VERSION "DNNBNNNYNNNNNNNNNNNNNNNNNNNNNNNNNNNNNNNNNN/4/%%%/4/'%**4NNN///"

NS_ :

BS_:

BU_: Vector__XXX SODX PC

BO_ 257 MBM_TARGET_DETECTION_HEADER: 8 SODX
 SG_ NumOfDetectionsTransmitted : 39|8@0+ (1,0) [0|99] ""  PC
 SG_ NumOfDetectionsInternal : 47|8@0+ (1,0) [0|127] ""  PC
 SG_ msg_count : 63|8@0+ (1,0) [0|0] ""  PC
 SG_ MCC : 7|32@0+ (1,0) [0|0] ""  PC
 SG_ InternalValue : 55|8@0+ (1,0) [0|0] ""  PC

BO_ 256 MB79_TARGET_DETECTION_TIME: 4 SODX
 SG_ TimeStamp : 7|32@0+ (1,0) [0|4294967295] "us"  PC

BO_ 293 MB79_TARGET_DETECTION_9D: 8 SODX
 SG_ Complex4_Re_9 : 39|16@0- (1,0) [-32768|32767] "n/a"  PC
 SG_ Complex4_Im_9 : 55|16@0- (1,0) [-32768|32767] "n/a"  PC
 SG_ Complex3_Re_9 : 7|16@0- (1,0) [-32768|32767] "n/a"  PC
 SG_ Complex3_Im_9 : 23|16@0- (1,0) [-32768|32767] "n/a"  PC

BO_ 292 MB79_TARGET_DETECTION_9C: 8 SODX
 SG_ Complex2_Re_9 : 39|16@0- (1,0) [-32768|32767] "n/a"  PC
 SG_ Complex2_Im_9 : 55|16@0- (1,0) [-32768|32767] "n/a"  PC
 SG_ Complex1_Re_9 : 7|16@0- (1,0) [-32768|32767] "n/a"  PC
 SG_ Complex1_Im_9 : 23|16@0- (1,0) [-32768|32767] "n/a"  PC

BO_ 291 MB79_TARGET_DETECTION_9B: 8 SODX
 SG_ StdAzimuth_9 : 63|8@0+ (0.0009766,0) [0|14.31] "°"  PC
 SG_ PowerDB_9 : 7|8@0+ (1,0) [0|255] "db"  PC
 SG_ CoGRange_9 : 15|16@0- (0.01,0) [0|96] "m"  PC
 SG_ CoGDoppler_9 : 31|16@0- (0.01,0) [-140|14] "m/s"  PC
 SG_ Azimuth_9 : 47|16@0- (0.1,0) [-180|180] "°"  PC

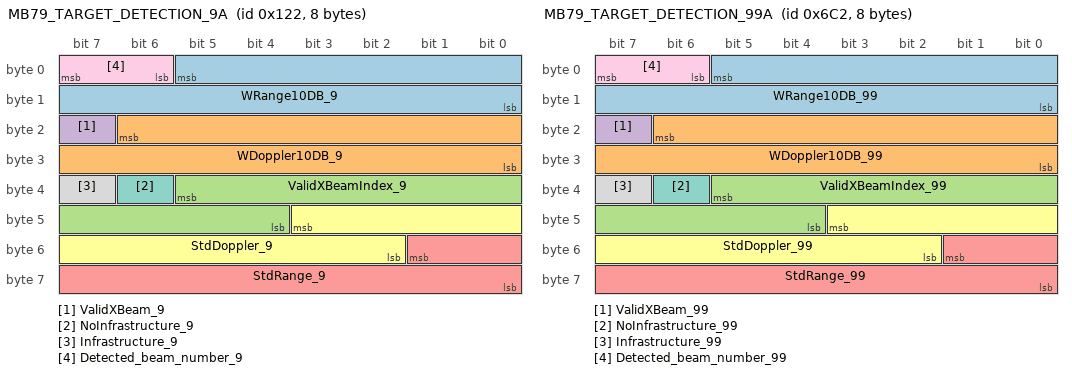
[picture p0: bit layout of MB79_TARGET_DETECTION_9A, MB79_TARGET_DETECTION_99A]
BO_ 290 MB79_TARGET_DETECTION_9A: 8 SODX
 SG_ WRange10DB_9 : 5|14@0+ (0.01,0) [0|96] "m"  PC
 SG_ WDoppler10DB_9 : 22|15@0+ (0.01,0) [0|280] "m/s"  PC
 SG_ ValidXBeamIndex_9 : 37|10@0+ (1,0) [0|0] "n/a"  PC
 SG_ ValidXBeam_9 : 23|1@0+ (1,0) [0|0] "n/a"  PC
 SG_ StdRange_9 : 49|10@0+ (0.01,0) [0|10] "m"  PC
 SG_ StdDoppler_9 : 43|10@0+ (0.01,0) [0|10] "m/s"  PC
 SG_ NoInfrastructure_9 : 38|1@0+ (1,0) [0|0] "n/a"  PC
 SG_ Infrastructure_9 : 39|1@0+ (1,0) [0|0] "n/a"  PC
 SG_ Detected_beam_number_9 : 7|2@0+ (1,0) [0|0] "n/a"  PC

BO_ 1733 MB79_TARGET_DETECTION_99D: 8 SODX
 SG_ Complex4_Re_99 : 39|16@0- (1,0) [-32768|32767] "n/a"  PC
 SG_ Complex4_Im_99 : 55|16@0- (1,0) [-32768|32767] "n/a"  PC
 SG_ Complex3_Re_99 : 7|16@0- (1,0) [-32768|32767] "n/a"  PC
 SG_ Complex3_Im_99 : 23|16@0- (1,0) [-32768|32767] "n/a"  PC

BO_ 1732 MB79_TARGET_DETECTION_99C: 8 SODX
 SG_ Complex2_Re_99 : 39|16@0- (1,0) [-32768|32767] "n/a"  PC
 SG_ Complex2_Im_99 : 55|16@0- (1,0) [-32768|32767] "n/a"  PC
 SG_ Complex1_Re_99 : 7|16@0- (1,0) [-32768|32767] "n/a"  PC
 SG_ Complex1_Im_99 : 23|16@0- (1,0) [-32768|32767] "n/a"  PC

BO_ 1731 MB79_TARGET_DETECTION_99B: 8 SODX
 SG_ StdAzimuth_99 : 63|8@0+ (0.0009766,0) [0|14.31] "°"  PC
 SG_ PowerDB_99 : 7|8@0+ (1,0) [0|255] "db"  PC
 SG_ CoGRange_99 : 15|16@0- (0.01,0) [0|96] "m"  PC
 SG_ CoGDoppler_99 : 31|16@0- (0.01,0) [-140|14] "m/s"  PC
 SG_ Azimuth_99 : 47|16@0- (0.1,0) [-180|180] "°"  PC

BO_ 1730 MB79_TARGET_DETECTION_99A: 8 SODX
 SG_ WRange10DB_99 : 5|14@0+ (0.01,0) [0|96] "m"  PC
 SG_ WDoppler10DB_99 : 22|15@0+ (0.01,0) [0|280] "m/s"  PC
 SG_ ValidXBeamIndex_99 : 37|10@0+ (1,0) [0|0] "n/a"  PC
 SG_ ValidXBeam_99 : 23|1@0+ (1,0) [0|0] "n/a"  PC
 SG_ StdRange_99 : 49|10@0+ (0.01,0) [0|10] "m"  PC
 SG_ StdDoppler_99 : 43|10@0+ (0.01,0) [0|10] "m/s"  PC
 SG_ NoInfrastructure_99 : 38|1@0+ (1,0) [0|0] "n/a"  PC
 SG_ Infrastructure_99 : 39|1@0+ (1,0) [0|0] "n/a"  PC
 SG_ Detected_beam_number_99 : 7|2@0+ (1,0) [0|0] "n/a"  PC

BO_ 1729 MB79_TARGET_DETECTION_98D: 8 SODX
 SG_ Complex4_Re_98 : 39|16@0- (1,0) [-32768|32767] "n/a"  PC
 SG_ Complex4_Im_98 : 55|16@0- (1,0) [-32768|32767] "n/a"  PC
 SG_ Complex3_Re_98 : 7|16@0- (1,0) [-32768|32767] "n/a"  PC
 SG_ Complex3_Im_98 : 23|16@0- (1,0) [-32768|32767] "n/a"  PC

BO_ 1728 MB79_TARGET_DETECTION_98C: 8 SODX
 SG_ Complex2_Re_98 : 39|16@0- (1,0) [-32768|32767] "n/a"  PC
 SG_ Complex2_Im_98 : 55|16@0- (1,0) [-32768|32767] "n/a"  PC
 SG_ Complex1_Re_98 : 7|16@0- (1,0) [-32768|32767] "n/a"  PC
 SG_ Complex1_Im_98 : 23|16@0- (1,0) [-32768|32767] "n/a"  PC

BO_ 1727 MB79_TARGET_DETECTION_98B: 8 SODX
 SG_ StdAzimuth_98 : 63|8@0+ (0.0009766,0) [0|14.31] "°"  PC
 SG_ PowerDB_98 : 7|8@0+ (1,0) [0|255] "db"  PC
 SG_ CoGRange_98 : 15|16@0- (0.01,0) [0|96] "m"  PC
 SG_ CoGDoppler_98 : 31|16@0- (0.01,0) [-140|14] "m/s"  PC
 SG_ Azimuth_98 : 47|16@0- (0.1,0) [-180|180] "°"  PC

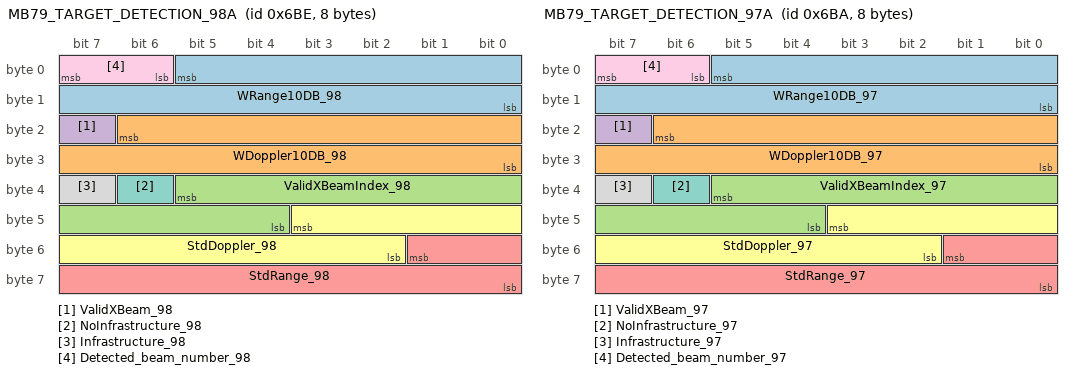
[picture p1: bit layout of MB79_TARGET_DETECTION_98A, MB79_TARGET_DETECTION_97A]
BO_ 1726 MB79_TARGET_DETECTION_98A: 8 SODX
 SG_ WRange10DB_98 : 5|14@0+ (0.01,0) [0|96] "m"  PC
 SG_ WDoppler10DB_98 : 22|15@0+ (0.01,0) [0|280] "m/s"  PC
 SG_ ValidXBeamIndex_98 : 37|10@0+ (1,0) [0|0] "n/a"  PC
 SG_ ValidXBeam_98 : 23|1@0+ (1,0) [0|0] "n/a"  PC
 SG_ StdRange_98 : 49|10@0+ (0.01,0) [0|10] "m"  PC
 SG_ StdDoppler_98 : 43|10@0+ (0.01,0) [0|10] "m/s"  PC
 SG_ NoInfrastructure_98 : 38|1@0+ (1,0) [0|0] "n/a"  PC
 SG_ Infrastructure_98 : 39|1@0+ (1,0) [0|0] "n/a"  PC
 SG_ Detected_beam_number_98 : 7|2@0+ (1,0) [0|0] "n/a"  PC

BO_ 1725 MB79_TARGET_DETECTION_97D: 8 SODX
 SG_ Complex4_Re_97 : 39|16@0- (1,0) [-32768|32767] "n/a"  PC
 SG_ Complex4_Im_97 : 55|16@0- (1,0) [-32768|32767] "n/a"  PC
 SG_ Complex3_Re_97 : 7|16@0- (1,0) [-32768|32767] "n/a"  PC
 SG_ Complex3_Im_97 : 23|16@0- (1,0) [-32768|32767] "n/a"  PC

BO_ 1724 MB79_TARGET_DETECTION_97C: 8 SODX
 SG_ Complex2_Re_97 : 39|16@0- (1,0) [-32768|32767] "n/a"  PC
 SG_ Complex2_Im_97 : 55|16@0- (1,0) [-32768|32767] "n/a"  PC
 SG_ Complex1_Re_97 : 7|16@0- (1,0) [-32768|32767] "n/a"  PC
 SG_ Complex1_Im_97 : 23|16@0- (1,0) [-32768|32767] "n/a"  PC

BO_ 1723 MB79_TARGET_DETECTION_97B: 8 SODX
 SG_ StdAzimuth_97 : 63|8@0+ (0.0009766,0) [0|14.31] "°"  PC
 SG_ PowerDB_97 : 7|8@0+ (1,0) [0|255] "db"  PC
 SG_ CoGRange_97 : 15|16@0- (0.01,0) [0|96] "m"  PC
 SG_ CoGDoppler_97 : 31|16@0- (0.01,0) [-140|14] "m/s"  PC
 SG_ Azimuth_97 : 47|16@0- (0.1,0) [-180|180] "°"  PC

BO_ 1722 MB79_TARGET_DETECTION_97A: 8 SODX
 SG_ WRange10DB_97 : 5|14@0+ (0.01,0) [0|96] "m"  PC
 SG_ WDoppler10DB_97 : 22|15@0+ (0.01,0) [0|280] "m/s"  PC
 SG_ ValidXBeamIndex_97 : 37|10@0+ (1,0) [0|0] "n/a"  PC
 SG_ ValidXBeam_97 : 23|1@0+ (1,0) [0|0] "n/a"  PC
 SG_ StdRange_97 : 49|10@0+ (0.01,0) [0|10] "m"  PC
 SG_ StdDoppler_97 : 43|10@0+ (0.01,0) [0|10] "m/s"  PC
 SG_ NoInfrastructure_97 : 38|1@0+ (1,0) [0|0] "n/a"  PC
 SG_ Infrastructure_97 : 39|1@0+ (1,0) [0|0] "n/a"  PC
 SG_ Detected_beam_number_97 : 7|2@0+ (1,0) [0|0] "n/a"  PC

BO_ 1721 MB79_TARGET_DETECTION_96D: 8 SODX
 SG_ Complex4_Re_96 : 39|16@0- (1,0) [-32768|32767] "n/a"  PC
 SG_ Complex4_Im_96 : 55|16@0- (1,0) [-32768|32767] "n/a"  PC
 SG_ Complex3_Re_96 : 7|16@0- (1,0) [-32768|32767] "n/a"  PC
 SG_ Complex3_Im_96 : 23|16@0- (1,0) [-32768|32767] "n/a"  PC

BO_ 1720 MB79_TARGET_DETECTION_96C: 8 SODX
 SG_ Complex2_Re_96 : 39|16@0- (1,0) [-32768|32767] "n/a"  PC
 SG_ Complex2_Im_96 : 55|16@0- (1,0) [-32768|32767] "n/a"  PC
 SG_ Complex1_Re_96 : 7|16@0- (1,0) [-32768|32767] "n/a"  PC
 SG_ Complex1_Im_96 : 23|16@0- (1,0) [-32768|32767] "n/a"  PC

BO_ 1719 MB79_TARGET_DETECTION_96B: 8 SODX
 SG_ StdAzimuth_96 : 63|8@0+ (0.0009766,0) [0|14.31] "°"  PC
 SG_ PowerDB_96 : 7|8@0+ (1,0) [0|255] "db"  PC
 SG_ CoGRange_96 : 15|16@0- (0.01,0) [0|96] "m"  PC
 SG_ CoGDoppler_96 : 31|16@0- (0.01,0) [-140|14] "m/s"  PC
 SG_ Azimuth_96 : 47|16@0- (0.1,0) [-180|180] "°"  PC

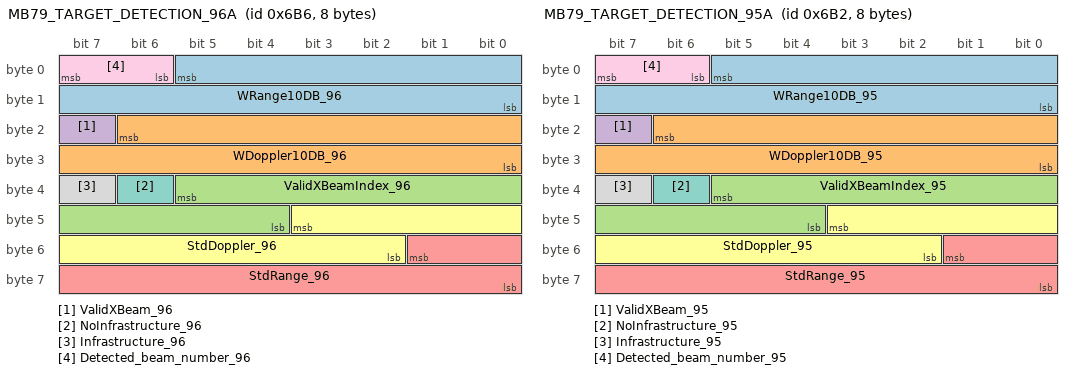
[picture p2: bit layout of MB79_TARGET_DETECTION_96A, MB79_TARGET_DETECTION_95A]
BO_ 1718 MB79_TARGET_DETECTION_96A: 8 SODX
 SG_ WRange10DB_96 : 5|14@0+ (1,0) [0|0] "cm"  PC
 SG_ WDoppler10DB_96 : 22|15@0+ (0.01,0) [0|280] "m/s"  PC
 SG_ ValidXBeamIndex_96 : 37|10@0+ (1,0) [0|0] "n/a"  PC
 SG_ ValidXBeam_96 : 23|1@0+ (1,0) [0|0] "n/a"  PC
 SG_ StdRange_96 : 49|10@0+ (0.01,0) [0|10] "m"  PC
 SG_ StdDoppler_96 : 43|10@0+ (0.01,0) [0|10] "m/s"  PC
 SG_ NoInfrastructure_96 : 38|1@0+ (1,0) [0|0] "n/a"  PC
 SG_ Infrastructure_96 : 39|1@0+ (1,0) [0|0] "n/a"  PC
 SG_ Detected_beam_number_96 : 7|2@0+ (1,0) [0|0] "n/a"  PC

BO_ 1717 MB79_TARGET_DETECTION_95D: 8 SODX
 SG_ Complex4_Re_95 : 39|16@0- (1,0) [-32768|32767] "n/a"  PC
 SG_ Complex4_Im_95 : 55|16@0- (1,0) [-32768|32767] "n/a"  PC
 SG_ Complex3_Re_95 : 7|16@0- (1,0) [-32768|32767] "n/a"  PC
 SG_ Complex3_Im_95 : 23|16@0- (1,0) [-32768|32767] "n/a"  PC

BO_ 1716 MB79_TARGET_DETECTION_95C: 8 SODX
 SG_ Complex2_Re_95 : 39|16@0- (1,0) [-32768|32767] "n/a"  PC
 SG_ Complex2_Im_95 : 55|16@0- (1,0) [-32768|32767] "n/a"  PC
 SG_ Complex1_Re_95 : 7|16@0- (1,0) [-32768|32767] "n/a"  PC
 SG_ Complex1_Im_95 : 23|16@0- (1,0) [-32768|32767] "n/a"  PC

BO_ 1715 MB79_TARGET_DETECTION_95B: 8 SODX
 SG_ StdAzimuth_95 : 63|8@0+ (0.0009766,0) [0|14.31] "°"  PC
 SG_ PowerDB_95 : 7|8@0+ (1,0) [0|255] "db"  PC
 SG_ CoGRange_95 : 15|16@0- (0.01,0) [0|96] "m"  PC
 SG_ CoGDoppler_95 : 31|16@0- (0.01,0) [-140|14] "m/s"  PC
 SG_ Azimuth_95 : 47|16@0- (0.1,0) [-180|180] "°"  PC

BO_ 1714 MB79_TARGET_DETECTION_95A: 8 SODX
 SG_ WRange10DB_95 : 5|14@0+ (0.01,0) [0|96] "m"  PC
 SG_ WDoppler10DB_95 : 22|15@0+ (0.01,0) [0|280] "m/s"  PC
 SG_ ValidXBeamIndex_95 : 37|10@0+ (1,0) [0|0] "n/a"  PC
 SG_ ValidXBeam_95 : 23|1@0+ (1,0) [0|0] "n/a"  PC
 SG_ StdRange_95 : 49|10@0+ (0.01,0) [0|10] "m"  PC
 SG_ StdDoppler_95 : 43|10@0+ (0.01,0) [0|10] "m/s"  PC
 SG_ NoInfrastructure_95 : 38|1@0+ (1,0) [0|0] "n/a"  PC
 SG_ Infrastructure_95 : 39|1@0+ (1,0) [0|0] "n/a"  PC
 SG_ Detected_beam_number_95 : 7|2@0+ (1,0) [0|0] "n/a"  PC

BO_ 1713 MB79_TARGET_DETECTION_94D: 8 SODX
 SG_ Complex4_Re_94 : 39|16@0- (1,0) [-32768|32767] "n/a"  PC
 SG_ Complex4_Im_94 : 55|16@0- (1,0) [-32768|32767] "n/a"  PC
 SG_ Complex3_Re_94 : 7|16@0- (1,0) [-32768|32767] "n/a"  PC
 SG_ Complex3_Im_94 : 23|16@0- (1,0) [-32768|32767] "n/a"  PC

BO_ 1712 MB79_TARGET_DETECTION_94C: 8 SODX
 SG_ Complex2_Re_94 : 39|16@0- (1,0) [-32768|32767] "n/a"  PC
 SG_ Complex2_Im_94 : 55|16@0- (1,0) [-32768|32767] "n/a"  PC
 SG_ Complex1_Re_94 : 7|16@0- (1,0) [-32768|32767] "n/a"  PC
 SG_ Complex1_Im_94 : 23|16@0- (1,0) [-32768|32767] "n/a"  PC

BO_ 1711 MB79_TARGET_DETECTION_94B: 8 SODX
 SG_ StdAzimuth_94 : 63|8@0+ (0.0009766,0) [0|14.31] "°"  PC
 SG_ PowerDB_94 : 7|8@0+ (1,0) [0|255] "db"  PC
 SG_ CoGRange_94 : 15|16@0- (0.01,0) [0|96] "m"  PC
 SG_ CoGDoppler_94 : 31|16@0- (0.01,0) [-140|14] "m/s"  PC
 SG_ Azimuth_94 : 47|16@0- (0.1,0) [-180|180] "°"  PC

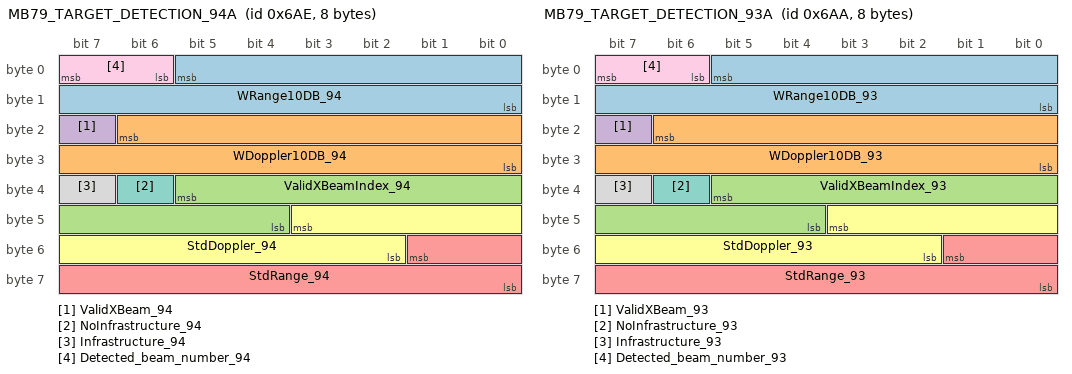
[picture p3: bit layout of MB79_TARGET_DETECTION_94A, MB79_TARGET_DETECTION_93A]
BO_ 1710 MB79_TARGET_DETECTION_94A: 8 SODX
 SG_ WRange10DB_94 : 5|14@0+ (0.01,0) [0|96] "m"  PC
 SG_ WDoppler10DB_94 : 22|15@0+ (0.01,0) [0|280] "m/s"  PC
 SG_ ValidXBeamIndex_94 : 37|10@0+ (1,0) [0|0] "n/a"  PC
 SG_ ValidXBeam_94 : 23|1@0+ (1,0) [0|0] "n/a"  PC
 SG_ StdRange_94 : 49|10@0+ (0.01,0) [0|10] "m"  PC
 SG_ StdDoppler_94 : 43|10@0+ (0.01,0) [0|10] "m/s"  PC
 SG_ NoInfrastructure_94 : 38|1@0+ (1,0) [0|0] "n/a"  PC
 SG_ Infrastructure_94 : 39|1@0+ (1,0) [0|0] "n/a"  PC
 SG_ Detected_beam_number_94 : 7|2@0+ (1,0) [0|0] "n/a"  PC

BO_ 1709 MB79_TARGET_DETECTION_93D: 8 SODX
 SG_ Complex4_Re_93 : 39|16@0- (1,0) [-32768|32767] "n/a"  PC
 SG_ Complex4_Im_93 : 55|16@0- (1,0) [-32768|32767] "n/a"  PC
 SG_ Complex3_Re_93 : 7|16@0- (1,0) [-32768|32767] "n/a"  PC
 SG_ Complex3_Im_93 : 23|16@0- (1,0) [-32768|32767] "n/a"  PC

BO_ 1708 MB79_TARGET_DETECTION_93C: 8 SODX
 SG_ Complex2_Re_93 : 39|16@0- (1,0) [-32768|32767] "n/a"  PC
 SG_ Complex2_Im_93 : 55|16@0- (1,0) [-32768|32767] "n/a"  PC
 SG_ Complex1_Re_93 : 7|16@0- (1,0) [-32768|32767] "n/a"  PC
 SG_ Complex1_Im_93 : 23|16@0- (1,0) [-32768|32767] "n/a"  PC

BO_ 1707 MB79_TARGET_DETECTION_93B: 8 SODX
 SG_ StdAzimuth_93 : 63|8@0+ (0.0009766,0) [0|14.31] "°"  PC
 SG_ PowerDB_93 : 7|8@0+ (1,0) [0|255] "db"  PC
 SG_ CoGRange_93 : 15|16@0- (0.01,0) [0|96] "m"  PC
 SG_ CoGDoppler_93 : 31|16@0- (0.01,0) [-140|14] "m/s"  PC
 SG_ Azimuth_93 : 47|16@0- (0.1,0) [-180|180] "°"  PC

BO_ 1706 MB79_TARGET_DETECTION_93A: 8 SODX
 SG_ WRange10DB_93 : 5|14@0+ (0.01,0) [0|96] "m"  PC
 SG_ WDoppler10DB_93 : 22|15@0+ (0.01,0) [0|280] "m/s"  PC
 SG_ ValidXBeamIndex_93 : 37|10@0+ (1,0) [0|0] "n/a"  PC
 SG_ ValidXBeam_93 : 23|1@0+ (1,0) [0|0] "n/a"  PC
 SG_ StdRange_93 : 49|10@0+ (0.01,0) [0|10] "m"  PC
 SG_ StdDoppler_93 : 43|10@0+ (0.01,0) [0|10] "m/s"  PC
 SG_ NoInfrastructure_93 : 38|1@0+ (1,0) [0|0] "n/a"  PC
 SG_ Infrastructure_93 : 39|1@0+ (1,0) [0|0] "n/a"  PC
 SG_ Detected_beam_number_93 : 7|2@0+ (1,0) [0|0] "n/a"  PC

BO_ 1705 MB79_TARGET_DETECTION_92D: 8 SODX
 SG_ Complex4_Re_92 : 39|16@0- (1,0) [-32768|32767] "n/a"  PC
 SG_ Complex4_Im_92 : 55|16@0- (1,0) [-32768|32767] "n/a"  PC
 SG_ Complex3_Re_92 : 7|16@0- (1,0) [-32768|32767] "n/a"  PC
 SG_ Complex3_Im_92 : 23|16@0- (1,0) [-32768|32767] "n/a"  PC

BO_ 1704 MB79_TARGET_DETECTION_92C: 8 SODX
 SG_ Complex2_Re_92 : 39|16@0- (1,0) [-32768|32767] "n/a"  PC
 SG_ Complex2_Im_92 : 55|16@0- (1,0) [-32768|32767] "n/a"  PC
 SG_ Complex1_Re_92 : 7|16@0- (1,0) [-32768|32767] "n/a"  PC
 SG_ Complex1_Im_92 : 23|16@0- (1,0) [-32768|32767] "n/a"  PC

BO_ 1703 MB79_TARGET_DETECTION_92B: 8 SODX
 SG_ StdAzimuth_92 : 63|8@0+ (0.0009766,0) [0|14.31] "°"  PC
 SG_ PowerDB_92 : 7|8@0+ (1,0) [0|255] "db"  PC
 SG_ CoGRange_92 : 15|16@0- (0.01,0) [0|96] "m"  PC
 SG_ CoGDoppler_92 : 31|16@0- (0.01,0) [-140|14] "m/s"  PC
 SG_ Azimuth_92 : 47|16@0- (0.1,0) [-180|180] "°"  PC

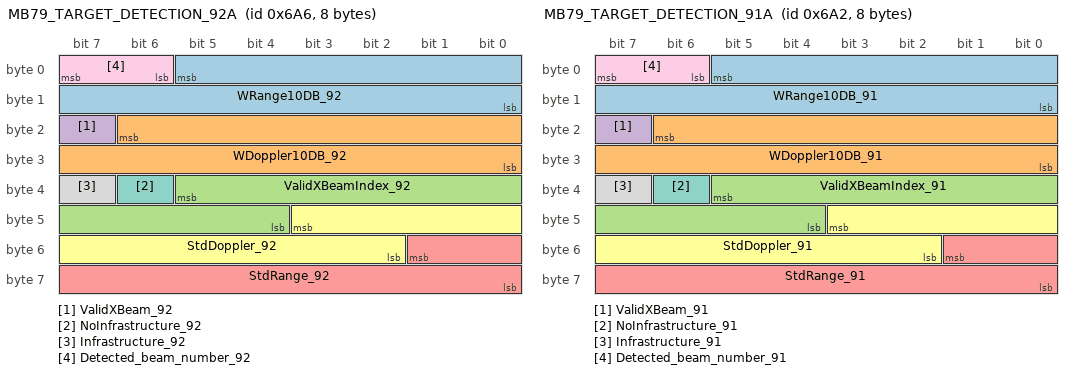
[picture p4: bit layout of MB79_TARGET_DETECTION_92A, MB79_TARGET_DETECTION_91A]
BO_ 1702 MB79_TARGET_DETECTION_92A: 8 SODX
 SG_ WRange10DB_92 : 5|14@0+ (0.01,0) [0|96] "m"  PC
 SG_ WDoppler10DB_92 : 22|15@0+ (0.01,0) [0|280] "m/s"  PC
 SG_ ValidXBeamIndex_92 : 37|10@0+ (1,0) [0|0] "n/a"  PC
 SG_ ValidXBeam_92 : 23|1@0+ (1,0) [0|0] "n/a"  PC
 SG_ StdRange_92 : 49|10@0+ (0.01,0) [0|10] "m"  PC
 SG_ StdDoppler_92 : 43|10@0+ (0.01,0) [0|10] "m/s"  PC
 SG_ NoInfrastructure_92 : 38|1@0+ (1,0) [0|0] "n/a"  PC
 SG_ Infrastructure_92 : 39|1@0+ (1,0) [0|0] "n/a"  PC
 SG_ Detected_beam_number_92 : 7|2@0+ (1,0) [0|0] "n/a"  PC

BO_ 1701 MB79_TARGET_DETECTION_91D: 8 SODX
 SG_ Complex4_Re_91 : 39|16@0- (1,0) [-32768|32767] "n/a"  PC
 SG_ Complex4_Im_91 : 55|16@0- (1,0) [-32768|32767] "n/a"  PC
 SG_ Complex3_Re_91 : 7|16@0- (1,0) [-32768|32767] "n/a"  PC
 SG_ Complex3_Im_91 : 23|16@0- (1,0) [-32768|32767] "n/a"  PC

BO_ 1700 MB79_TARGET_DETECTION_91C: 8 SODX
 SG_ Complex2_Re_91 : 39|16@0- (1,0) [-32768|32767] "n/a"  PC
 SG_ Complex2_Im_91 : 55|16@0- (1,0) [-32768|32767] "n/a"  PC
 SG_ Complex1_Re_91 : 7|16@0- (1,0) [-32768|32767] "n/a"  PC
 SG_ Complex1_Im_91 : 23|16@0- (1,0) [-32768|32767] "n/a"  PC

BO_ 1699 MB79_TARGET_DETECTION_91B: 8 SODX
 SG_ StdAzimuth_91 : 63|8@0+ (0.0009766,0) [0|14.31] "°"  PC
 SG_ PowerDB_91 : 7|8@0+ (1,0) [0|255] "db"  PC
 SG_ CoGRange_91 : 15|16@0- (0.01,0) [0|96] "m"  PC
 SG_ CoGDoppler_91 : 31|16@0- (0.01,0) [-140|14] "m/s"  PC
 SG_ Azimuth_91 : 47|16@0- (0.1,0) [-180|180] "°"  PC

BO_ 1698 MB79_TARGET_DETECTION_91A: 8 SODX
 SG_ WRange10DB_91 : 5|14@0+ (0.01,0) [0|96] "m"  PC
 SG_ WDoppler10DB_91 : 22|15@0+ (0.01,0) [0|280] "m/s"  PC
 SG_ ValidXBeamIndex_91 : 37|10@0+ (1,0) [0|0] "n/a"  PC
 SG_ ValidXBeam_91 : 23|1@0+ (1,0) [0|0] "n/a"  PC
 SG_ StdRange_91 : 49|10@0+ (0.01,0) [0|10] "m"  PC
 SG_ StdDoppler_91 : 43|10@0+ (0.01,0) [0|10] "m/s"  PC
 SG_ NoInfrastructure_91 : 38|1@0+ (1,0) [0|0] "n/a"  PC
 SG_ Infrastructure_91 : 39|1@0+ (1,0) [0|0] "n/a"  PC
 SG_ Detected_beam_number_91 : 7|2@0+ (1,0) [0|0] "n/a"  PC

BO_ 1697 MB79_TARGET_DETECTION_90D: 8 SODX
 SG_ Complex4_Re_90 : 39|16@0- (1,0) [-32768|32767] "n/a"  PC
 SG_ Complex4_Im_90 : 55|16@0- (1,0) [-32768|32767] "n/a"  PC
 SG_ Complex3_Re_90 : 7|16@0- (1,0) [-32768|32767] "n/a"  PC
 SG_ Complex3_Im_90 : 23|16@0- (1,0) [-32768|32767] "n/a"  PC

BO_ 1696 MB79_TARGET_DETECTION_90C: 8 SODX
 SG_ Complex2_Re_90 : 39|16@0- (1,0) [-32768|32767] "n/a"  PC
 SG_ Complex2_Im_90 : 55|16@0- (1,0) [-32768|32767] "n/a"  PC
 SG_ Complex1_Re_90 : 7|16@0- (1,0) [-32768|32767] "n/a"  PC
 SG_ Complex1_Im_90 : 23|16@0- (1,0) [-32768|32767] "n/a"  PC

BO_ 1695 MB79_TARGET_DETECTION_90B: 8 SODX
 SG_ StdAzimuth_90 : 63|8@0+ (0.0009766,0) [0|14.31] "°"  PC
 SG_ PowerDB_90 : 7|8@0+ (1,0) [0|255] "db"  PC
 SG_ CoGRange_90 : 15|16@0- (0.01,0) [0|96] "m"  PC
 SG_ CoGDoppler_90 : 31|16@0- (0.01,0) [-140|14] "m/s"  PC
 SG_ Azimuth_90 : 47|16@0- (0.1,0) [-180|180] "°"  PC

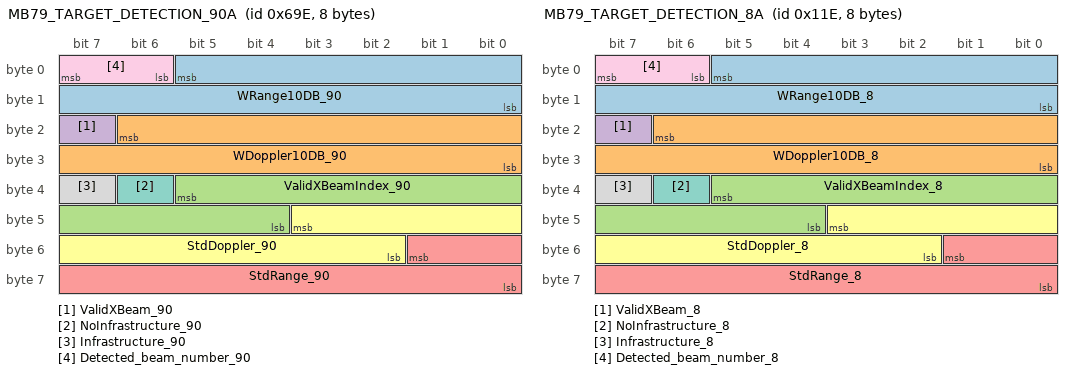
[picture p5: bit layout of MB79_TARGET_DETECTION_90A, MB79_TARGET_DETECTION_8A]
BO_ 1694 MB79_TARGET_DETECTION_90A: 8 SODX
 SG_ WRange10DB_90 : 5|14@0+ (0.01,0) [0|96] "m"  PC
 SG_ WDoppler10DB_90 : 22|15@0+ (0.01,0) [0|280] "m/s"  PC
 SG_ ValidXBeamIndex_90 : 37|10@0+ (1,0) [0|0] "n/a"  PC
 SG_ ValidXBeam_90 : 23|1@0+ (1,0) [0|0] "n/a"  PC
 SG_ StdRange_90 : 49|10@0+ (0.01,0) [0|10] "m"  PC
 SG_ StdDoppler_90 : 43|10@0+ (0.01,0) [0|10] "m/s"  PC
 SG_ NoInfrastructure_90 : 38|1@0+ (1,0) [0|0] "n/a"  PC
 SG_ Infrastructure_90 : 39|1@0+ (1,0) [0|0] "n/a"  PC
 SG_ Detected_beam_number_90 : 7|2@0+ (1,0) [0|0] "n/a"  PC

BO_ 289 MB79_TARGET_DETECTION_8D: 8 SODX
 SG_ Complex4_Re_8 : 39|16@0- (1,0) [-32768|32767] "n/a"  PC
 SG_ Complex4_Im_8 : 55|16@0- (1,0) [-32768|32767] "n/a"  PC
 SG_ Complex3_Re_8 : 7|16@0- (1,0) [-32768|32767] "n/a"  PC
 SG_ Complex3_Im_8 : 23|16@0- (1,0) [-32768|32767] "n/a"  PC

BO_ 288 MB79_TARGET_DETECTION_8C: 8 SODX
 SG_ Complex2_Re_8 : 39|16@0- (1,0) [-32768|32767] "n/a"  PC
 SG_ Complex2_Im_8 : 55|16@0- (1,0) [-32768|32767] "n/a"  PC
 SG_ Complex1_Re_8 : 7|16@0- (1,0) [-32768|32767] "n/a"  PC
 SG_ Complex1_Im_8 : 23|16@0- (1,0) [-32768|32767] "n/a"  PC

BO_ 287 MB79_TARGET_DETECTION_8B: 8 SODX
 SG_ StdAzimuth_8 : 63|8@0+ (0.0009766,0) [0|14.31] "°"  PC
 SG_ PowerDB_8 : 7|8@0+ (1,0) [0|255] "db"  PC
 SG_ CoGRange_8 : 15|16@0- (0.01,0) [0|96] "m"  PC
 SG_ CoGDoppler_8 : 31|16@0- (0.01,0) [-140|14] "m/s"  PC
 SG_ Azimuth_8 : 47|16@0- (0.1,0) [-180|180] "°"  PC

BO_ 286 MB79_TARGET_DETECTION_8A: 8 SODX
 SG_ WRange10DB_8 : 5|14@0+ (0.01,0) [0|96] "m"  PC
 SG_ WDoppler10DB_8 : 22|15@0+ (0.01,0) [0|280] "m/s"  PC
 SG_ ValidXBeamIndex_8 : 37|10@0+ (1,0) [0|0] "n/a"  PC
 SG_ ValidXBeam_8 : 23|1@0+ (1,0) [0|0] "n/a"  PC
 SG_ StdRange_8 : 49|10@0+ (0.01,0) [0|10] "m"  PC
 SG_ StdDoppler_8 : 43|10@0+ (0.01,0) [0|10] "m/s"  PC
 SG_ NoInfrastructure_8 : 38|1@0+ (1,0) [0|0] "n/a"  PC
 SG_ Infrastructure_8 : 39|1@0+ (1,0) [0|0] "n/a"  PC
 SG_ Detected_beam_number_8 : 7|2@0+ (1,0) [0|0] "n/a"  PC

BO_ 1693 MB79_TARGET_DETECTION_89D: 8 SODX
 SG_ Complex4_Re_89 : 39|16@0- (1,0) [-32768|32767] "n/a"  PC
 SG_ Complex4_Im_89 : 55|16@0- (1,0) [-32768|32767] "n/a"  PC
 SG_ Complex3_Re_89 : 7|16@0- (1,0) [-32768|32767] "n/a"  PC
 SG_ Complex3_Im_89 : 23|16@0- (1,0) [-32768|32767] "n/a"  PC

BO_ 1692 MB79_TARGET_DETECTION_89C: 8 SODX
 SG_ Complex2_Re_89 : 39|16@0- (1,0) [-32768|32767] "n/a"  PC
 SG_ Complex2_Im_89 : 55|16@0- (1,0) [-32768|32767] "n/a"  PC
 SG_ Complex1_Re_89 : 7|16@0- (1,0) [-32768|32767] "n/a"  PC
 SG_ Complex1_Im_89 : 23|16@0- (1,0) [-32768|32767] "n/a"  PC

BO_ 1691 MB79_TARGET_DETECTION_89B: 8 SODX
 SG_ StdAzimuth_89 : 63|8@0+ (0.0009766,0) [0|14.31] "°"  PC
 SG_ PowerDB_89 : 7|8@0+ (1,0) [0|255] "db"  PC
 SG_ CoGRange_89 : 15|16@0- (0.01,0) [0|96] "m"  PC
 SG_ CoGDoppler_89 : 31|16@0- (0.01,0) [-140|14] "m/s"  PC
 SG_ Azimuth_89 : 47|16@0- (0.1,0) [-180|180] "°"  PC

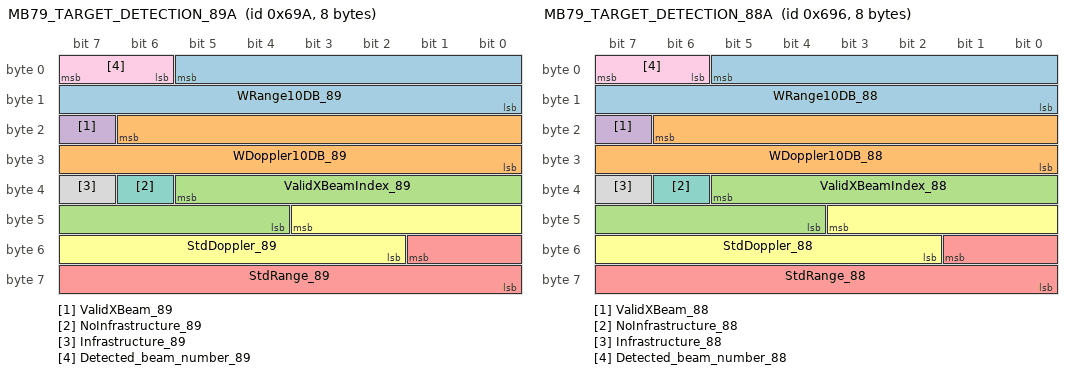
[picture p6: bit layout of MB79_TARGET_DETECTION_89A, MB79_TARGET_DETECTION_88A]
BO_ 1690 MB79_TARGET_DETECTION_89A: 8 SODX
 SG_ WRange10DB_89 : 5|14@0+ (0.01,0) [0|96] "m"  PC
 SG_ WDoppler10DB_89 : 22|15@0+ (0.01,0) [0|280] "m/s"  PC
 SG_ ValidXBeamIndex_89 : 37|10@0+ (1,0) [0|0] "n/a"  PC
 SG_ ValidXBeam_89 : 23|1@0+ (1,0) [0|0] "n/a"  PC
 SG_ StdRange_89 : 49|10@0+ (0.01,0) [0|10] "m"  PC
 SG_ StdDoppler_89 : 43|10@0+ (0.01,0) [0|10] "m/s"  PC
 SG_ NoInfrastructure_89 : 38|1@0+ (1,0) [0|0] "n/a"  PC
 SG_ Infrastructure_89 : 39|1@0+ (1,0) [0|0] "n/a"  PC
 SG_ Detected_beam_number_89 : 7|2@0+ (1,0) [0|0] "n/a"  PC

BO_ 1689 MB79_TARGET_DETECTION_88D: 8 SODX
 SG_ Complex4_Re_88 : 39|16@0- (1,0) [-32768|32767] "n/a"  PC
 SG_ Complex4_Im_88 : 55|16@0- (1,0) [-32768|32767] "n/a"  PC
 SG_ Complex3_Re_88 : 7|16@0- (1,0) [-32768|32767] "n/a"  PC
 SG_ Complex3_Im_88 : 23|16@0- (1,0) [-32768|32767] "n/a"  PC

BO_ 1688 MB79_TARGET_DETECTION_88C: 8 SODX
 SG_ Complex2_Re_88 : 39|16@0- (1,0) [-32768|32767] "n/a"  PC
 SG_ Complex2_Im_88 : 55|16@0- (1,0) [-32768|32767] "n/a"  PC
 SG_ Complex1_Re_88 : 7|16@0- (1,0) [-32768|32767] "n/a"  PC
 SG_ Complex1_Im_88 : 23|16@0- (1,0) [-32768|32767] "n/a"  PC

BO_ 1687 MB79_TARGET_DETECTION_88B: 8 SODX
 SG_ StdAzimuth_88 : 63|8@0+ (0.0009766,0) [0|14.31] "°"  PC
 SG_ PowerDB_88 : 7|8@0+ (1,0) [0|255] "db"  PC
 SG_ CoGRange_88 : 15|16@0- (0.01,0) [0|96] "m"  PC
 SG_ CoGDoppler_88 : 31|16@0- (0.01,0) [-140|14] "m/s"  PC
 SG_ Azimuth_88 : 47|16@0- (0.1,0) [-180|180] "°"  PC

BO_ 1686 MB79_TARGET_DETECTION_88A: 8 SODX
 SG_ WRange10DB_88 : 5|14@0+ (0.01,0) [0|96] "m"  PC
 SG_ WDoppler10DB_88 : 22|15@0+ (0.01,0) [0|280] "m/s"  PC
 SG_ ValidXBeamIndex_88 : 37|10@0+ (1,0) [0|0] "n/a"  PC
 SG_ ValidXBeam_88 : 23|1@0+ (1,0) [0|0] "n/a"  PC
 SG_ StdRange_88 : 49|10@0+ (0.01,0) [0|10] "m"  PC
 SG_ StdDoppler_88 : 43|10@0+ (0.01,0) [0|10] "m/s"  PC
 SG_ NoInfrastructure_88 : 38|1@0+ (1,0) [0|0] "n/a"  PC
 SG_ Infrastructure_88 : 39|1@0+ (1,0) [0|0] "n/a"  PC
 SG_ Detected_beam_number_88 : 7|2@0+ (1,0) [0|0] "n/a"  PC

BO_ 1685 MB79_TARGET_DETECTION_87D: 8 SODX
 SG_ Complex4_Re_87 : 39|16@0- (1,0) [-32768|32767] "n/a"  PC
 SG_ Complex4_Im_87 : 55|16@0- (1,0) [-32768|32767] "n/a"  PC
 SG_ Complex3_Re_87 : 7|16@0- (1,0) [-32768|32767] "n/a"  PC
 SG_ Complex3_Im_87 : 23|16@0- (1,0) [-32768|32767] "n/a"  PC

BO_ 1684 MB79_TARGET_DETECTION_87C: 8 SODX
 SG_ Complex2_Re_87 : 39|16@0- (1,0) [-32768|32767] "n/a"  PC
 SG_ Complex2_Im_87 : 55|16@0- (1,0) [-32768|32767] "n/a"  PC
 SG_ Complex1_Re_87 : 7|16@0- (1,0) [-32768|32767] "n/a"  PC
 SG_ Complex1_Im_87 : 23|16@0- (1,0) [-32768|32767] "n/a"  PC

BO_ 1683 MB79_TARGET_DETECTION_87B: 8 SODX
 SG_ StdAzimuth_87 : 63|8@0+ (0.0009766,0) [0|14.31] "°"  PC
 SG_ PowerDB_87 : 7|8@0+ (1,0) [0|255] "db"  PC
 SG_ CoGRange_87 : 15|16@0- (0.01,0) [0|96] "m"  PC
 SG_ CoGDoppler_87 : 31|16@0- (0.01,0) [-140|14] "m/s"  PC
 SG_ Azimuth_87 : 47|16@0- (0.1,0) [-180|180] "°"  PC

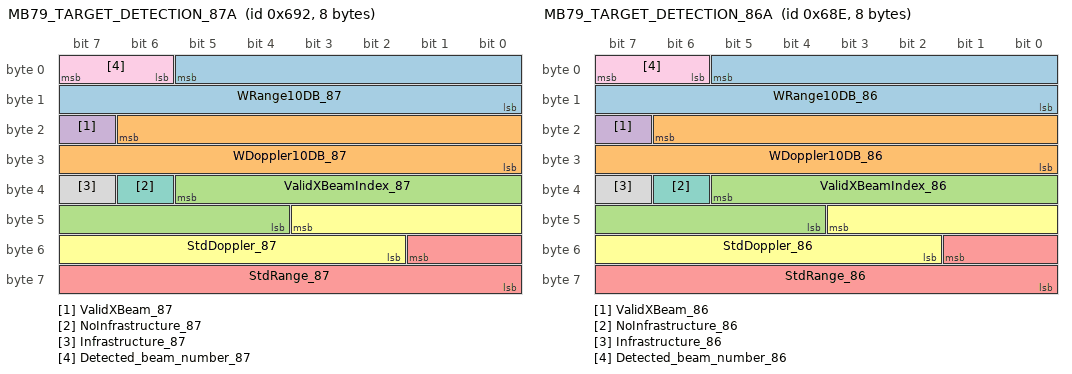
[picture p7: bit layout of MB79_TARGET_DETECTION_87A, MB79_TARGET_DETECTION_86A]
BO_ 1682 MB79_TARGET_DETECTION_87A: 8 SODX
 SG_ WRange10DB_87 : 5|14@0+ (0.01,0) [0|96] "m"  PC
 SG_ WDoppler10DB_87 : 22|15@0+ (0.01,0) [0|280] "m/s"  PC
 SG_ ValidXBeamIndex_87 : 37|10@0+ (1,0) [0|0] "n/a"  PC
 SG_ ValidXBeam_87 : 23|1@0+ (1,0) [0|0] "n/a"  PC
 SG_ StdRange_87 : 49|10@0+ (0.01,0) [0|10] "m"  PC
 SG_ StdDoppler_87 : 43|10@0+ (0.01,0) [0|10] "m/s"  PC
 SG_ NoInfrastructure_87 : 38|1@0+ (1,0) [0|0] "n/a"  PC
 SG_ Infrastructure_87 : 39|1@0+ (1,0) [0|0] "n/a"  PC
 SG_ Detected_beam_number_87 : 7|2@0+ (1,0) [0|0] "n/a"  PC

BO_ 1681 MB79_TARGET_DETECTION_86D: 8 SODX
 SG_ Complex4_Re_86 : 39|16@0- (1,0) [-32768|32767] "n/a"  PC
 SG_ Complex4_Im_86 : 55|16@0- (1,0) [-32768|32767] "n/a"  PC
 SG_ Complex3_Re_86 : 7|16@0- (1,0) [-32768|32767] "n/a"  PC
 SG_ Complex3_Im_86 : 23|16@0- (1,0) [-32768|32767] "n/a"  PC

BO_ 1680 MB79_TARGET_DETECTION_86C: 8 SODX
 SG_ Complex2_Re_86 : 39|16@0- (1,0) [-32768|32767] "n/a"  PC
 SG_ Complex2_Im_86 : 55|16@0- (1,0) [-32768|32767] "n/a"  PC
 SG_ Complex1_Re_86 : 7|16@0- (1,0) [-32768|32767] "n/a"  PC
 SG_ Complex1_Im_86 : 23|16@0- (1,0) [-32768|32767] "n/a"  PC

BO_ 1679 MB79_TARGET_DETECTION_86B: 8 SODX
 SG_ StdAzimuth_86 : 63|8@0+ (0.0009766,0) [0|14.31] "°"  PC
 SG_ PowerDB_86 : 7|8@0+ (1,0) [0|255] "db"  PC
 SG_ CoGRange_86 : 15|16@0- (0.01,0) [0|96] "m"  PC
 SG_ CoGDoppler_86 : 31|16@0- (0.01,0) [-140|14] "m/s"  PC
 SG_ Azimuth_86 : 47|16@0- (0.1,0) [-180|180] "°"  PC

BO_ 1678 MB79_TARGET_DETECTION_86A: 8 SODX
 SG_ WRange10DB_86 : 5|14@0+ (0.01,0) [0|96] "m"  PC
 SG_ WDoppler10DB_86 : 22|15@0+ (0.01,0) [0|280] "m/s"  PC
 SG_ ValidXBeamIndex_86 : 37|10@0+ (1,0) [0|0] "n/a"  PC
 SG_ ValidXBeam_86 : 23|1@0+ (1,0) [0|0] "n/a"  PC
 SG_ StdRange_86 : 49|10@0+ (0.01,0) [0|10] "m"  PC
 SG_ StdDoppler_86 : 43|10@0+ (0.01,0) [0|10] "m/s"  PC
 SG_ NoInfrastructure_86 : 38|1@0+ (1,0) [0|0] "n/a"  PC
 SG_ Infrastructure_86 : 39|1@0+ (1,0) [0|0] "n/a"  PC
 SG_ Detected_beam_number_86 : 7|2@0+ (1,0) [0|0] "n/a"  PC

BO_ 1677 MB79_TARGET_DETECTION_85D: 8 SODX
 SG_ Complex4_Re_85 : 39|16@0- (1,0) [-32768|32767] "n/a"  PC
 SG_ Complex4_Im_85 : 55|16@0- (1,0) [-32768|32767] "n/a"  PC
 SG_ Complex3_Re_85 : 7|16@0- (1,0) [-32768|32767] "n/a"  PC
 SG_ Complex3_Im_85 : 23|16@0- (1,0) [-32768|32767] "n/a"  PC

BO_ 1676 MB79_TARGET_DETECTION_85C: 8 SODX
 SG_ Complex2_Re_85 : 39|16@0- (1,0) [-32768|32767] "n/a"  PC
 SG_ Complex2_Im_85 : 55|16@0- (1,0) [-32768|32767] "n/a"  PC
 SG_ Complex1_Re_85 : 7|16@0- (1,0) [-32768|32767] "n/a"  PC
 SG_ Complex1_Im_85 : 23|16@0- (1,0) [-32768|32767] "n/a"  PC

BO_ 1675 MB79_TARGET_DETECTION_85B: 8 SODX
 SG_ StdAzimuth_85 : 63|8@0+ (0.0009766,0) [0|14.31] "°"  PC
 SG_ PowerDB_85 : 7|8@0+ (1,0) [0|255] "db"  PC
 SG_ CoGRange_85 : 15|16@0- (0.01,0) [0|96] "m"  PC
 SG_ CoGDoppler_85 : 31|16@0- (0.01,0) [-140|14] "m/s"  PC
 SG_ Azimuth_85 : 47|16@0- (0.1,0) [-180|180] "°"  PC

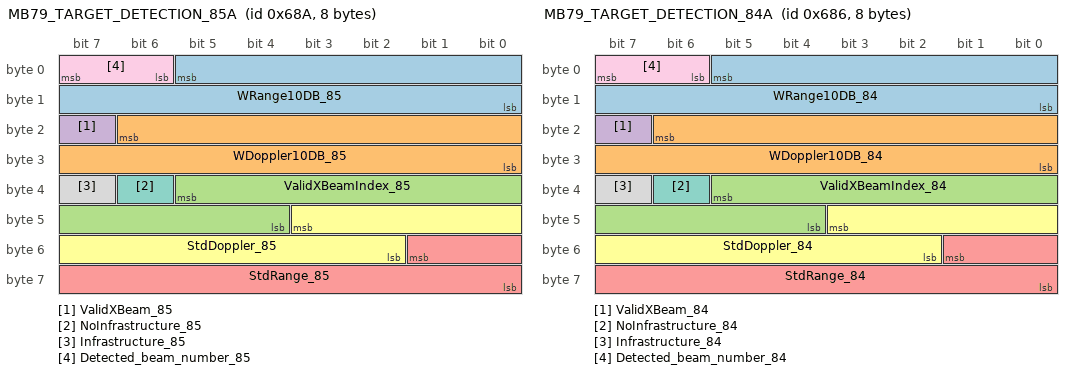
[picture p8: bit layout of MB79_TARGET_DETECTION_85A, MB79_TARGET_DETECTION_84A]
BO_ 1674 MB79_TARGET_DETECTION_85A: 8 SODX
 SG_ WRange10DB_85 : 5|14@0+ (0.01,0) [0|96] "m"  PC
 SG_ WDoppler10DB_85 : 22|15@0+ (0.01,0) [0|280] "m/s"  PC
 SG_ ValidXBeamIndex_85 : 37|10@0+ (1,0) [0|0] "n/a"  PC
 SG_ ValidXBeam_85 : 23|1@0+ (1,0) [0|0] "n/a"  PC
 SG_ StdRange_85 : 49|10@0+ (0.01,0) [0|10] "m"  PC
 SG_ StdDoppler_85 : 43|10@0+ (0.01,0) [0|10] "m/s"  PC
 SG_ NoInfrastructure_85 : 38|1@0+ (1,0) [0|0] "n/a"  PC
 SG_ Infrastructure_85 : 39|1@0+ (1,0) [0|0] "n/a"  PC
 SG_ Detected_beam_number_85 : 7|2@0+ (1,0) [0|0] "n/a"  PC

BO_ 1673 MB79_TARGET_DETECTION_84D: 8 SODX
 SG_ Complex4_Re_84 : 39|16@0- (1,0) [-32768|32767] "n/a"  PC
 SG_ Complex4_Im_84 : 55|16@0- (1,0) [-32768|32767] "n/a"  PC
 SG_ Complex3_Re_84 : 7|16@0- (1,0) [-32768|32767] "n/a"  PC
 SG_ Complex3_Im_84 : 23|16@0- (1,0) [-32768|32767] "n/a"  PC

BO_ 1672 MB79_TARGET_DETECTION_84C: 8 SODX
 SG_ Complex2_Re_84 : 39|16@0- (1,0) [-32768|32767] "n/a"  PC
 SG_ Complex2_Im_84 : 55|16@0- (1,0) [-32768|32767] "n/a"  PC
 SG_ Complex1_Re_84 : 7|16@0- (1,0) [-32768|32767] "n/a"  PC
 SG_ Complex1_Im_84 : 23|16@0- (1,0) [-32768|32767] "n/a"  PC

BO_ 1671 MB79_TARGET_DETECTION_84B: 8 SODX
 SG_ StdAzimuth_84 : 63|8@0+ (0.0009766,0) [0|14.31] "°"  PC
 SG_ PowerDB_84 : 7|8@0+ (1,0) [0|255] "db"  PC
 SG_ CoGRange_84 : 15|16@0- (0.01,0) [0|96] "m"  PC
 SG_ CoGDoppler_84 : 31|16@0- (0.01,0) [-140|14] "m/s"  PC
 SG_ Azimuth_84 : 47|16@0- (0.1,0) [-180|180] "°"  PC

BO_ 1670 MB79_TARGET_DETECTION_84A: 8 SODX
 SG_ WRange10DB_84 : 5|14@0+ (0.01,0) [0|96] "m"  PC
 SG_ WDoppler10DB_84 : 22|15@0+ (0.01,0) [0|280] "m/s"  PC
 SG_ ValidXBeamIndex_84 : 37|10@0+ (1,0) [0|0] "n/a"  PC
 SG_ ValidXBeam_84 : 23|1@0+ (1,0) [0|0] "n/a"  PC
 SG_ StdRange_84 : 49|10@0+ (0.01,0) [0|10] "m"  PC
 SG_ StdDoppler_84 : 43|10@0+ (0.01,0) [0|10] "m/s"  PC
 SG_ NoInfrastructure_84 : 38|1@0+ (1,0) [0|0] "n/a"  PC
 SG_ Infrastructure_84 : 39|1@0+ (1,0) [0|0] "n/a"  PC
 SG_ Detected_beam_number_84 : 7|2@0+ (1,0) [0|0] "n/a"  PC

BO_ 1669 MB79_TARGET_DETECTION_83D: 8 SODX
 SG_ Complex4_Re_83 : 39|16@0- (1,0) [-32768|32767] "n/a"  PC
 SG_ Complex4_Im_83 : 55|16@0- (1,0) [-32768|32767] "n/a"  PC
 SG_ Complex3_Re_83 : 7|16@0- (1,0) [-32768|32767] "n/a"  PC
 SG_ Complex3_Im_83 : 23|16@0- (1,0) [-32768|32767] "n/a"  PC

BO_ 1668 MB79_TARGET_DETECTION_83C: 8 SODX
 SG_ Complex2_Re_83 : 39|16@0- (1,0) [-32768|32767] "n/a"  PC
 SG_ Complex2_Im_83 : 55|16@0- (1,0) [-32768|32767] "n/a"  PC
 SG_ Complex1_Re_83 : 7|16@0- (1,0) [-32768|32767] "n/a"  PC
 SG_ Complex1_Im_83 : 23|16@0- (1,0) [-32768|32767] "n/a"  PC

BO_ 1667 MB79_TARGET_DETECTION_83B: 8 SODX
 SG_ StdAzimuth_83 : 63|8@0+ (0.0009766,0) [0|14.31] "°"  PC
 SG_ PowerDB_83 : 7|8@0+ (1,0) [0|255] "db"  PC
 SG_ CoGRange_83 : 15|16@0- (0.01,0) [0|96] "m"  PC
 SG_ CoGDoppler_83 : 31|16@0- (0.01,0) [-140|14] "m/s"  PC
 SG_ Azimuth_83 : 47|16@0- (0.1,0) [-180|180] "°"  PC

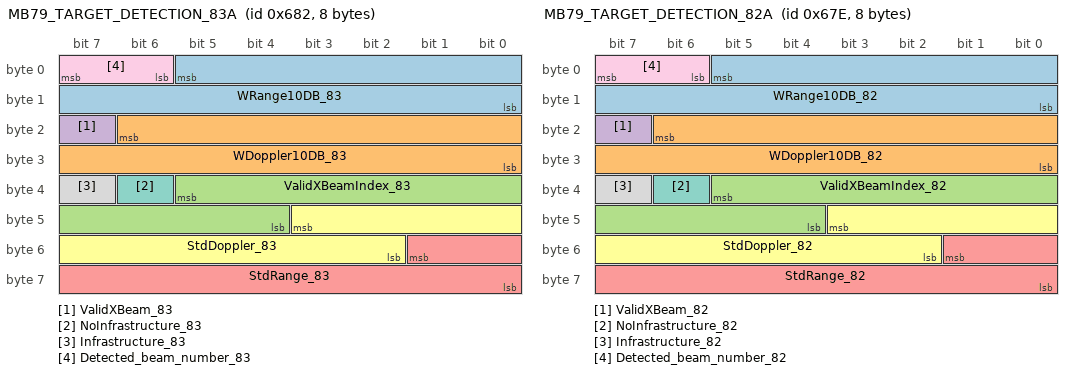
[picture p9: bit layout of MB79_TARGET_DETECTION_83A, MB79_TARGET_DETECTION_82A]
BO_ 1666 MB79_TARGET_DETECTION_83A: 8 SODX
 SG_ WRange10DB_83 : 5|14@0+ (0.01,0) [0|96] "m"  PC
 SG_ WDoppler10DB_83 : 22|15@0+ (0.01,0) [0|280] "m/s"  PC
 SG_ ValidXBeamIndex_83 : 37|10@0+ (1,0) [0|0] "n/a"  PC
 SG_ ValidXBeam_83 : 23|1@0+ (1,0) [0|0] "n/a"  PC
 SG_ StdRange_83 : 49|10@0+ (0.01,0) [0|10] "m"  PC
 SG_ StdDoppler_83 : 43|10@0+ (0.01,0) [0|10] "m/s"  PC
 SG_ NoInfrastructure_83 : 38|1@0+ (1,0) [0|0] "n/a"  PC
 SG_ Infrastructure_83 : 39|1@0+ (1,0) [0|0] "n/a"  PC
 SG_ Detected_beam_number_83 : 7|2@0+ (1,0) [0|0] "n/a"  PC

BO_ 1665 MB79_TARGET_DETECTION_82D: 8 SODX
 SG_ Complex4_Re_82 : 39|16@0- (1,0) [-32768|32767] "n/a"  PC
 SG_ Complex4_Im_82 : 55|16@0- (1,0) [-32768|32767] "n/a"  PC
 SG_ Complex3_Re_82 : 7|16@0- (1,0) [-32768|32767] "n/a"  PC
 SG_ Complex3_Im_82 : 23|16@0- (1,0) [-32768|32767] "n/a"  PC

BO_ 1664 MB79_TARGET_DETECTION_82C: 8 SODX
 SG_ Complex2_Re_82 : 39|16@0- (1,0) [-32768|32767] "n/a"  PC
 SG_ Complex2_Im_82 : 55|16@0- (1,0) [-32768|32767] "n/a"  PC
 SG_ Complex1_Re_82 : 7|16@0- (1,0) [-32768|32767] "n/a"  PC
 SG_ Complex1_Im_82 : 23|16@0- (1,0) [-32768|32767] "n/a"  PC

BO_ 1663 MB79_TARGET_DETECTION_82B: 8 SODX
 SG_ StdAzimuth_82 : 63|8@0+ (0.0009766,0) [0|14.31] "°"  PC
 SG_ PowerDB_82 : 7|8@0+ (1,0) [0|255] "db"  PC
 SG_ CoGRange_82 : 15|16@0- (0.01,0) [0|96] "m"  PC
 SG_ CoGDoppler_82 : 31|16@0- (0.01,0) [-140|14] "m/s"  PC
 SG_ Azimuth_82 : 47|16@0- (0.1,0) [-180|180] "°"  PC

BO_ 1662 MB79_TARGET_DETECTION_82A: 8 SODX
 SG_ WRange10DB_82 : 5|14@0+ (0.01,0) [0|96] "m"  PC
 SG_ WDoppler10DB_82 : 22|15@0+ (0.01,0) [0|280] "m/s"  PC
 SG_ ValidXBeamIndex_82 : 37|10@0+ (1,0) [0|0] "n/a"  PC
 SG_ ValidXBeam_82 : 23|1@0+ (1,0) [0|0] "n/a"  PC
 SG_ StdRange_82 : 49|10@0+ (0.01,0) [0|10] "m"  PC
 SG_ StdDoppler_82 : 43|10@0+ (0.01,0) [0|10] "m/s"  PC
 SG_ NoInfrastructure_82 : 38|1@0+ (1,0) [0|0] "n/a"  PC
 SG_ Infrastructure_82 : 39|1@0+ (1,0) [0|0] "n/a"  PC
 SG_ Detected_beam_number_82 : 7|2@0+ (1,0) [0|0] "n/a"  PC

BO_ 1661 MB79_TARGET_DETECTION_81D: 8 SODX
 SG_ Complex4_Re_81 : 39|16@0- (1,0) [-32768|32767] "n/a"  PC
 SG_ Complex4_Im_81 : 55|16@0- (1,0) [-32768|32767] "n/a"  PC
 SG_ Complex3_Re_81 : 7|16@0- (1,0) [-32768|32767] "n/a"  PC
 SG_ Complex3_Im_81 : 23|16@0- (1,0) [-32768|32767] "n/a"  PC

BO_ 1660 MB79_TARGET_DETECTION_81C: 8 SODX
 SG_ Complex2_Re_81 : 39|16@0- (1,0) [-32768|32767] "n/a"  PC
 SG_ Complex2_Im_81 : 55|16@0- (1,0) [-32768|32767] "n/a"  PC
 SG_ Complex1_Re_81 : 7|16@0- (1,0) [-32768|32767] "n/a"  PC
 SG_ Complex1_Im_81 : 23|16@0- (1,0) [-32768|32767] "n/a"  PC

BO_ 1659 MB79_TARGET_DETECTION_81B: 8 SODX
 SG_ StdAzimuth_81 : 63|8@0+ (0.0009766,0) [0|14.31] "°"  PC
 SG_ PowerDB_81 : 7|8@0+ (1,0) [0|255] "db"  PC
 SG_ CoGRange_81 : 15|16@0- (0.01,0) [0|96] "m"  PC
 SG_ CoGDoppler_81 : 31|16@0- (0.01,0) [-140|14] "m/s"  PC
 SG_ Azimuth_81 : 47|16@0- (0.1,0) [-180|180] "°"  PC

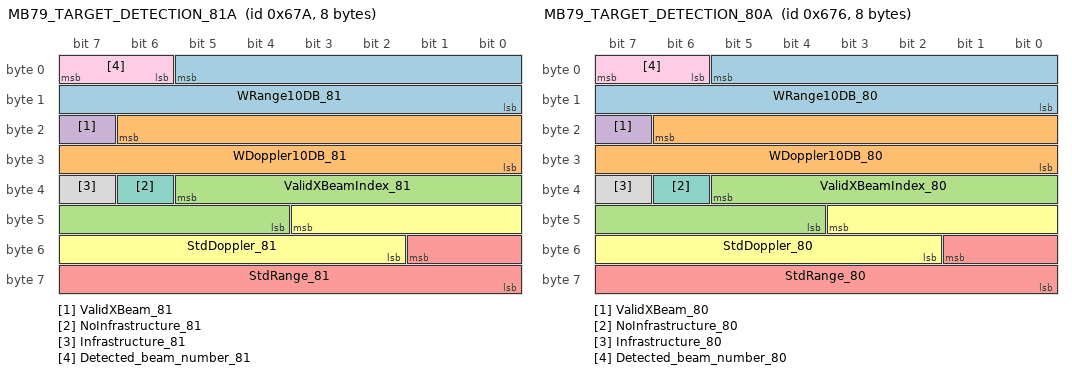
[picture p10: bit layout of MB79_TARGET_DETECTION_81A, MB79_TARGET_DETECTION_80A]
BO_ 1658 MB79_TARGET_DETECTION_81A: 8 SODX
 SG_ WRange10DB_81 : 5|14@0+ (0.01,0) [0|96] "m"  PC
 SG_ WDoppler10DB_81 : 22|15@0+ (0.01,0) [0|280] "m/s"  PC
 SG_ ValidXBeamIndex_81 : 37|10@0+ (1,0) [0|0] "n/a"  PC
 SG_ ValidXBeam_81 : 23|1@0+ (1,0) [0|0] "n/a"  PC
 SG_ StdRange_81 : 49|10@0+ (0.01,0) [0|10] "m"  PC
 SG_ StdDoppler_81 : 43|10@0+ (0.01,0) [0|10] "m/s"  PC
 SG_ NoInfrastructure_81 : 38|1@0+ (1,0) [0|0] "n/a"  PC
 SG_ Infrastructure_81 : 39|1@0+ (1,0) [0|0] "n/a"  PC
 SG_ Detected_beam_number_81 : 7|2@0+ (1,0) [0|0] "n/a"  PC

BO_ 1657 MB79_TARGET_DETECTION_80D: 8 SODX
 SG_ Complex4_Re_80 : 39|16@0- (1,0) [-32768|32767] "n/a"  PC
 SG_ Complex4_Im_80 : 55|16@0- (1,0) [-32768|32767] "n/a"  PC
 SG_ Complex3_Re_80 : 7|16@0- (1,0) [-32768|32767] "n/a"  PC
 SG_ Complex3_Im_80 : 23|16@0- (1,0) [-32768|32767] "n/a"  PC

BO_ 1656 MB79_TARGET_DETECTION_80C: 8 SODX
 SG_ Complex2_Re_80 : 39|16@0- (1,0) [-32768|32767] "n/a"  PC
 SG_ Complex2_Im_80 : 55|16@0- (1,0) [-32768|32767] "n/a"  PC
 SG_ Complex1_Re_80 : 7|16@0- (1,0) [-32768|32767] "n/a"  PC
 SG_ Complex1_Im_80 : 23|16@0- (1,0) [-32768|32767] "n/a"  PC

BO_ 1655 MB79_TARGET_DETECTION_80B: 8 SODX
 SG_ StdAzimuth_80 : 63|8@0+ (0.0009766,0) [0|14.31] "°"  PC
 SG_ PowerDB_80 : 7|8@0+ (1,0) [0|255] "db"  PC
 SG_ CoGRange_80 : 15|16@0- (0.01,0) [0|96] "m"  PC
 SG_ CoGDoppler_80 : 31|16@0- (0.01,0) [-140|14] "m/s"  PC
 SG_ Azimuth_80 : 47|16@0- (0.1,0) [-180|180] "°"  PC

BO_ 1654 MB79_TARGET_DETECTION_80A: 8 SODX
 SG_ WRange10DB_80 : 5|14@0+ (0.01,0) [0|96] "m"  PC
 SG_ WDoppler10DB_80 : 22|15@0+ (0.01,0) [0|280] "m/s"  PC
 SG_ ValidXBeamIndex_80 : 37|10@0+ (1,0) [0|0] "n/a"  PC
 SG_ ValidXBeam_80 : 23|1@0+ (1,0) [0|0] "n/a"  PC
 SG_ StdRange_80 : 49|10@0+ (0.01,0) [0|10] "m"  PC
 SG_ StdDoppler_80 : 43|10@0+ (0.01,0) [0|10] "m/s"  PC
 SG_ NoInfrastructure_80 : 38|1@0+ (1,0) [0|0] "n/a"  PC
 SG_ Infrastructure_80 : 39|1@0+ (1,0) [0|0] "n/a"  PC
 SG_ Detected_beam_number_80 : 7|2@0+ (1,0) [0|0] "n/a"  PC

BO_ 285 MB79_TARGET_DETECTION_7D: 8 SODX
 SG_ Complex4_Re_7 : 39|16@0- (1,0) [-32768|32767] "n/a"  PC
 SG_ Complex4_Im_7 : 55|16@0- (1,0) [-32768|32767] "n/a"  PC
 SG_ Complex3_Re_7 : 7|16@0- (1,0) [-32768|32767] "n/a"  PC
 SG_ Complex3_Im_7 : 23|16@0- (1,0) [-32768|32767] "n/a"  PC

BO_ 284 MB79_TARGET_DETECTION_7C: 8 SODX
 SG_ Complex2_Re_7 : 39|16@0- (1,0) [-32768|32767] "n/a"  PC
 SG_ Complex2_Im_7 : 55|16@0- (1,0) [-32768|32767] "n/a"  PC
 SG_ Complex1_Re_7 : 7|16@0- (1,0) [-32768|32767] "n/a"  PC
 SG_ Complex1_Im_7 : 23|16@0- (1,0) [-32768|32767] "n/a"  PC

BO_ 283 MB79_TARGET_DETECTION_7B: 8 SODX
 SG_ StdAzimuth_7 : 63|8@0+ (0.0009766,0) [0|14.31] "°"  PC
 SG_ PowerDB_7 : 7|8@0+ (1,0) [0|255] "db"  PC
 SG_ CoGRange_7 : 15|16@0- (0.01,0) [0|96] "m"  PC
 SG_ CoGDoppler_7 : 31|16@0- (0.01,0) [-140|14] "m/s"  PC
 SG_ Azimuth_7 : 47|16@0- (0.1,0) [-180|180] "°"  PC

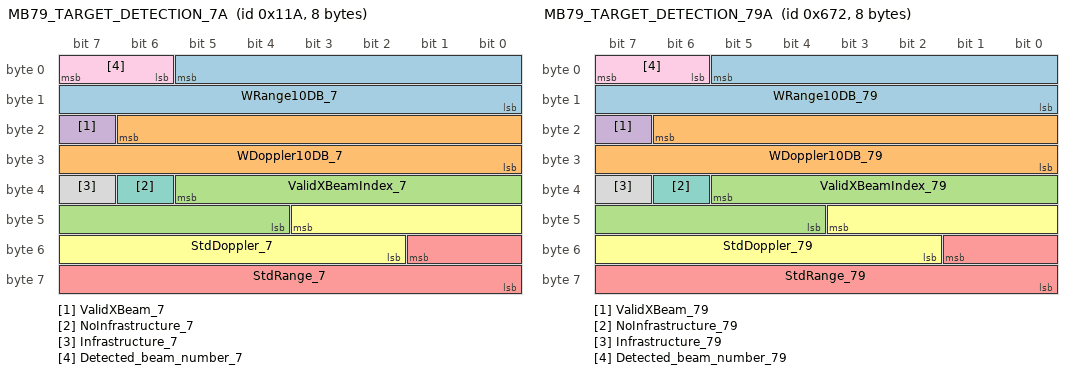
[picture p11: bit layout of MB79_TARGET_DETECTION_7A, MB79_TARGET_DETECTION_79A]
BO_ 282 MB79_TARGET_DETECTION_7A: 8 SODX
 SG_ WRange10DB_7 : 5|14@0+ (0.01,0) [0|96] "m"  PC
 SG_ WDoppler10DB_7 : 22|15@0+ (0.01,0) [0|280] "m/s"  PC
 SG_ ValidXBeamIndex_7 : 37|10@0+ (1,0) [0|0] "n/a"  PC
 SG_ ValidXBeam_7 : 23|1@0+ (1,0) [0|0] "n/a"  PC
 SG_ StdRange_7 : 49|10@0+ (0.01,0) [0|10] "m"  PC
 SG_ StdDoppler_7 : 43|10@0+ (0.01,0) [0|10] "m/s"  PC
 SG_ NoInfrastructure_7 : 38|1@0+ (1,0) [0|0] "n/a"  PC
 SG_ Infrastructure_7 : 39|1@0+ (1,0) [0|0] "n/a"  PC
 SG_ Detected_beam_number_7 : 7|2@0+ (1,0) [0|0] "n/a"  PC

BO_ 1653 MB79_TARGET_DETECTION_79D: 8 SODX
 SG_ Complex4_Re_79 : 39|16@0- (1,0) [-32768|32767] "n/a"  PC
 SG_ Complex4_Im_79 : 55|16@0- (1,0) [-32768|32767] "n/a"  PC
 SG_ Complex3_Re_79 : 7|16@0- (1,0) [-32768|32767] "n/a"  PC
 SG_ Complex3_Im_79 : 23|16@0- (1,0) [-32768|32767] "n/a"  PC

BO_ 1652 MB79_TARGET_DETECTION_79C: 8 SODX
 SG_ Complex2_Re_79 : 39|16@0- (1,0) [-32768|32767] "n/a"  PC
 SG_ Complex2_Im_79 : 55|16@0- (1,0) [-32768|32767] "n/a"  PC
 SG_ Complex1_Re_79 : 7|16@0- (1,0) [-32768|32767] "n/a"  PC
 SG_ Complex1_Im_79 : 23|16@0- (1,0) [-32768|32767] "n/a"  PC

BO_ 1651 MB79_TARGET_DETECTION_79B: 8 SODX
 SG_ StdAzimuth_79 : 63|8@0+ (0.0009766,0) [0|14.31] "°"  PC
 SG_ PowerDB_79 : 7|8@0+ (1,0) [0|255] "db"  PC
 SG_ CoGRange_79 : 15|16@0- (0.01,0) [0|96] "m"  PC
 SG_ CoGDoppler_79 : 31|16@0- (0.01,0) [-140|14] "m/s"  PC
 SG_ Azimuth_79 : 47|16@0- (0.1,0) [-180|180] "°"  PC

BO_ 1650 MB79_TARGET_DETECTION_79A: 8 SODX
 SG_ WRange10DB_79 : 5|14@0+ (0.01,0) [0|96] "m"  PC
 SG_ WDoppler10DB_79 : 22|15@0+ (0.01,0) [0|280] "m/s"  PC
 SG_ ValidXBeamIndex_79 : 37|10@0+ (1,0) [0|0] "n/a"  PC
 SG_ ValidXBeam_79 : 23|1@0+ (1,0) [0|0] "n/a"  PC
 SG_ StdRange_79 : 49|10@0+ (0.01,0) [0|10] "m"  PC
 SG_ StdDoppler_79 : 43|10@0+ (0.01,0) [0|10] "m/s"  PC
 SG_ NoInfrastructure_79 : 38|1@0+ (1,0) [0|0] "n/a"  PC
 SG_ Infrastructure_79 : 39|1@0+ (1,0) [0|0] "n/a"  PC
 SG_ Detected_beam_number_79 : 7|2@0+ (1,0) [0|0] "n/a"  PC

BO_ 1649 MB79_TARGET_DETECTION_78D: 8 SODX
 SG_ Complex4_Re_78 : 39|16@0- (1,0) [-32768|32767] "n/a"  PC
 SG_ Complex4_Im_78 : 55|16@0- (1,0) [-32768|32767] "n/a"  PC
 SG_ Complex3_Re_78 : 7|16@0- (1,0) [-32768|32767] "n/a"  PC
 SG_ Complex3_Im_78 : 23|16@0- (1,0) [-32768|32767] "n/a"  PC

BO_ 1648 MB79_TARGET_DETECTION_78C: 8 SODX
 SG_ Complex2_Re_78 : 39|16@0- (1,0) [-32768|32767] "n/a"  PC
 SG_ Complex2_Im_78 : 55|16@0- (1,0) [-32768|32767] "n/a"  PC
 SG_ Complex1_Re_78 : 7|16@0- (1,0) [-32768|32767] "n/a"  PC
 SG_ Complex1_Im_78 : 23|16@0- (1,0) [-32768|32767] "n/a"  PC

BO_ 1647 MB79_TARGET_DETECTION_78B: 8 SODX
 SG_ StdAzimuth_78 : 63|8@0+ (0.0009766,0) [0|14.31] "°"  PC
 SG_ PowerDB_78 : 7|8@0+ (1,0) [0|255] "db"  PC
 SG_ CoGRange_78 : 15|16@0- (0.01,0) [0|96] "m"  PC
 SG_ CoGDoppler_78 : 31|16@0- (0.01,0) [-140|14] "m/s"  PC
 SG_ Azimuth_78 : 47|16@0- (0.1,0) [-180|180] "°"  PC

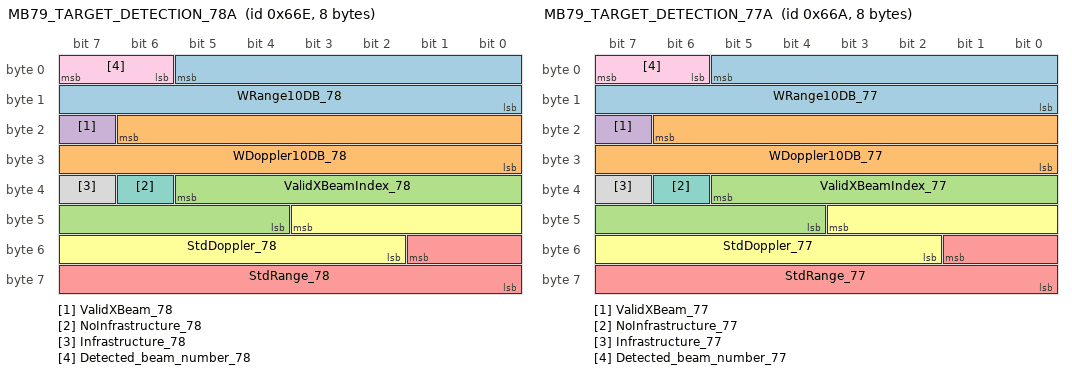
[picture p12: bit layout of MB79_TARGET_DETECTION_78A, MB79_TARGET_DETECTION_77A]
BO_ 1646 MB79_TARGET_DETECTION_78A: 8 SODX
 SG_ WRange10DB_78 : 5|14@0+ (0.01,0) [0|96] "m"  PC
 SG_ WDoppler10DB_78 : 22|15@0+ (0.01,0) [0|280] "m/s"  PC
 SG_ ValidXBeamIndex_78 : 37|10@0+ (1,0) [0|0] "n/a"  PC
 SG_ ValidXBeam_78 : 23|1@0+ (1,0) [0|0] "n/a"  PC
 SG_ StdRange_78 : 49|10@0+ (0.01,0) [0|10] "m"  PC
 SG_ StdDoppler_78 : 43|10@0+ (0.01,0) [0|10] "m/s"  PC
 SG_ NoInfrastructure_78 : 38|1@0+ (1,0) [0|0] "n/a"  PC
 SG_ Infrastructure_78 : 39|1@0+ (1,0) [0|0] "n/a"  PC
 SG_ Detected_beam_number_78 : 7|2@0+ (1,0) [0|0] "n/a"  PC

BO_ 1645 MB79_TARGET_DETECTION_77D: 8 SODX
 SG_ Complex4_Re_77 : 39|16@0- (1,0) [-32768|32767] "n/a"  PC
 SG_ Complex4_Im_77 : 55|16@0- (1,0) [-32768|32767] "n/a"  PC
 SG_ Complex3_Re_77 : 7|16@0- (1,0) [-32768|32767] "n/a"  PC
 SG_ Complex3_Im_77 : 23|16@0- (1,0) [-32768|32767] "n/a"  PC

BO_ 1644 MB79_TARGET_DETECTION_77C: 8 SODX
 SG_ Complex2_Re_77 : 39|16@0- (1,0) [-32768|32767] "n/a"  PC
 SG_ Complex2_Im_77 : 55|16@0- (1,0) [-32768|32767] "n/a"  PC
 SG_ Complex1_Re_77 : 7|16@0- (1,0) [-32768|32767] "n/a"  PC
 SG_ Complex1_Im_77 : 23|16@0- (1,0) [-32768|32767] "n/a"  PC

BO_ 1643 MB79_TARGET_DETECTION_77B: 8 SODX
 SG_ StdAzimuth_77 : 63|8@0+ (0.0009766,0) [0|14.31] "°"  PC
 SG_ PowerDB_77 : 7|8@0+ (1,0) [0|255] "db"  PC
 SG_ CoGRange_77 : 15|16@0- (0.01,0) [0|96] "m"  PC
 SG_ CoGDoppler_77 : 31|16@0- (0.01,0) [-140|14] "m/s"  PC
 SG_ Azimuth_77 : 47|16@0- (0.1,0) [-180|180] "°"  PC

BO_ 1642 MB79_TARGET_DETECTION_77A: 8 SODX
 SG_ WRange10DB_77 : 5|14@0+ (0.01,0) [0|96] "m"  PC
 SG_ WDoppler10DB_77 : 22|15@0+ (0.01,0) [0|280] "m/s"  PC
 SG_ ValidXBeamIndex_77 : 37|10@0+ (1,0) [0|0] "n/a"  PC
 SG_ ValidXBeam_77 : 23|1@0+ (1,0) [0|0] "n/a"  PC
 SG_ StdRange_77 : 49|10@0+ (0.01,0) [0|10] "m"  PC
 SG_ StdDoppler_77 : 43|10@0+ (0.01,0) [0|10] "m/s"  PC
 SG_ NoInfrastructure_77 : 38|1@0+ (1,0) [0|0] "n/a"  PC
 SG_ Infrastructure_77 : 39|1@0+ (1,0) [0|0] "n/a"  PC
 SG_ Detected_beam_number_77 : 7|2@0+ (1,0) [0|0] "n/a"  PC

BO_ 1641 MB79_TARGET_DETECTION_76D: 8 SODX
 SG_ Complex4_Re_76 : 39|16@0- (1,0) [-32768|32767] "n/a"  PC
 SG_ Complex4_Im_76 : 55|16@0- (1,0) [-32768|32767] "n/a"  PC
 SG_ Complex3_Re_76 : 7|16@0- (1,0) [-32768|32767] "n/a"  PC
 SG_ Complex3_Im_76 : 23|16@0- (1,0) [-32768|32767] "n/a"  PC

BO_ 1640 MB79_TARGET_DETECTION_76C: 8 SODX
 SG_ Complex2_Re_76 : 39|16@0- (1,0) [-32768|32767] "n/a"  PC
 SG_ Complex2_Im_76 : 55|16@0- (1,0) [-32768|32767] "n/a"  PC
 SG_ Complex1_Re_76 : 7|16@0- (1,0) [-32768|32767] "n/a"  PC
 SG_ Complex1_Im_76 : 23|16@0- (1,0) [-32768|32767] "n/a"  PC

BO_ 1639 MB79_TARGET_DETECTION_76B: 8 SODX
 SG_ StdAzimuth_76 : 63|8@0+ (0.0009766,0) [0|14.31] "°"  PC
 SG_ PowerDB_76 : 7|8@0+ (1,0) [0|255] "db"  PC
 SG_ CoGRange_76 : 15|16@0- (0.01,0) [0|96] "m"  PC
 SG_ CoGDoppler_76 : 31|16@0- (0.01,0) [-140|14] "m/s"  PC
 SG_ Azimuth_76 : 47|16@0- (0.1,0) [-180|180] "°"  PC

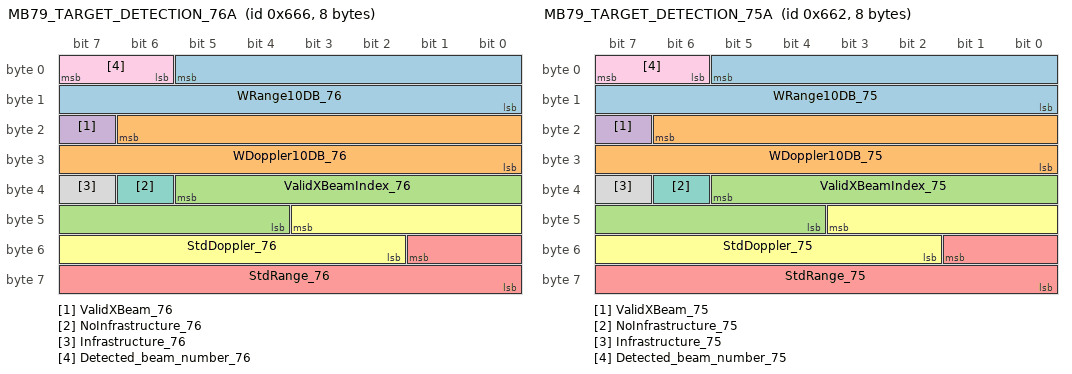
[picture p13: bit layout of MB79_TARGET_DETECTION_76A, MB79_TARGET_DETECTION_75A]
BO_ 1638 MB79_TARGET_DETECTION_76A: 8 SODX
 SG_ WRange10DB_76 : 5|14@0+ (0.01,0) [0|96] "m"  PC
 SG_ WDoppler10DB_76 : 22|15@0+ (0.01,0) [0|280] "m/s"  PC
 SG_ ValidXBeamIndex_76 : 37|10@0+ (1,0) [0|0] "n/a"  PC
 SG_ ValidXBeam_76 : 23|1@0+ (1,0) [0|0] "n/a"  PC
 SG_ StdRange_76 : 49|10@0+ (0.01,0) [0|10] "m"  PC
 SG_ StdDoppler_76 : 43|10@0+ (0.01,0) [0|10] "m/s"  PC
 SG_ NoInfrastructure_76 : 38|1@0+ (1,0) [0|0] "n/a"  PC
 SG_ Infrastructure_76 : 39|1@0+ (1,0) [0|0] "n/a"  PC
 SG_ Detected_beam_number_76 : 7|2@0+ (1,0) [0|0] "n/a"  PC

BO_ 1637 MB79_TARGET_DETECTION_75D: 8 SODX
 SG_ Complex4_Re_75 : 39|16@0- (1,0) [-32768|32767] "n/a"  PC
 SG_ Complex4_Im_75 : 55|16@0- (1,0) [-32768|32767] "n/a"  PC
 SG_ Complex3_Re_75 : 7|16@0- (1,0) [-32768|32767] "n/a"  PC
 SG_ Complex3_Im_75 : 23|16@0- (1,0) [-32768|32767] "n/a"  PC

BO_ 1636 MB79_TARGET_DETECTION_75C: 8 SODX
 SG_ Complex2_Re_75 : 39|16@0- (1,0) [-32768|32767] "n/a"  PC
 SG_ Complex2_Im_75 : 55|16@0- (1,0) [-32768|32767] "n/a"  PC
 SG_ Complex1_Re_75 : 7|16@0- (1,0) [-32768|32767] "n/a"  PC
 SG_ Complex1_Im_75 : 23|16@0- (1,0) [-32768|32767] "n/a"  PC

BO_ 1635 MB79_TARGET_DETECTION_75B: 8 SODX
 SG_ StdAzimuth_75 : 63|8@0+ (0.0009766,0) [0|14.31] "°"  PC
 SG_ PowerDB_75 : 7|8@0+ (1,0) [0|255] "db"  PC
 SG_ CoGRange_75 : 15|16@0- (0.01,0) [0|96] "m"  PC
 SG_ CoGDoppler_75 : 31|16@0- (0.01,0) [-140|14] "m/s"  PC
 SG_ Azimuth_75 : 47|16@0- (0.1,0) [-180|180] "°"  PC

BO_ 1634 MB79_TARGET_DETECTION_75A: 8 SODX
 SG_ WRange10DB_75 : 5|14@0+ (0.01,0) [0|96] "m"  PC
 SG_ WDoppler10DB_75 : 22|15@0+ (0.01,0) [0|280] "m/s"  PC
 SG_ ValidXBeamIndex_75 : 37|10@0+ (1,0) [0|0] "n/a"  PC
 SG_ ValidXBeam_75 : 23|1@0+ (1,0) [0|0] "n/a"  PC
 SG_ StdRange_75 : 49|10@0+ (0.01,0) [0|10] "m"  PC
 SG_ StdDoppler_75 : 43|10@0+ (0.01,0) [0|10] "m/s"  PC
 SG_ NoInfrastructure_75 : 38|1@0+ (1,0) [0|0] "n/a"  PC
 SG_ Infrastructure_75 : 39|1@0+ (1,0) [0|0] "n/a"  PC
 SG_ Detected_beam_number_75 : 7|2@0+ (1,0) [0|0] "n/a"  PC

BO_ 1633 MB79_TARGET_DETECTION_74D: 8 SODX
 SG_ Complex4_Re_74 : 39|16@0- (1,0) [-32768|32767] "n/a"  PC
 SG_ Complex4_Im_74 : 55|16@0- (1,0) [-32768|32767] "n/a"  PC
 SG_ Complex3_Re_74 : 7|16@0- (1,0) [-32768|32767] "n/a"  PC
 SG_ Complex3_Im_74 : 23|16@0- (1,0) [-32768|32767] "n/a"  PC

BO_ 1632 MB79_TARGET_DETECTION_74C: 8 SODX
 SG_ Complex2_Re_74 : 39|16@0- (1,0) [-32768|32767] "n/a"  PC
 SG_ Complex2_Im_74 : 55|16@0- (1,0) [-32768|32767] "n/a"  PC
 SG_ Complex1_Re_74 : 7|16@0- (1,0) [-32768|32767] "n/a"  PC
 SG_ Complex1_Im_74 : 23|16@0- (1,0) [-32768|32767] "n/a"  PC

BO_ 1631 MB79_TARGET_DETECTION_74B: 8 SODX
 SG_ StdAzimuth_74 : 63|8@0+ (0.0009766,0) [0|14.31] "°"  PC
 SG_ PowerDB_74 : 7|8@0+ (1,0) [0|255] "db"  PC
 SG_ CoGRange_74 : 15|16@0- (0.01,0) [0|96] "m"  PC
 SG_ CoGDoppler_74 : 31|16@0- (0.01,0) [-140|14] "m/s"  PC
 SG_ Azimuth_74 : 47|16@0- (0.1,0) [-180|180] "°"  PC

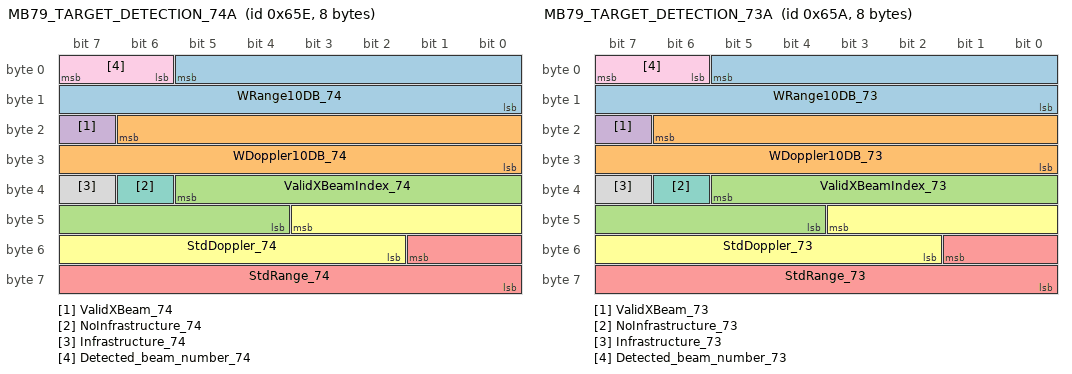
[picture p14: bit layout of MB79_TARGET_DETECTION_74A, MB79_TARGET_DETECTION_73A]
BO_ 1630 MB79_TARGET_DETECTION_74A: 8 SODX
 SG_ WRange10DB_74 : 5|14@0+ (0.01,0) [0|96] "m"  PC
 SG_ WDoppler10DB_74 : 22|15@0+ (0.01,0) [0|280] "m/s"  PC
 SG_ ValidXBeamIndex_74 : 37|10@0+ (1,0) [0|0] "n/a"  PC
 SG_ ValidXBeam_74 : 23|1@0+ (1,0) [0|0] "n/a"  PC
 SG_ StdRange_74 : 49|10@0+ (0.01,0) [0|10] "m"  PC
 SG_ StdDoppler_74 : 43|10@0+ (0.01,0) [0|10] "m/s"  PC
 SG_ NoInfrastructure_74 : 38|1@0+ (1,0) [0|0] "n/a"  PC
 SG_ Infrastructure_74 : 39|1@0+ (1,0) [0|0] "n/a"  PC
 SG_ Detected_beam_number_74 : 7|2@0+ (1,0) [0|0] "n/a"  PC

BO_ 1629 MB79_TARGET_DETECTION_73D: 8 SODX
 SG_ Complex4_Re_73 : 39|16@0- (1,0) [-32768|32767] "n/a"  PC
 SG_ Complex4_Im_73 : 55|16@0- (1,0) [-32768|32767] "n/a"  PC
 SG_ Complex3_Re_73 : 7|16@0- (1,0) [-32768|32767] "n/a"  PC
 SG_ Complex3_Im_73 : 23|16@0- (1,0) [-32768|32767] "n/a"  PC

BO_ 1628 MB79_TARGET_DETECTION_73C: 8 SODX
 SG_ Complex2_Re_73 : 39|16@0- (1,0) [-32768|32767] "n/a"  PC
 SG_ Complex2_Im_73 : 55|16@0- (1,0) [-32768|32767] "n/a"  PC
 SG_ Complex1_Re_73 : 7|16@0- (1,0) [-32768|32767] "n/a"  PC
 SG_ Complex1_Im_73 : 23|16@0- (1,0) [-32768|32767] "n/a"  PC

BO_ 1627 MB79_TARGET_DETECTION_73B: 8 SODX
 SG_ StdAzimuth_73 : 63|8@0+ (0.0009766,0) [0|14.31] "°"  PC
 SG_ PowerDB_73 : 7|8@0+ (1,0) [0|255] "db"  PC
 SG_ CoGRange_73 : 15|16@0- (0.01,0) [0|96] "m"  PC
 SG_ CoGDoppler_73 : 31|16@0- (0.01,0) [-140|14] "m/s"  PC
 SG_ Azimuth_73 : 47|16@0- (0.1,0) [-180|180] "°"  PC

BO_ 1626 MB79_TARGET_DETECTION_73A: 8 SODX
 SG_ WRange10DB_73 : 5|14@0+ (0.01,0) [0|96] "m"  PC
 SG_ WDoppler10DB_73 : 22|15@0+ (0.01,0) [0|280] "m/s"  PC
 SG_ ValidXBeamIndex_73 : 37|10@0+ (1,0) [0|0] "n/a"  PC
 SG_ ValidXBeam_73 : 23|1@0+ (1,0) [0|0] "n/a"  PC
 SG_ StdRange_73 : 49|10@0+ (0.01,0) [0|10] "m"  PC
 SG_ StdDoppler_73 : 43|10@0+ (0.01,0) [0|10] "m/s"  PC
 SG_ NoInfrastructure_73 : 38|1@0+ (1,0) [0|0] "n/a"  PC
 SG_ Infrastructure_73 : 39|1@0+ (1,0) [0|0] "n/a"  PC
 SG_ Detected_beam_number_73 : 7|2@0+ (1,0) [0|0] "n/a"  PC

BO_ 1625 MB79_TARGET_DETECTION_72D: 8 SODX
 SG_ Complex4_Re_72 : 39|16@0- (1,0) [-32768|32767] "n/a"  PC
 SG_ Complex4_Im_72 : 55|16@0- (1,0) [-32768|32767] "n/a"  PC
 SG_ Complex3_Re_72 : 7|16@0- (1,0) [-32768|32767] "n/a"  PC
 SG_ Complex3_Im_72 : 23|16@0- (1,0) [-32768|32767] "n/a"  PC

BO_ 1624 MB79_TARGET_DETECTION_72C: 8 SODX
 SG_ Complex2_Re_72 : 39|16@0- (1,0) [-32768|32767] "n/a"  PC
 SG_ Complex2_Im_72 : 55|16@0- (1,0) [-32768|32767] "n/a"  PC
 SG_ Complex1_Re_72 : 7|16@0- (1,0) [-32768|32767] "n/a"  PC
 SG_ Complex1_Im_72 : 23|16@0- (1,0) [-32768|32767] "n/a"  PC

BO_ 1623 MB79_TARGET_DETECTION_72B: 8 SODX
 SG_ StdAzimuth_72 : 63|8@0+ (0.0009766,0) [0|14.31] "°"  PC
 SG_ PowerDB_72 : 7|8@0+ (1,0) [0|255] "db"  PC
 SG_ CoGRange_72 : 15|16@0- (0.01,0) [0|96] "m"  PC
 SG_ CoGDoppler_72 : 31|16@0- (0.01,0) [-140|14] "m/s"  PC
 SG_ Azimuth_72 : 47|16@0- (0.1,0) [-180|180] "°"  PC

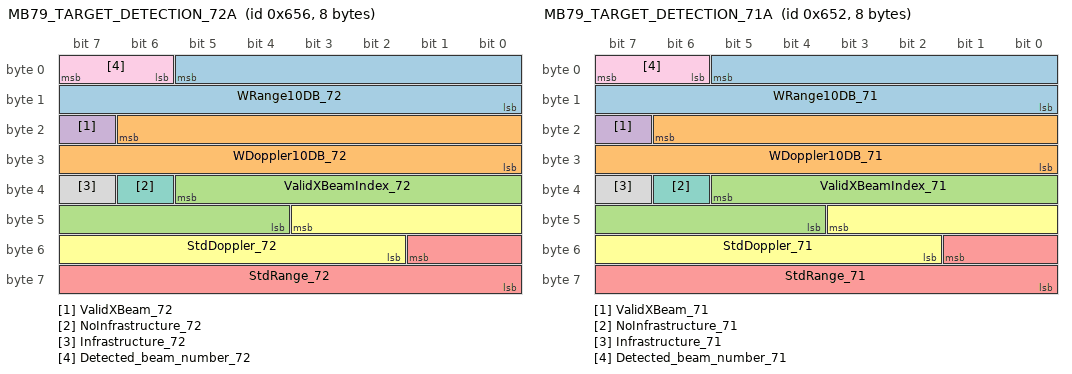
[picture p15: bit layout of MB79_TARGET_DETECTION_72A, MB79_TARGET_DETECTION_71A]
BO_ 1622 MB79_TARGET_DETECTION_72A: 8 SODX
 SG_ WRange10DB_72 : 5|14@0+ (0.01,0) [0|96] "m"  PC
 SG_ WDoppler10DB_72 : 22|15@0+ (0.01,0) [0|280] "m/s"  PC
 SG_ ValidXBeamIndex_72 : 37|10@0+ (1,0) [0|0] "n/a"  PC
 SG_ ValidXBeam_72 : 23|1@0+ (1,0) [0|0] "n/a"  PC
 SG_ StdRange_72 : 49|10@0+ (0.01,0) [0|10] "m"  PC
 SG_ StdDoppler_72 : 43|10@0+ (0.01,0) [0|10] "m/s"  PC
 SG_ NoInfrastructure_72 : 38|1@0+ (1,0) [0|0] "n/a"  PC
 SG_ Infrastructure_72 : 39|1@0+ (1,0) [0|0] "n/a"  PC
 SG_ Detected_beam_number_72 : 7|2@0+ (1,0) [0|0] "n/a"  PC

BO_ 1621 MB79_TARGET_DETECTION_71D: 8 SODX
 SG_ Complex4_Re_71 : 39|16@0- (1,0) [-32768|32767] "n/a"  PC
 SG_ Complex4_Im_71 : 55|16@0- (1,0) [-32768|32767] "n/a"  PC
 SG_ Complex3_Re_71 : 7|16@0- (1,0) [-32768|32767] "n/a"  PC
 SG_ Complex3_Im_71 : 23|16@0- (1,0) [-32768|32767] "n/a"  PC

BO_ 1620 MB79_TARGET_DETECTION_71C: 8 SODX
 SG_ Complex2_Re_71 : 39|16@0- (1,0) [-32768|32767] "n/a"  PC
 SG_ Complex2_Im_71 : 55|16@0- (1,0) [-32768|32767] "n/a"  PC
 SG_ Complex1_Re_71 : 7|16@0- (1,0) [-32768|32767] "n/a"  PC
 SG_ Complex1_Im_71 : 23|16@0- (1,0) [-32768|32767] "n/a"  PC

BO_ 1619 MB79_TARGET_DETECTION_71B: 8 SODX
 SG_ StdAzimuth_71 : 63|8@0+ (0.0009766,0) [0|14.31] "°"  PC
 SG_ PowerDB_71 : 7|8@0+ (1,0) [0|255] "db"  PC
 SG_ CoGRange_71 : 15|16@0- (0.01,0) [0|96] "m"  PC
 SG_ CoGDoppler_71 : 31|16@0- (0.01,0) [-140|14] "m/s"  PC
 SG_ Azimuth_71 : 47|16@0- (0.1,0) [-180|180] "°"  PC

BO_ 1618 MB79_TARGET_DETECTION_71A: 8 SODX
 SG_ WRange10DB_71 : 5|14@0+ (0.01,0) [0|96] "m"  PC
 SG_ WDoppler10DB_71 : 22|15@0+ (0.01,0) [0|280] "m/s"  PC
 SG_ ValidXBeamIndex_71 : 37|10@0+ (1,0) [0|0] "n/a"  PC
 SG_ ValidXBeam_71 : 23|1@0+ (1,0) [0|0] "n/a"  PC
 SG_ StdRange_71 : 49|10@0+ (0.01,0) [0|10] "m"  PC
 SG_ StdDoppler_71 : 43|10@0+ (0.01,0) [0|10] "m/s"  PC
 SG_ NoInfrastructure_71 : 38|1@0+ (1,0) [0|0] "n/a"  PC
 SG_ Infrastructure_71 : 39|1@0+ (1,0) [0|0] "n/a"  PC
 SG_ Detected_beam_number_71 : 7|2@0+ (1,0) [0|0] "n/a"  PC

BO_ 1617 MB79_TARGET_DETECTION_70D: 8 SODX
 SG_ Complex4_Re_70 : 39|16@0- (1,0) [-32768|32767] "n/a"  PC
 SG_ Complex4_Im_70 : 55|16@0- (1,0) [-32768|32767] "n/a"  PC
 SG_ Complex3_Re_70 : 7|16@0- (1,0) [-32768|32767] "n/a"  PC
 SG_ Complex3_Im_70 : 23|16@0- (1,0) [-32768|32767] "n/a"  PC

BO_ 1616 MB79_TARGET_DETECTION_70C: 8 SODX
 SG_ Complex2_Re_70 : 39|16@0- (1,0) [-32768|32767] "n/a"  PC
 SG_ Complex2_Im_70 : 55|16@0- (1,0) [-32768|32767] "n/a"  PC
 SG_ Complex1_Re_70 : 7|16@0- (1,0) [-32768|32767] "n/a"  PC
 SG_ Complex1_Im_70 : 23|16@0- (1,0) [-32768|32767] "n/a"  PC

BO_ 1615 MB79_TARGET_DETECTION_70B: 8 SODX
 SG_ StdAzimuth_70 : 63|8@0+ (0.0009766,0) [0|14.31] "°"  PC
 SG_ PowerDB_70 : 7|8@0+ (1,0) [0|255] "db"  PC
 SG_ CoGRange_70 : 15|16@0- (0.01,0) [0|96] "m"  PC
 SG_ CoGDoppler_70 : 31|16@0- (0.01,0) [-140|14] "m/s"  PC
 SG_ Azimuth_70 : 47|16@0- (0.1,0) [-180|180] "°"  PC

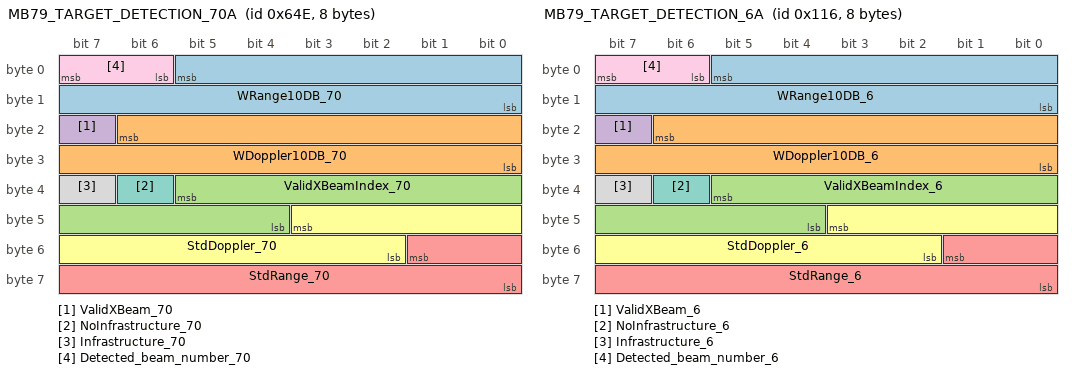
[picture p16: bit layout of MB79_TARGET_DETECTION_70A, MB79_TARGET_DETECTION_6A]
BO_ 1614 MB79_TARGET_DETECTION_70A: 8 SODX
 SG_ WRange10DB_70 : 5|14@0+ (0.01,0) [0|96] "m"  PC
 SG_ WDoppler10DB_70 : 22|15@0+ (0.01,0) [0|280] "m/s"  PC
 SG_ ValidXBeamIndex_70 : 37|10@0+ (1,0) [0|0] "n/a"  PC
 SG_ ValidXBeam_70 : 23|1@0+ (1,0) [0|0] "n/a"  PC
 SG_ StdRange_70 : 49|10@0+ (0.01,0) [0|10] "m"  PC
 SG_ StdDoppler_70 : 43|10@0+ (0.01,0) [0|10] "m/s"  PC
 SG_ NoInfrastructure_70 : 38|1@0+ (1,0) [0|0] "n/a"  PC
 SG_ Infrastructure_70 : 39|1@0+ (1,0) [0|0] "n/a"  PC
 SG_ Detected_beam_number_70 : 7|2@0+ (1,0) [0|0] "n/a"  PC

BO_ 281 MB79_TARGET_DETECTION_6D: 8 SODX
 SG_ Complex4_Re_6 : 39|16@0- (1,0) [-32768|32767] "n/a"  PC
 SG_ Complex4_Im_6 : 55|16@0- (1,0) [-32768|32767] "n/a"  PC
 SG_ Complex3_Re_6 : 7|16@0- (1,0) [-32768|32767] "n/a"  PC
 SG_ Complex3_Im_6 : 23|16@0- (1,0) [-32768|32767] "n/a"  PC

BO_ 280 MB79_TARGET_DETECTION_6C: 8 SODX
 SG_ Complex2_Re_6 : 39|16@0- (1,0) [-32768|32767] "n/a"  PC
 SG_ Complex2_Im_6 : 55|16@0- (1,0) [-32768|32767] "n/a"  PC
 SG_ Complex1_Re_6 : 7|16@0- (1,0) [-32768|32767] "n/a"  PC
 SG_ Complex1_Im_6 : 23|16@0- (1,0) [-32768|32767] "n/a"  PC

BO_ 279 MB79_TARGET_DETECTION_6B: 8 SODX
 SG_ StdAzimuth_6 : 63|8@0+ (0.0009766,0) [0|14.31] "°"  PC
 SG_ PowerDB_6 : 7|8@0+ (1,0) [0|255] "db"  PC
 SG_ CoGRange_6 : 15|16@0- (0.01,0) [0|96] "m"  PC
 SG_ CoGDoppler_6 : 31|16@0- (0.01,0) [-140|14] "m/s"  PC
 SG_ Azimuth_6 : 47|16@0- (0.1,0) [-180|180] "°"  PC

BO_ 278 MB79_TARGET_DETECTION_6A: 8 SODX
 SG_ WRange10DB_6 : 5|14@0+ (0.01,0) [0|96] "m"  PC
 SG_ WDoppler10DB_6 : 22|15@0+ (0.01,0) [0|280] "m/s"  PC
 SG_ ValidXBeamIndex_6 : 37|10@0+ (1,0) [0|0] "n/a"  PC
 SG_ ValidXBeam_6 : 23|1@0+ (1,0) [0|0] "n/a"  PC
 SG_ StdRange_6 : 49|10@0+ (0.01,0) [0|10] "m"  PC
 SG_ StdDoppler_6 : 43|10@0+ (0.01,0) [0|10] "m/s"  PC
 SG_ NoInfrastructure_6 : 38|1@0+ (1,0) [0|0] "n/a"  PC
 SG_ Infrastructure_6 : 39|1@0+ (1,0) [0|0] "n/a"  PC
 SG_ Detected_beam_number_6 : 7|2@0+ (1,0) [0|0] "n/a"  PC

BO_ 1613 MB79_TARGET_DETECTION_69D: 8 SODX
 SG_ Complex4_Re_69 : 39|16@0- (1,0) [-32768|32767] "n/a"  PC
 SG_ Complex4_Im_69 : 55|16@0- (1,0) [-32768|32767] "n/a"  PC
 SG_ Complex3_Re_69 : 7|16@0- (1,0) [-32768|32767] "n/a"  PC
 SG_ Complex3_Im_69 : 23|16@0- (1,0) [-32768|32767] "n/a"  PC

BO_ 1612 MB79_TARGET_DETECTION_69C: 8 SODX
 SG_ Complex2_Re_69 : 39|16@0- (1,0) [-32768|32767] "n/a"  PC
 SG_ Complex2_Im_69 : 55|16@0- (1,0) [-32768|32767] "n/a"  PC
 SG_ Complex1_Re_69 : 7|16@0- (1,0) [-32768|32767] "n/a"  PC
 SG_ Complex1_Im_69 : 23|16@0- (1,0) [-32768|32767] "n/a"  PC

BO_ 1611 MB79_TARGET_DETECTION_69B: 8 SODX
 SG_ StdAzimuth_69 : 63|8@0+ (0.0009766,0) [0|14.31] "°"  PC
 SG_ PowerDB_69 : 7|8@0+ (1,0) [0|255] "db"  PC
 SG_ CoGRange_69 : 15|16@0- (0.01,0) [0|96] "m"  PC
 SG_ CoGDoppler_69 : 31|16@0- (0.01,0) [-140|14] "m/s"  PC
 SG_ Azimuth_69 : 47|16@0- (0.1,0) [-180|180] "°"  PC

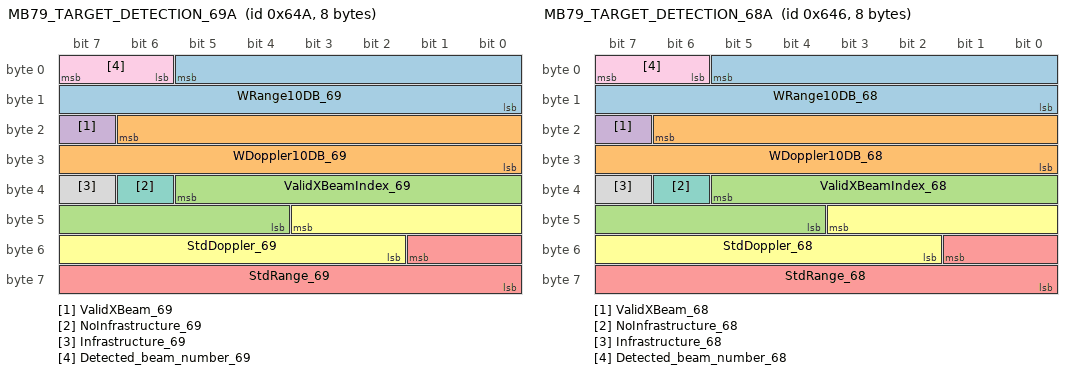
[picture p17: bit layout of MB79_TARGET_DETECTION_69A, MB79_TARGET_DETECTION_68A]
BO_ 1610 MB79_TARGET_DETECTION_69A: 8 SODX
 SG_ WRange10DB_69 : 5|14@0+ (0.01,0) [0|96] "m"  PC
 SG_ WDoppler10DB_69 : 22|15@0+ (0.01,0) [0|280] "m/s"  PC
 SG_ ValidXBeamIndex_69 : 37|10@0+ (1,0) [0|0] "n/a"  PC
 SG_ ValidXBeam_69 : 23|1@0+ (1,0) [0|0] "n/a"  PC
 SG_ StdRange_69 : 49|10@0+ (0.01,0) [0|10] "m"  PC
 SG_ StdDoppler_69 : 43|10@0+ (0.01,0) [0|10] "m/s"  PC
 SG_ NoInfrastructure_69 : 38|1@0+ (1,0) [0|0] "n/a"  PC
 SG_ Infrastructure_69 : 39|1@0+ (1,0) [0|0] "n/a"  PC
 SG_ Detected_beam_number_69 : 7|2@0+ (1,0) [0|0] "n/a"  PC

BO_ 1609 MB79_TARGET_DETECTION_68D: 8 SODX
 SG_ Complex4_Re_68 : 39|16@0- (1,0) [-32768|32767] "n/a"  PC
 SG_ Complex4_Im_68 : 55|16@0- (1,0) [-32768|32767] "n/a"  PC
 SG_ Complex3_Re_68 : 7|16@0- (1,0) [-32768|32767] "n/a"  PC
 SG_ Complex3_Im_68 : 23|16@0- (1,0) [-32768|32767] "n/a"  PC

BO_ 1608 MB79_TARGET_DETECTION_68C: 8 SODX
 SG_ Complex2_Re_68 : 39|16@0- (1,0) [-32768|32767] "n/a"  PC
 SG_ Complex2_Im_68 : 55|16@0- (1,0) [-32768|32767] "n/a"  PC
 SG_ Complex1_Re_68 : 7|16@0- (1,0) [-32768|32767] "n/a"  PC
 SG_ Complex1_Im_68 : 23|16@0- (1,0) [-32768|32767] "n/a"  PC

BO_ 1607 MB79_TARGET_DETECTION_68B: 8 SODX
 SG_ StdAzimuth_68 : 63|8@0+ (0.0009766,0) [0|14.31] "°"  PC
 SG_ PowerDB_68 : 7|8@0+ (1,0) [0|255] "db"  PC
 SG_ CoGRange_68 : 15|16@0- (0.01,0) [0|96] "m"  PC
 SG_ CoGDoppler_68 : 31|16@0- (0.01,0) [-140|14] "m/s"  PC
 SG_ Azimuth_68 : 47|16@0- (0.1,0) [-180|180] "°"  PC

BO_ 1606 MB79_TARGET_DETECTION_68A: 8 SODX
 SG_ WRange10DB_68 : 5|14@0+ (0.01,0) [0|96] "m"  PC
 SG_ WDoppler10DB_68 : 22|15@0+ (0.01,0) [0|280] "m/s"  PC
 SG_ ValidXBeamIndex_68 : 37|10@0+ (1,0) [0|0] "n/a"  PC
 SG_ ValidXBeam_68 : 23|1@0+ (1,0) [0|0] "n/a"  PC
 SG_ StdRange_68 : 49|10@0+ (0.01,0) [0|10] "m"  PC
 SG_ StdDoppler_68 : 43|10@0+ (0.01,0) [0|10] "m/s"  PC
 SG_ NoInfrastructure_68 : 38|1@0+ (1,0) [0|0] "n/a"  PC
 SG_ Infrastructure_68 : 39|1@0+ (1,0) [0|0] "n/a"  PC
 SG_ Detected_beam_number_68 : 7|2@0+ (1,0) [0|0] "n/a"  PC

BO_ 1605 MB79_TARGET_DETECTION_67D: 8 SODX
 SG_ Complex4_Re_67 : 39|16@0- (1,0) [-32768|32767] "n/a"  PC
 SG_ Complex4_Im_67 : 55|16@0- (1,0) [-32768|32767] "n/a"  PC
 SG_ Complex3_Re_67 : 7|16@0- (1,0) [-32768|32767] "n/a"  PC
 SG_ Complex3_Im_67 : 23|16@0- (1,0) [-32768|32767] "n/a"  PC

BO_ 1604 MB79_TARGET_DETECTION_67C: 8 SODX
 SG_ Complex2_Re_67 : 39|16@0- (1,0) [-32768|32767] "n/a"  PC
 SG_ Complex2_Im_67 : 55|16@0- (1,0) [-32768|32767] "n/a"  PC
 SG_ Complex1_Re_67 : 7|16@0- (1,0) [-32768|32767] "n/a"  PC
 SG_ Complex1_Im_67 : 23|16@0- (1,0) [-32768|32767] "n/a"  PC

BO_ 1603 MB79_TARGET_DETECTION_67B: 8 SODX
 SG_ StdAzimuth_67 : 63|8@0+ (0.0009766,0) [0|14.31] "°"  PC
 SG_ PowerDB_67 : 7|8@0+ (1,0) [0|255] "db"  PC
 SG_ CoGRange_67 : 15|16@0- (0.01,0) [0|96] "m"  PC
 SG_ CoGDoppler_67 : 31|16@0- (0.01,0) [-140|14] "m/s"  PC
 SG_ Azimuth_67 : 47|16@0- (0.1,0) [-180|180] "°"  PC

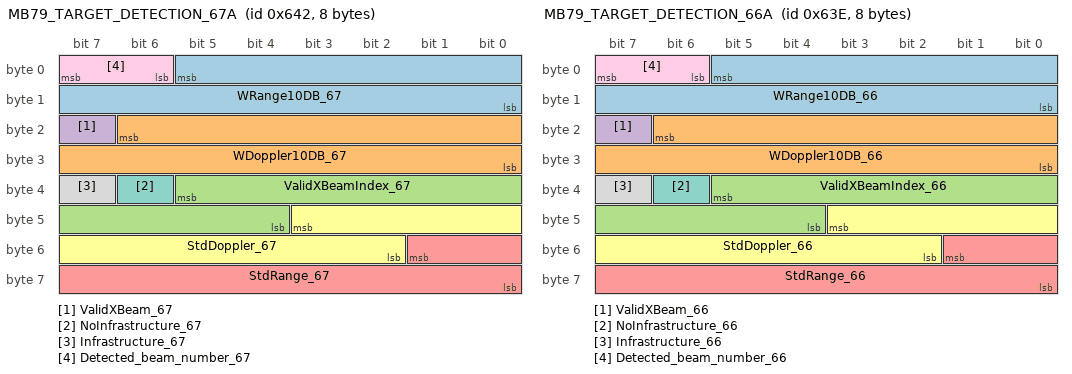
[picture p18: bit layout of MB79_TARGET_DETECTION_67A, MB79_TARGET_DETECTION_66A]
BO_ 1602 MB79_TARGET_DETECTION_67A: 8 SODX
 SG_ WRange10DB_67 : 5|14@0+ (0.01,0) [0|96] "m"  PC
 SG_ WDoppler10DB_67 : 22|15@0+ (0.01,0) [0|280] "m/s"  PC
 SG_ ValidXBeamIndex_67 : 37|10@0+ (1,0) [0|0] "n/a"  PC
 SG_ ValidXBeam_67 : 23|1@0+ (1,0) [0|0] "n/a"  PC
 SG_ StdRange_67 : 49|10@0+ (0.01,0) [0|10] "m"  PC
 SG_ StdDoppler_67 : 43|10@0+ (0.01,0) [0|10] "m/s"  PC
 SG_ NoInfrastructure_67 : 38|1@0+ (1,0) [0|0] "n/a"  PC
 SG_ Infrastructure_67 : 39|1@0+ (1,0) [0|0] "n/a"  PC
 SG_ Detected_beam_number_67 : 7|2@0+ (1,0) [0|0] "n/a"  PC

BO_ 1601 MB79_TARGET_DETECTION_66D: 8 SODX
 SG_ Complex4_Re_66 : 39|16@0- (1,0) [-32768|32767] "n/a"  PC
 SG_ Complex4_Im_66 : 55|16@0- (1,0) [-32768|32767] "n/a"  PC
 SG_ Complex3_Re_66 : 7|16@0- (1,0) [-32768|32767] "n/a"  PC
 SG_ Complex3_Im_66 : 23|16@0- (1,0) [-32768|32767] "n/a"  PC

BO_ 1600 MB79_TARGET_DETECTION_66C: 8 SODX
 SG_ Complex2_Re_66 : 39|16@0- (1,0) [-32768|32767] "n/a"  PC
 SG_ Complex2_Im_66 : 55|16@0- (1,0) [-32768|32767] "n/a"  PC
 SG_ Complex1_Re_66 : 7|16@0- (1,0) [-32768|32767] "n/a"  PC
 SG_ Complex1_Im_66 : 23|16@0- (1,0) [-32768|32767] "n/a"  PC

BO_ 1599 MB79_TARGET_DETECTION_66B: 8 SODX
 SG_ StdAzimuth_66 : 63|8@0+ (0.0009766,0) [0|14.31] "°"  PC
 SG_ PowerDB_66 : 7|8@0+ (1,0) [0|255] "db"  PC
 SG_ CoGRange_66 : 15|16@0- (0.01,0) [0|96] "m"  PC
 SG_ CoGDoppler_66 : 31|16@0- (0.01,0) [-140|14] "m/s"  PC
 SG_ Azimuth_66 : 47|16@0- (0.1,0) [-180|180] "°"  PC

BO_ 1598 MB79_TARGET_DETECTION_66A: 8 SODX
 SG_ WRange10DB_66 : 5|14@0+ (0.01,0) [0|96] "m"  PC
 SG_ WDoppler10DB_66 : 22|15@0+ (0.01,0) [0|280] "m/s"  PC
 SG_ ValidXBeamIndex_66 : 37|10@0+ (1,0) [0|0] "n/a"  PC
 SG_ ValidXBeam_66 : 23|1@0+ (1,0) [0|0] "n/a"  PC
 SG_ StdRange_66 : 49|10@0+ (0.01,0) [0|10] "m"  PC
 SG_ StdDoppler_66 : 43|10@0+ (0.01,0) [0|10] "m/s"  PC
 SG_ NoInfrastructure_66 : 38|1@0+ (1,0) [0|0] "n/a"  PC
 SG_ Infrastructure_66 : 39|1@0+ (1,0) [0|0] "n/a"  PC
 SG_ Detected_beam_number_66 : 7|2@0+ (1,0) [0|0] "n/a"  PC

BO_ 1597 MB79_TARGET_DETECTION_65D: 8 SODX
 SG_ Complex4_Re_65 : 39|16@0- (1,0) [-32768|32767] "n/a"  PC
 SG_ Complex4_Im_65 : 55|16@0- (1,0) [-32768|32767] "n/a"  PC
 SG_ Complex3_Re_65 : 7|16@0- (1,0) [-32768|32767] "n/a"  PC
 SG_ Complex3_Im_65 : 23|16@0- (1,0) [-32768|32767] "n/a"  PC

BO_ 1596 MB79_TARGET_DETECTION_65C: 8 SODX
 SG_ Complex2_Re_65 : 39|16@0- (1,0) [-32768|32767] "n/a"  PC
 SG_ Complex2_Im_65 : 55|16@0- (1,0) [-32768|32767] "n/a"  PC
 SG_ Complex1_Re_65 : 7|16@0- (1,0) [-32768|32767] "n/a"  PC
 SG_ Complex1_Im_65 : 23|16@0- (1,0) [-32768|32767] "n/a"  PC

BO_ 1595 MB79_TARGET_DETECTION_65B: 8 SODX
 SG_ StdAzimuth_65 : 63|8@0+ (0.0009766,0) [0|14.31] "°"  PC
 SG_ PowerDB_65 : 7|8@0+ (1,0) [0|255] "db"  PC
 SG_ CoGRange_65 : 15|16@0- (0.01,0) [0|96] "m"  PC
 SG_ CoGDoppler_65 : 31|16@0- (0.01,0) [-140|14] "m/s"  PC
 SG_ Azimuth_65 : 47|16@0- (0.1,0) [-180|180] "°"  PC

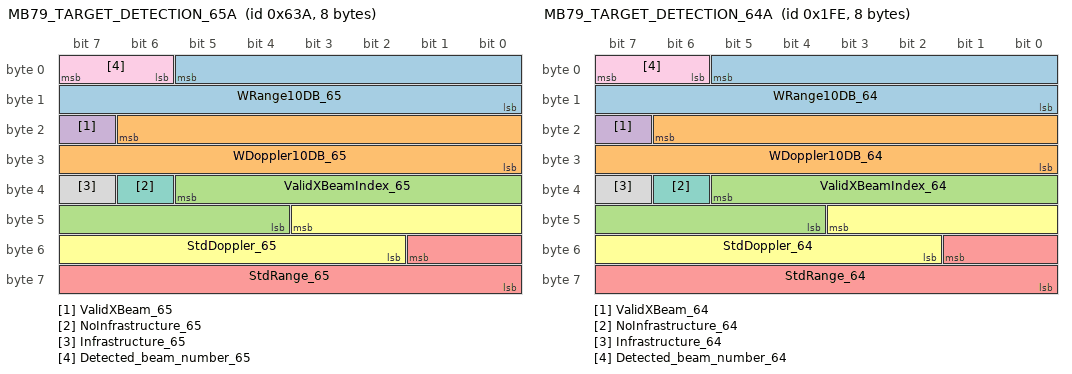
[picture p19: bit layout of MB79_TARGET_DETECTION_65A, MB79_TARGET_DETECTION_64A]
BO_ 1594 MB79_TARGET_DETECTION_65A: 8 SODX
 SG_ WRange10DB_65 : 5|14@0+ (0.01,0) [0|96] "m"  PC
 SG_ WDoppler10DB_65 : 22|15@0+ (0.01,0) [0|280] "m/s"  PC
 SG_ ValidXBeamIndex_65 : 37|10@0+ (1,0) [0|0] "n/a"  PC
 SG_ ValidXBeam_65 : 23|1@0+ (1,0) [0|0] "n/a"  PC
 SG_ StdRange_65 : 49|10@0+ (0.01,0) [0|10] "m"  PC
 SG_ StdDoppler_65 : 43|10@0+ (0.01,0) [0|10] "m/s"  PC
 SG_ NoInfrastructure_65 : 38|1@0+ (1,0) [0|0] "n/a"  PC
 SG_ Infrastructure_65 : 39|1@0+ (1,0) [0|0] "n/a"  PC
 SG_ Detected_beam_number_65 : 7|2@0+ (1,0) [0|0] "n/a"  PC

BO_ 1593 MB79_TARGET_DETECTION_64D: 8 SODX
 SG_ Complex4_Re_64 : 39|16@0- (1,0) [-32768|32767] "n/a"  PC
 SG_ Complex4_Im_64 : 55|16@0- (1,0) [-32768|32767] "n/a"  PC
 SG_ Complex3_Re_64 : 7|16@0- (1,0) [-32768|32767] "n/a"  PC
 SG_ Complex3_Im_64 : 23|16@0- (1,0) [-32768|32767] "n/a"  PC

BO_ 1592 MB79_TARGET_DETECTION_64C: 8 SODX
 SG_ Complex2_Re_64 : 39|16@0- (1,0) [-32768|32767] "n/a"  PC
 SG_ Complex2_Im_64 : 55|16@0- (1,0) [-32768|32767] "n/a"  PC
 SG_ Complex1_Re_64 : 7|16@0- (1,0) [-32768|32767] "n/a"  PC
 SG_ Complex1_Im_64 : 23|16@0- (1,0) [-32768|32767] "n/a"  PC

BO_ 511 MB79_TARGET_DETECTION_64B: 8 SODX
 SG_ StdAzimuth_64 : 63|8@0+ (0.0009766,0) [0|14.31] "°"  PC
 SG_ PowerDB_64 : 7|8@0+ (1,0) [0|255] "db"  PC
 SG_ CoGRange_64 : 15|16@0- (0.01,0) [0|96] "m"  PC
 SG_ CoGDoppler_64 : 31|16@0- (0.01,0) [-140|14] "m/s"  PC
 SG_ Azimuth_64 : 47|16@0- (0.1,0) [-180|180] "°"  PC

BO_ 510 MB79_TARGET_DETECTION_64A: 8 SODX
 SG_ WRange10DB_64 : 5|14@0+ (0.01,0) [0|96] "m"  PC
 SG_ WDoppler10DB_64 : 22|15@0+ (0.01,0) [0|280] "m/s"  PC
 SG_ ValidXBeamIndex_64 : 37|10@0+ (1,0) [0|0] "n/a"  PC
 SG_ ValidXBeam_64 : 23|1@0+ (1,0) [0|0] "n/a"  PC
 SG_ StdRange_64 : 49|10@0+ (0.01,0) [0|10] "m"  PC
 SG_ StdDoppler_64 : 43|10@0+ (0.01,0) [0|10] "m/s"  PC
 SG_ NoInfrastructure_64 : 38|1@0+ (1,0) [0|0] "n/a"  PC
 SG_ Infrastructure_64 : 39|1@0+ (1,0) [0|0] "n/a"  PC
 SG_ Detected_beam_number_64 : 7|2@0+ (1,0) [0|0] "n/a"  PC

BO_ 509 MB79_TARGET_DETECTION_63D: 8 SODX
 SG_ Complex4_Re_63 : 39|16@0- (1,0) [-32768|32767] "n/a"  PC
 SG_ Complex4_Im_63 : 55|16@0- (1,0) [-32768|32767] "n/a"  PC
 SG_ Complex3_Re_63 : 7|16@0- (1,0) [-32768|32767] "n/a"  PC
 SG_ Complex3_Im_63 : 23|16@0- (1,0) [-32768|32767] "n/a"  PC

BO_ 508 MB79_TARGET_DETECTION_63C: 8 SODX
 SG_ Complex2_Re_63 : 39|16@0- (1,0) [-32768|32767] "n/a"  PC
 SG_ Complex2_Im_63 : 55|16@0- (1,0) [-32768|32767] "n/a"  PC
 SG_ Complex1_Re_63 : 7|16@0- (1,0) [-32768|32767] "n/a"  PC
 SG_ Complex1_Im_63 : 23|16@0- (1,0) [-32768|32767] "n/a"  PC

BO_ 507 MB79_TARGET_DETECTION_63B: 8 SODX
 SG_ StdAzimuth_63 : 63|8@0+ (0.0009766,0) [0|14.31] "°"  PC
 SG_ PowerDB_63 : 7|8@0+ (1,0) [0|255] "db"  PC
 SG_ CoGRange_63 : 15|16@0- (0.01,0) [0|96] "m"  PC
 SG_ CoGDoppler_63 : 31|16@0- (0.01,0) [-140|14] "m/s"  PC
 SG_ Azimuth_63 : 47|16@0- (0.1,0) [-180|180] "°"  PC

BO_ 506 MB79_TARGET_DETECTION_63A: 8 SODX
 SG_ WRange10DB_63 : 5|14@0+ (0.01,0) [0|96] "m"  PC
 SG_ WDoppler10DB_63 : 22|15@0+ (0.01,0) [0|280] "m/s"  PC
 SG_ ValidXBeamIndex_63 : 37|10@0+ (1,0) [0|0] "n/a"  PC
 SG_ ValidXBeam_63 : 23|1@0+ (1,0) [0|0] "n/a"  PC
 SG_ StdRange_63 : 49|10@0+ (0.01,0) [0|10] "m"  PC
 SG_ StdDoppler_63 : 43|10@0+ (0.01,0) [0|10] "m/s"  PC
 SG_ NoInfrastructure_63 : 38|1@0+ (1,0) [0|0] "n/a"  PC
 SG_ Infrastructure_63 : 39|1@0+ (1,0) [0|0] "n/a"  PC
 SG_ Detected_beam_number_63 : 7|2@0+ (1,0) [0|0] "n/a"  PC

BO_ 505 MB79_TARGET_DETECTION_62D: 8 SODX
 SG_ Complex4_Re_62 : 39|16@0- (1,0) [-32768|32767] "n/a"  PC
 SG_ Complex4_Im_62 : 55|16@0- (1,0) [-32768|32767] "n/a"  PC
 SG_ Complex3_Re_62 : 7|16@0- (1,0) [-32768|32767] "n/a"  PC
 SG_ Complex3_Im_62 : 23|16@0- (1,0) [-32768|32767] "n/a"  PC

BO_ 504 MB79_TARGET_DETECTION_62C: 8 SODX
 SG_ Complex2_Re_62 : 39|16@0- (1,0) [-32768|32767] "n/a"  PC
 SG_ Complex2_Im_62 : 55|16@0- (1,0) [-32768|32767] "n/a"  PC
 SG_ Complex1_Re_62 : 7|16@0- (1,0) [-32768|32767] "n/a"  PC
 SG_ Complex1_Im_62 : 23|16@0- (1,0) [-32768|32767] "n/a"  PC

BO_ 503 MB79_TARGET_DETECTION_62B: 8 SODX
 SG_ StdAzimuth_62 : 63|8@0+ (0.0009766,0) [0|14.31] "°"  PC
 SG_ PowerDB_62 : 7|8@0+ (1,0) [0|255] "db"  PC
 SG_ CoGRange_62 : 15|16@0- (0.01,0) [0|96] "m"  PC
 SG_ CoGDoppler_62 : 31|16@0- (0.01,0) [-140|14] "m/s"  PC
 SG_ Azimuth_62 : 47|16@0- (0.1,0) [-180|180] "°"  PC

BO_ 502 MB79_TARGET_DETECTION_62A: 8 SODX
 SG_ WRange10DB_62 : 5|14@0+ (0.01,0) [0|96] "m"  PC
 SG_ WDoppler10DB_62 : 22|15@0+ (0.01,0) [0|280] "m/s"  PC
 SG_ ValidXBeamIndex_62 : 37|10@0+ (1,0) [0|0] "n/a"  PC
 SG_ ValidXBeam_62 : 23|1@0+ (1,0) [0|0] "n/a"  PC
 SG_ StdRange_62 : 49|10@0+ (0.01,0) [0|10] "m"  PC
 SG_ StdDoppler_62 : 43|10@0+ (0.01,0) [0|10] "m/s"  PC
 SG_ NoInfrastructure_62 : 38|1@0+ (1,0) [0|0] "n/a"  PC
 SG_ Infrastructure_62 : 39|1@0+ (1,0) [0|0] "n/a"  PC
 SG_ Detected_beam_number_62 : 7|2@0+ (1,0) [0|0] "n/a"  PC

BO_ 501 MB79_TARGET_DETECTION_61D: 8 SODX
 SG_ Complex4_Re_61 : 39|16@0- (1,0) [-32768|32767] "n/a"  PC
 SG_ Complex4_Im_61 : 55|16@0- (1,0) [-32768|32767] "n/a"  PC
 SG_ Complex3_Re_61 : 7|16@0- (1,0) [-32768|32767] "n/a"  PC
 SG_ Complex3_Im_61 : 23|16@0- (1,0) [-32768|32767] "n/a"  PC

BO_ 500 MB79_TARGET_DETECTION_61C: 8 SODX
 SG_ Complex2_Re_61 : 39|16@0- (1,0) [-32768|32767] "n/a"  PC
 SG_ Complex2_Im_61 : 55|16@0- (1,0) [-32768|32767] "n/a"  PC
 SG_ Complex1_Re_61 : 7|16@0- (1,0) [-32768|32767] "n/a"  PC
 SG_ Complex1_Im_61 : 23|16@0- (1,0) [-32768|32767] "n/a"  PC

BO_ 499 MB79_TARGET_DETECTION_61B: 8 SODX
 SG_ StdAzimuth_61 : 63|8@0+ (0.0009766,0) [0|14.31] "°"  PC
 SG_ PowerDB_61 : 7|8@0+ (1,0) [0|255] "db"  PC
 SG_ CoGRange_61 : 15|16@0- (0.01,0) [0|96] "m"  PC
 SG_ CoGDoppler_61 : 31|16@0- (0.01,0) [-140|14] "m/s"  PC
 SG_ Azimuth_61 : 47|16@0- (0.1,0) [-180|180] "°"  PC

BO_ 498 MB79_TARGET_DETECTION_61A: 8 SODX
 SG_ WRange10DB_61 : 5|14@0+ (0.01,0) [0|96] "m"  PC
 SG_ WDoppler10DB_61 : 22|15@0+ (0.01,0) [0|280] "m/s"  PC
 SG_ ValidXBeamIndex_61 : 37|10@0+ (1,0) [0|0] "n/a"  PC
 SG_ ValidXBeam_61 : 23|1@0+ (1,0) [0|0] "n/a"  PC
 SG_ StdRange_61 : 49|10@0+ (0.01,0) [0|10] "m"  PC
 SG_ StdDoppler_61 : 43|10@0+ (0.01,0) [0|10] "m/s"  PC
 SG_ NoInfrastructure_61 : 38|1@0+ (1,0) [0|0] "n/a"  PC
 SG_ Infrastructure_61 : 39|1@0+ (1,0) [0|0] "n/a"  PC
 SG_ Detected_beam_number_61 : 7|2@0+ (1,0) [0|0] "n/a"  PC

BO_ 497 MB79_TARGET_DETECTION_60D: 8 SODX
 SG_ Complex4_Re_60 : 39|16@0- (1,0) [-32768|32767] "n/a"  PC
 SG_ Complex4_Im_60 : 55|16@0- (1,0) [-32768|32767] "n/a"  PC
 SG_ Complex3_Re_60 : 7|16@0- (1,0) [-32768|32767] "n/a"  PC
 SG_ Complex3_Im_60 : 23|16@0- (1,0) [-32768|32767] "n/a"  PC

BO_ 496 MB79_TARGET_DETECTION_60C: 8 SODX
 SG_ Complex2_Re_60 : 39|16@0- (1,0) [-32768|32767] "n/a"  PC
 SG_ Complex2_Im_60 : 55|16@0- (1,0) [-32768|32767] "n/a"  PC
 SG_ Complex1_Re_60 : 7|16@0- (1,0) [-32768|32767] "n/a"  PC
 SG_ Complex1_Im_60 : 23|16@0- (1,0) [-32768|32767] "n/a"  PC

BO_ 495 MB79_TARGET_DETECTION_60B: 8 SODX
 SG_ StdAzimuth_60 : 63|8@0+ (0.0009766,0) [0|14.31] "°"  PC
 SG_ PowerDB_60 : 7|8@0+ (1,0) [0|255] "db"  PC
 SG_ CoGRange_60 : 15|16@0- (0.01,0) [0|96] "m"  PC
 SG_ CoGDoppler_60 : 31|16@0- (0.01,0) [-140|14] "m/s"  PC
 SG_ Azimuth_60 : 47|16@0- (0.1,0) [-180|180] "°"  PC

BO_ 494 MB79_TARGET_DETECTION_60A: 8 SODX
 SG_ WRange10DB_60 : 5|14@0+ (0.01,0) [0|96] "m"  PC
 SG_ WDoppler10DB_60 : 22|15@0+ (0.01,0) [0|280] "m/s"  PC
 SG_ ValidXBeamIndex_60 : 37|10@0+ (1,0) [0|0] "n/a"  PC
 SG_ ValidXBeam_60 : 23|1@0+ (1,0) [0|0] "n/a"  PC
 SG_ StdRange_60 : 49|10@0+ (0.01,0) [0|10] "m"  PC
 SG_ StdDoppler_60 : 43|10@0+ (0.01,0) [0|10] "m/s"  PC
 SG_ NoInfrastructure_60 : 38|1@0+ (1,0) [0|0] "n/a"  PC
 SG_ Infrastructure_60 : 39|1@0+ (1,0) [0|0] "n/a"  PC
 SG_ Detected_beam_number_60 : 7|2@0+ (1,0) [0|0] "n/a"  PC

BO_ 277 MB79_TARGET_DETECTION_5D: 8 SODX
 SG_ Complex4_Re_5 : 39|16@0- (1,0) [-32768|32767] "n/a"  PC
 SG_ Complex4_Im_5 : 55|16@0- (1,0) [-32768|32767] "n/a"  PC
 SG_ Complex3_Re_5 : 7|16@0- (1,0) [-32768|32767] "n/a"  PC
 SG_ Complex3_Im_5 : 23|16@0- (1,0) [-32768|32767] "n/a"  PC

BO_ 276 MB79_TARGET_DETECTION_5C: 8 SODX
 SG_ Complex2_Re_5 : 39|16@0- (1,0) [-32768|32767] "n/a"  PC
 SG_ Complex2_Im_5 : 55|16@0- (1,0) [-32768|32767] "n/a"  PC
 SG_ Complex1_Re_5 : 7|16@0- (1,0) [-32768|32767] "n/a"  PC
 SG_ Complex1_Im_5 : 23|16@0- (1,0) [-32768|32767] "n/a"  PC

BO_ 275 MB79_TARGET_DETECTION_5B: 8 SODX
 SG_ StdAzimuth_5 : 63|8@0+ (0.0009766,0) [0|14.31] "°"  PC
 SG_ PowerDB_5 : 7|8@0+ (1,0) [0|255] "db"  PC
 SG_ CoGRange_5 : 15|16@0- (0.01,0) [0|96] "m"  PC
 SG_ CoGDoppler_5 : 31|16@0- (0.01,0) [-140|14] "m/s"  PC
 SG_ Azimuth_5 : 47|16@0- (0.1,0) [-180|180] "°"  PC

BO_ 274 MB79_TARGET_DETECTION_5A: 8 SODX
 SG_ WRange10DB_5 : 5|14@0+ (0.01,0) [0|96] "m"  PC
 SG_ WDoppler10DB_5 : 22|15@0+ (0.01,0) [0|280] "m/s"  PC
 SG_ ValidXBeamIndex_5 : 37|10@0+ (1,0) [0|0] "n/a"  PC
 SG_ ValidXBeam_5 : 23|1@0+ (1,0) [0|0] "n/a"  PC
 SG_ StdRange_5 : 49|10@0+ (0.01,0) [0|10] "m"  PC
 SG_ StdDoppler_5 : 43|10@0+ (0.01,0) [0|10] "m/s"  PC
 SG_ NoInfrastructure_5 : 38|1@0+ (1,0) [0|0] "n/a"  PC
 SG_ Infrastructure_5 : 39|1@0+ (1,0) [0|0] "n/a"  PC
 SG_ Detected_beam_number_5 : 7|2@0+ (1,0) [0|0] "n/a"  PC

BO_ 493 MB79_TARGET_DETECTION_59D: 8 SODX
 SG_ Complex4_Re_59 : 39|16@0- (1,0) [-32768|32767] "n/a"  PC
 SG_ Complex4_Im_59 : 55|16@0- (1,0) [-32768|32767] "n/a"  PC
 SG_ Complex3_Re_59 : 7|16@0- (1,0) [-32768|32767] "n/a"  PC
 SG_ Complex3_Im_59 : 23|16@0- (1,0) [-32768|32767] "n/a"  PC

BO_ 492 MB79_TARGET_DETECTION_59C: 8 SODX
 SG_ Complex2_Re_59 : 39|16@0- (1,0) [-32768|32767] "n/a"  PC
 SG_ Complex2_Im_59 : 55|16@0- (1,0) [-32768|32767] "n/a"  PC
 SG_ Complex1_Re_59 : 7|16@0- (1,0) [-32768|32767] "n/a"  PC
 SG_ Complex1_Im_59 : 23|16@0- (1,0) [-32768|32767] "n/a"  PC

BO_ 491 MB79_TARGET_DETECTION_59B: 8 SODX
 SG_ StdAzimuth_59 : 63|8@0+ (0.0009766,0) [0|14.31] "°"  PC
 SG_ PowerDB_59 : 7|8@0+ (1,0) [0|255] "db"  PC
 SG_ CoGRange_59 : 15|16@0- (0.01,0) [0|96] "m"  PC
 SG_ CoGDoppler_59 : 31|16@0- (0.01,0) [-140|14] "m/s"  PC
 SG_ Azimuth_59 : 47|16@0- (0.1,0) [-180|180] "°"  PC

BO_ 490 MB79_TARGET_DETECTION_59A: 8 SODX
 SG_ WRange10DB_59 : 5|14@0+ (0.01,0) [0|96] "m"  PC
 SG_ WDoppler10DB_59 : 22|15@0+ (0.01,0) [0|280] "m/s"  PC
 SG_ ValidXBeamIndex_59 : 37|10@0+ (1,0) [0|0] "n/a"  PC
 SG_ ValidXBeam_59 : 23|1@0+ (1,0) [0|0] "n/a"  PC
 SG_ StdRange_59 : 49|10@0+ (0.01,0) [0|10] "m"  PC
 SG_ StdDoppler_59 : 43|10@0+ (0.01,0) [0|10] "m/s"  PC
 SG_ NoInfrastructure_59 : 38|1@0+ (1,0) [0|0] "n/a"  PC
 SG_ Infrastructure_59 : 39|1@0+ (1,0) [0|0] "n/a"  PC
 SG_ Detected_beam_number_59 : 7|2@0+ (1,0) [0|0] "n/a"  PC

BO_ 489 MB79_TARGET_DETECTION_58D: 8 SODX
 SG_ Complex4_Re_58 : 39|16@0- (1,0) [-32768|32767] "n/a"  PC
 SG_ Complex4_Im_58 : 55|16@0- (1,0) [-32768|32767] "n/a"  PC
 SG_ Complex3_Re_58 : 7|16@0- (1,0) [-32768|32767] "n/a"  PC
 SG_ Complex3_Im_58 : 23|16@0- (1,0) [-32768|32767] "n/a"  PC

BO_ 488 MB79_TARGET_DETECTION_58C: 8 SODX
 SG_ Complex2_Re_58 : 39|16@0- (1,0) [-32768|32767] "n/a"  PC
 SG_ Complex2_Im_58 : 55|16@0- (1,0) [-32768|32767] "n/a"  PC
 SG_ Complex1_Re_58 : 7|16@0- (1,0) [-32768|32767] "n/a"  PC
 SG_ Complex1_Im_58 : 23|16@0- (1,0) [-32768|32767] "n/a"  PC

BO_ 487 MB79_TARGET_DETECTION_58B: 8 SODX
 SG_ StdAzimuth_58 : 63|8@0+ (0.0009766,0) [0|14.31] "°"  PC
 SG_ PowerDB_58 : 7|8@0+ (1,0) [0|255] "db"  PC
 SG_ CoGRange_58 : 15|16@0- (0.01,0) [0|96] "m"  PC
 SG_ CoGDoppler_58 : 31|16@0- (0.01,0) [-140|14] "m/s"  PC
 SG_ Azimuth_58 : 47|16@0- (0.1,0) [-180|180] "°"  PC

BO_ 486 MB79_TARGET_DETECTION_58A: 8 SODX
 SG_ WRange10DB_58 : 5|14@0+ (0.01,0) [0|96] "m"  PC
 SG_ WDoppler10DB_58 : 22|15@0+ (0.01,0) [0|280] "m/s"  PC
 SG_ ValidXBeamIndex_58 : 37|10@0+ (1,0) [0|0] "n/a"  PC
 SG_ ValidXBeam_58 : 23|1@0+ (1,0) [0|0] "n/a"  PC
 SG_ StdRange_58 : 49|10@0+ (0.01,0) [0|10] "m"  PC
 SG_ StdDoppler_58 : 43|10@0+ (0.01,0) [0|10] "m/s"  PC
 SG_ NoInfrastructure_58 : 38|1@0+ (1,0) [0|0] "n/a"  PC
 SG_ Infrastructure_58 : 39|1@0+ (1,0) [0|0] "n/a"  PC
 SG_ Detected_beam_number_58 : 7|2@0+ (1,0) [0|0] "n/a"  PC

BO_ 485 MB79_TARGET_DETECTION_57D: 8 SODX
 SG_ Complex4_Re_57 : 39|16@0- (1,0) [-32768|32767] "n/a"  PC
 SG_ Complex4_Im_57 : 55|16@0- (1,0) [-32768|32767] "n/a"  PC
 SG_ Complex3_Re_57 : 7|16@0- (1,0) [-32768|32767] "n/a"  PC
 SG_ Complex3_Im_57 : 23|16@0- (1,0) [-32768|32767] "n/a"  PC

BO_ 484 MB79_TARGET_DETECTION_57C: 8 SODX
 SG_ Complex2_Re_57 : 39|16@0- (1,0) [-32768|32767] "n/a"  PC
 SG_ Complex2_Im_57 : 55|16@0- (1,0) [-32768|32767] "n/a"  PC
 SG_ Complex1_Re_57 : 7|16@0- (1,0) [-32768|32767] "n/a"  PC
 SG_ Complex1_Im_57 : 23|16@0- (1,0) [-32768|32767] "n/a"  PC

BO_ 483 MB79_TARGET_DETECTION_57B: 8 SODX
 SG_ StdAzimuth_57 : 63|8@0+ (0.0009766,0) [0|14.31] "°"  PC
 SG_ PowerDB_57 : 7|8@0+ (1,0) [0|255] "db"  PC
 SG_ CoGRange_57 : 15|16@0- (0.01,0) [0|96] "m"  PC
 SG_ CoGDoppler_57 : 31|16@0- (0.01,0) [-140|14] "m/s"  PC
 SG_ Azimuth_57 : 47|16@0- (0.1,0) [-180|180] "°"  PC

BO_ 482 MB79_TARGET_DETECTION_57A: 8 SODX
 SG_ WRange10DB_57 : 5|14@0+ (0.01,0) [0|96] "m"  PC
 SG_ WDoppler10DB_57 : 22|15@0+ (0.01,0) [0|280] "m/s"  PC
 SG_ ValidXBeamIndex_57 : 37|10@0+ (1,0) [0|0] "n/a"  PC
 SG_ ValidXBeam_57 : 23|1@0+ (1,0) [0|0] "n/a"  PC
 SG_ StdRange_57 : 49|10@0+ (0.01,0) [0|10] "m"  PC
 SG_ StdDoppler_57 : 43|10@0+ (0.01,0) [0|10] "m/s"  PC
 SG_ NoInfrastructure_57 : 38|1@0+ (1,0) [0|0] "n/a"  PC
 SG_ Infrastructure_57 : 39|1@0+ (1,0) [0|0] "n/a"  PC
 SG_ Detected_beam_number_57 : 7|2@0+ (1,0) [0|0] "n/a"  PC

BO_ 481 MB79_TARGET_DETECTION_56D: 8 SODX
 SG_ Complex4_Re_56 : 39|16@0- (1,0) [-32768|32767] "n/a"  PC
 SG_ Complex4_Im_56 : 55|16@0- (1,0) [-32768|32767] "n/a"  PC
 SG_ Complex3_Re_56 : 7|16@0- (1,0) [-32768|32767] "n/a"  PC
 SG_ Complex3_Im_56 : 23|16@0- (1,0) [-32768|32767] "n/a"  PC

BO_ 480 MB79_TARGET_DETECTION_56C: 8 SODX
 SG_ Complex2_Re_56 : 39|16@0- (1,0) [-32768|32767] "n/a"  PC
 SG_ Complex2_Im_56 : 55|16@0- (1,0) [-32768|32767] "n/a"  PC
 SG_ Complex1_Re_56 : 7|16@0- (1,0) [-32768|32767] "n/a"  PC
 SG_ Complex1_Im_56 : 23|16@0- (1,0) [-32768|32767] "n/a"  PC

BO_ 479 MB79_TARGET_DETECTION_56B: 8 SODX
 SG_ StdAzimuth_56 : 63|8@0+ (0.0009766,0) [0|14.31] "°"  PC
 SG_ PowerDB_56 : 7|8@0+ (1,0) [0|255] "db"  PC
 SG_ CoGRange_56 : 15|16@0- (0.01,0) [0|96] "m"  PC
 SG_ CoGDoppler_56 : 31|16@0- (0.01,0) [-140|14] "m/s"  PC
 SG_ Azimuth_56 : 47|16@0- (0.1,0) [-180|180] "°"  PC

BO_ 478 MB79_TARGET_DETECTION_56A: 8 SODX
 SG_ WRange10DB_56 : 5|14@0+ (0.01,0) [0|96] "m"  PC
 SG_ WDoppler10DB_56 : 22|15@0+ (0.01,0) [0|280] "m/s"  PC
 SG_ ValidXBeamIndex_56 : 37|10@0+ (1,0) [0|0] "n/a"  PC
 SG_ ValidXBeam_56 : 23|1@0+ (1,0) [0|0] "n/a"  PC
 SG_ StdRange_56 : 49|10@0+ (0.01,0) [0|10] "m"  PC
 SG_ StdDoppler_56 : 43|10@0+ (0.01,0) [0|10] "m/s"  PC
 SG_ NoInfrastructure_56 : 38|1@0+ (1,0) [0|0] "n/a"  PC
 SG_ Infrastructure_56 : 39|1@0+ (1,0) [0|0] "n/a"  PC
 SG_ Detected_beam_number_56 : 7|2@0+ (1,0) [0|0] "n/a"  PC

BO_ 477 MB79_TARGET_DETECTION_55D: 8 SODX
 SG_ Complex4_Re_55 : 39|16@0- (1,0) [-32768|32767] "n/a"  PC
 SG_ Complex4_Im_55 : 55|16@0- (1,0) [-32768|32767] "n/a"  PC
 SG_ Complex3_Re_55 : 7|16@0- (1,0) [-32768|32767] "n/a"  PC
 SG_ Complex3_Im_55 : 23|16@0- (1,0) [-32768|32767] "n/a"  PC

BO_ 476 MB79_TARGET_DETECTION_55C: 8 SODX
 SG_ Complex2_Re_55 : 39|16@0- (1,0) [-32768|32767] "n/a"  PC
 SG_ Complex2_Im_55 : 55|16@0- (1,0) [-32768|32767] "n/a"  PC
 SG_ Complex1_Re_55 : 7|16@0- (1,0) [-32768|32767] "n/a"  PC
 SG_ Complex1_Im_55 : 23|16@0- (1,0) [-32768|32767] "n/a"  PC

BO_ 475 MB79_TARGET_DETECTION_55B: 8 SODX
 SG_ StdAzimuth_55 : 63|8@0+ (0.0009766,0) [0|14.31] "°"  PC
 SG_ PowerDB_55 : 7|8@0+ (1,0) [0|255] "db"  PC
 SG_ CoGRange_55 : 15|16@0- (0.01,0) [0|96] "m"  PC
 SG_ CoGDoppler_55 : 31|16@0- (0.01,0) [-140|14] "m/s"  PC
 SG_ Azimuth_55 : 47|16@0- (0.1,0) [-180|180] "°"  PC

BO_ 474 MB79_TARGET_DETECTION_55A: 8 SODX
 SG_ WRange10DB_55 : 5|14@0+ (0.01,0) [0|96] "m"  PC
 SG_ WDoppler10DB_55 : 22|15@0+ (0.01,0) [0|280] "m/s"  PC
 SG_ ValidXBeamIndex_55 : 37|10@0+ (1,0) [0|0] "n/a"  PC
 SG_ ValidXBeam_55 : 23|1@0+ (1,0) [0|0] "n/a"  PC
 SG_ StdRange_55 : 49|10@0+ (0.01,0) [0|10] "m"  PC
 SG_ StdDoppler_55 : 43|10@0+ (0.01,0) [0|10] "m/s"  PC
 SG_ NoInfrastructure_55 : 38|1@0+ (1,0) [0|0] "n/a"  PC
 SG_ Infrastructure_55 : 39|1@0+ (1,0) [0|0] "n/a"  PC
 SG_ Detected_beam_number_55 : 7|2@0+ (1,0) [0|0] "n/a"  PC

BO_ 473 MB79_TARGET_DETECTION_54D: 8 SODX
 SG_ Complex4_Re_54 : 39|16@0- (1,0) [-32768|32767] "n/a"  PC
 SG_ Complex4_Im_54 : 55|16@0- (1,0) [-32768|32767] "n/a"  PC
 SG_ Complex3_Re_54 : 7|16@0- (1,0) [-32768|32767] "n/a"  PC
 SG_ Complex3_Im_54 : 23|16@0- (1,0) [-32768|32767] "n/a"  PC

BO_ 472 MB79_TARGET_DETECTION_54C: 8 SODX
 SG_ Complex2_Re_54 : 39|16@0- (1,0) [-32768|32767] "n/a"  PC
 SG_ Complex2_Im_54 : 55|16@0- (1,0) [-32768|32767] "n/a"  PC
 SG_ Complex1_Re_54 : 7|16@0- (1,0) [-32768|32767] "n/a"  PC
 SG_ Complex1_Im_54 : 23|16@0- (1,0) [-32768|32767] "n/a"  PC

BO_ 471 MB79_TARGET_DETECTION_54B: 8 SODX
 SG_ StdAzimuth_54 : 63|8@0+ (0.0009766,0) [0|14.31] "°"  PC
 SG_ PowerDB_54 : 7|8@0+ (1,0) [0|255] "db"  PC
 SG_ CoGRange_54 : 15|16@0- (0.01,0) [0|96] "m"  PC
 SG_ CoGDoppler_54 : 31|16@0- (0.01,0) [-140|14] "m/s"  PC
 SG_ Azimuth_54 : 47|16@0- (0.1,0) [-180|180] "°"  PC

BO_ 470 MB79_TARGET_DETECTION_54A: 8 SODX
 SG_ WRange10DB_54 : 5|14@0+ (0.01,0) [0|96] "m"  PC
 SG_ WDoppler10DB_54 : 22|15@0+ (0.01,0) [0|280] "m/s"  PC
 SG_ ValidXBeamIndex_54 : 37|10@0+ (1,0) [0|0] "n/a"  PC
 SG_ ValidXBeam_54 : 23|1@0+ (1,0) [0|0] "n/a"  PC
 SG_ StdRange_54 : 49|10@0+ (0.01,0) [0|10] "m"  PC
 SG_ StdDoppler_54 : 43|10@0+ (0.01,0) [0|10] "m/s"  PC
 SG_ NoInfrastructure_54 : 38|1@0+ (1,0) [0|0] "n/a"  PC
 SG_ Infrastructure_54 : 39|1@0+ (1,0) [0|0] "n/a"  PC
 SG_ Detected_beam_number_54 : 7|2@0+ (1,0) [0|0] "n/a"  PC

BO_ 469 MB79_TARGET_DETECTION_53D: 8 SODX
 SG_ Complex4_Re_53 : 39|16@0- (1,0) [-32768|32767] "n/a"  PC
 SG_ Complex4_Im_53 : 55|16@0- (1,0) [-32768|32767] "n/a"  PC
 SG_ Complex3_Re_53 : 7|16@0- (1,0) [-32768|32767] "n/a"  PC
 SG_ Complex3_Im_53 : 23|16@0- (1,0) [-32768|32767] "n/a"  PC

BO_ 468 MB79_TARGET_DETECTION_53C: 8 SODX
 SG_ Complex2_Re_53 : 39|16@0- (1,0) [-32768|32767] "n/a"  PC
 SG_ Complex2_Im_53 : 55|16@0- (1,0) [-32768|32767] "n/a"  PC
 SG_ Complex1_Re_53 : 7|16@0- (1,0) [-32768|32767] "n/a"  PC
 SG_ Complex1_Im_53 : 23|16@0- (1,0) [-32768|32767] "n/a"  PC

BO_ 467 MB79_TARGET_DETECTION_53B: 8 SODX
 SG_ StdAzimuth_53 : 63|8@0+ (0.0009766,0) [0|14.31] "°"  PC
 SG_ PowerDB_53 : 7|8@0+ (1,0) [0|255] "db"  PC
 SG_ CoGRange_53 : 15|16@0- (0.01,0) [0|96] "m"  PC
 SG_ CoGDoppler_53 : 31|16@0- (0.01,0) [-140|14] "m/s"  PC
 SG_ Azimuth_53 : 47|16@0- (0.1,0) [-180|180] "°"  PC

BO_ 466 MB79_TARGET_DETECTION_53A: 8 SODX
 SG_ WRange10DB_53 : 5|14@0+ (0.01,0) [0|96] "m"  PC
 SG_ WDoppler10DB_53 : 22|15@0+ (0.01,0) [0|280] "m/s"  PC
 SG_ ValidXBeamIndex_53 : 37|10@0+ (1,0) [0|0] "n/a"  PC
 SG_ ValidXBeam_53 : 23|1@0+ (1,0) [0|0] "n/a"  PC
 SG_ StdRange_53 : 49|10@0+ (0.01,0) [0|10] "m"  PC
 SG_ StdDoppler_53 : 43|10@0+ (0.01,0) [0|10] "m/s"  PC
 SG_ NoInfrastructure_53 : 38|1@0+ (1,0) [0|0] "n/a"  PC
 SG_ Infrastructure_53 : 39|1@0+ (1,0) [0|0] "n/a"  PC
 SG_ Detected_beam_number_53 : 7|2@0+ (1,0) [0|0] "n/a"  PC

BO_ 465 MB79_TARGET_DETECTION_52D: 8 SODX
 SG_ Complex4_Re_52 : 39|16@0- (1,0) [-32768|32767] "n/a"  PC
 SG_ Complex4_Im_52 : 55|16@0- (1,0) [-32768|32767] "n/a"  PC
 SG_ Complex3_Re_52 : 7|16@0- (1,0) [-32768|32767] "n/a"  PC
 SG_ Complex3_Im_52 : 23|16@0- (1,0) [-32768|32767] "n/a"  PC

BO_ 464 MB79_TARGET_DETECTION_52C: 8 SODX
 SG_ Complex2_Re_52 : 39|16@0- (1,0) [-32768|32767] "n/a"  PC
 SG_ Complex2_Im_52 : 55|16@0- (1,0) [-32768|32767] "n/a"  PC
 SG_ Complex1_Re_52 : 7|16@0- (1,0) [-32768|32767] "n/a"  PC
 SG_ Complex1_Im_52 : 23|16@0- (1,0) [-32768|32767] "n/a"  PC

BO_ 463 MB79_TARGET_DETECTION_52B: 8 SODX
 SG_ StdAzimuth_52 : 63|8@0+ (0.0009766,0) [0|14.31] "°"  PC
 SG_ PowerDB_52 : 7|8@0+ (1,0) [0|255] "db"  PC
 SG_ CoGRange_52 : 15|16@0- (0.01,0) [0|96] "m"  PC
 SG_ CoGDoppler_52 : 31|16@0- (0.01,0) [-140|14] "m/s"  PC
 SG_ Azimuth_52 : 47|16@0- (0.1,0) [-180|180] "°"  PC

BO_ 462 MB79_TARGET_DETECTION_52A: 8 SODX
 SG_ WRange10DB_52 : 5|14@0+ (0.01,0) [0|96] "m"  PC
 SG_ WDoppler10DB_52 : 22|15@0+ (0.01,0) [0|280] "m/s"  PC
 SG_ ValidXBeamIndex_52 : 37|10@0+ (1,0) [0|0] "n/a"  PC
 SG_ ValidXBeam_52 : 23|1@0+ (1,0) [0|0] "n/a"  PC
 SG_ StdRange_52 : 49|10@0+ (0.01,0) [0|10] "m"  PC
 SG_ StdDoppler_52 : 43|10@0+ (0.01,0) [0|10] "m/s"  PC
 SG_ NoInfrastructure_52 : 38|1@0+ (1,0) [0|0] "n/a"  PC
 SG_ Infrastructure_52 : 39|1@0+ (1,0) [0|0] "n/a"  PC
 SG_ Detected_beam_number_52 : 7|2@0+ (1,0) [0|0] "n/a"  PC

BO_ 461 MB79_TARGET_DETECTION_51D: 8 SODX
 SG_ Complex4_Re_51 : 39|16@0- (1,0) [-32768|32767] "n/a"  PC
 SG_ Complex4_Im_51 : 55|16@0- (1,0) [-32768|32767] "n/a"  PC
 SG_ Complex3_Re_51 : 7|16@0- (1,0) [-32768|32767] "n/a"  PC
 SG_ Complex3_Im_51 : 23|16@0- (1,0) [-32768|32767] "n/a"  PC

BO_ 460 MB79_TARGET_DETECTION_51C: 8 SODX
 SG_ Complex2_Re_51 : 39|16@0- (1,0) [-32768|32767] "n/a"  PC
 SG_ Complex2_Im_51 : 55|16@0- (1,0) [-32768|32767] "n/a"  PC
 SG_ Complex1_Re_51 : 7|16@0- (1,0) [-32768|32767] "n/a"  PC
 SG_ Complex1_Im_51 : 23|16@0- (1,0) [-32768|32767] "n/a"  PC

BO_ 459 MB79_TARGET_DETECTION_51B: 8 SODX
 SG_ StdAzimuth_51 : 63|8@0+ (0.0009766,0) [0|14.31] "°"  PC
 SG_ PowerDB_51 : 7|8@0+ (1,0) [0|255] "db"  PC
 SG_ CoGRange_51 : 15|16@0- (0.01,0) [0|96] "m"  PC
 SG_ CoGDoppler_51 : 31|16@0- (0.01,0) [-140|14] "m/s"  PC
 SG_ Azimuth_51 : 47|16@0- (0.1,0) [-180|180] "°"  PC

BO_ 458 MB79_TARGET_DETECTION_51A: 8 SODX
 SG_ WRange10DB_51 : 5|14@0+ (0.01,0) [0|96] "m"  PC
 SG_ WDoppler10DB_51 : 22|15@0+ (0.01,0) [0|280] "m/s"  PC
 SG_ ValidXBeamIndex_51 : 37|10@0+ (1,0) [0|0] "n/a"  PC
 SG_ ValidXBeam_51 : 23|1@0+ (1,0) [0|0] "n/a"  PC
 SG_ StdRange_51 : 49|10@0+ (0.01,0) [0|10] "m"  PC
 SG_ StdDoppler_51 : 43|10@0+ (0.01,0) [0|10] "m/s"  PC
 SG_ NoInfrastructure_51 : 38|1@0+ (1,0) [0|0] "n/a"  PC
 SG_ Infrastructure_51 : 39|1@0+ (1,0) [0|0] "n/a"  PC
 SG_ Detected_beam_number_51 : 7|2@0+ (1,0) [0|0] "n/a"  PC

BO_ 457 MB79_TARGET_DETECTION_50D: 8 SODX
 SG_ Complex4_Re_50 : 39|16@0- (1,0) [-32768|32767] "n/a"  PC
 SG_ Complex4_Im_50 : 55|16@0- (1,0) [-32768|32767] "n/a"  PC
 SG_ Complex3_Re_50 : 7|16@0- (1,0) [-32768|32767] "n/a"  PC
 SG_ Complex3_Im_50 : 23|16@0- (1,0) [-32768|32767] "n/a"  PC

BO_ 456 MB79_TARGET_DETECTION_50C: 8 SODX
 SG_ Complex2_Re_50 : 39|16@0- (1,0) [-32768|32767] "n/a"  PC
 SG_ Complex2_Im_50 : 55|16@0- (1,0) [-32768|32767] "n/a"  PC
 SG_ Complex1_Re_50 : 7|16@0- (1,0) [-32768|32767] "n/a"  PC
 SG_ Complex1_Im_50 : 23|16@0- (1,0) [-32768|32767] "n/a"  PC

BO_ 455 MB79_TARGET_DETECTION_50B: 8 SODX
 SG_ StdAzimuth_50 : 63|8@0+ (0.0009766,0) [0|14.31] "°"  PC
 SG_ PowerDB_50 : 7|8@0+ (1,0) [0|255] "db"  PC
 SG_ CoGRange_50 : 15|16@0- (0.01,0) [0|96] "m"  PC
 SG_ CoGDoppler_50 : 31|16@0- (0.01,0) [-140|14] "m/s"  PC
 SG_ Azimuth_50 : 47|16@0- (0.1,0) [-180|180] "°"  PC

BO_ 454 MB79_TARGET_DETECTION_50A: 8 SODX
 SG_ WRange10DB_50 : 5|14@0+ (0.01,0) [0|96] "m"  PC
 SG_ WDoppler10DB_50 : 22|15@0+ (0.01,0) [0|280] "m/s"  PC
 SG_ ValidXBeamIndex_50 : 37|10@0+ (1,0) [0|0] "n/a"  PC
 SG_ ValidXBeam_50 : 23|1@0+ (1,0) [0|0] "n/a"  PC
 SG_ StdRange_50 : 49|10@0+ (0.01,0) [0|10] "m"  PC
 SG_ StdDoppler_50 : 43|10@0+ (0.01,0) [0|10] "m/s"  PC
 SG_ NoInfrastructure_50 : 38|1@0+ (1,0) [0|0] "n/a"  PC
 SG_ Infrastructure_50 : 39|1@0+ (1,0) [0|0] "n/a"  PC
 SG_ Detected_beam_number_50 : 7|2@0+ (1,0) [0|0] "n/a"  PC

BO_ 273 MB79_TARGET_DETECTION_4D: 8 SODX
 SG_ Complex4_Re_4 : 39|16@0- (1,0) [-32768|32767] "n/a"  PC
 SG_ Complex4_Im_4 : 55|16@0- (1,0) [-32768|32767] "n/a"  PC
 SG_ Complex3_Re_4 : 7|16@0- (1,0) [-32768|32767] "n/a"  PC
 SG_ Complex3_Im_4 : 23|16@0- (1,0) [-32768|32767] "n/a"  PC

BO_ 272 MB79_TARGET_DETECTION_4C: 8 SODX
 SG_ Complex2_Re_4 : 39|16@0- (1,0) [-32768|32767] "n/a"  PC
 SG_ Complex2_Im_4 : 55|16@0- (1,0) [-32768|32767] "n/a"  PC
 SG_ Complex1_Re_4 : 7|16@0- (1,0) [-32768|32767] "n/a"  PC
 SG_ Complex1_Im_4 : 23|16@0- (1,0) [-32768|32767] "n/a"  PC

CM_ BO_ 257 "The Target Detection List Header transmits the informationen about the number of target detections and the actual major cycle count";
CM_ SG_ 257 NumOfDetectionsTransmitted "The number of detections in this majorcycle which are transmitted via CAN";
CM_ SG_ 257 NumOfDetectionsInternal "The number of detections in this majorcycle which are handled sensor internal.";
CM_ SG_ 257 MCC "The internal sequence counter of the MBM sensor";
CM_ BO_ 256 "This message contains the time stamp of the detection list.
";
CM_ SG_ 293 Complex4_Re_9 "Complex FFT data (Re, Im) Rx channel 4";
CM_ SG_ 293 Complex4_Im_9 "Complex FFT data (Re, Im) Rx channel 4";
CM_ SG_ 293 Complex3_Re_9 "Complex FFT data (Re, Im) Rx channel 3";
CM_ SG_ 293 Complex3_Im_9 "Complex FFT data (Re, Im) Rx channel 3";
CM_ SG_ 292 Complex2_Re_9 "Complex FFT data (Re, Im) Rx channel 2";
CM_ SG_ 292 Complex2_Im_9 "Complex FFT data (Re, Im) Rx channel 2";
CM_ SG_ 292 Complex1_Re_9 "Complex FFT data (Re, Im) Rx channel 1";
CM_ SG_ 292 Complex1_Im_9 "Complex FFT data (Re, Im) Rx channel 1";
CM_ SG_ 291 StdAzimuth_9 "Standard deviation of azimuth (in °)";
CM_ SG_ 291 PowerDB_9 "Power of detection in db";
CM_ SG_ 291 CoGRange_9 "Center of gravity range (in m)";
CM_ SG_ 291 CoGDoppler_9 "Center of gravity Doppler (in m/s)";
CM_ SG_ 291 Azimuth_9 "Azimuth angle of detection (in degree in driving direction coordinate system)";
CM_ SG_ 290 WRange10DB_9 "10 dB width of detection in range dimension (in m)";
CM_ SG_ 290 WDoppler10DB_9 "10 dB width of detection in Doppler dimension (in m/s)";
CM_ SG_ 290 ValidXBeamIndex_9 "Corresponding Index of in detection list of other beam";
CM_ SG_ 290 ValidXBeam_9 "Validated by detection in other beam/measurement";
CM_ SG_ 290 StdRange_9 "Standard deviation of range measurement (m)";
CM_ SG_ 290 StdDoppler_9 "Standard deviation of Doppler measurement (in m/s)";
CM_ SG_ 290 NoInfrastructure_9 "Target is moving (with high confidence)";
CM_ SG_ 290 Infrastructure_9 "Target is stationary (infrastructure)";
CM_ SG_ 1733 Complex4_Re_99 "Complex FFT data (Re, Im) Rx channel 4";
CM_ SG_ 1733 Complex4_Im_99 "Complex FFT data (Re, Im) Rx channel 4";
CM_ SG_ 1733 Complex3_Re_99 "Complex FFT data (Re, Im) Rx channel 3";
CM_ SG_ 1733 Complex3_Im_99 "Complex FFT data (Re, Im) Rx channel 3";
CM_ SG_ 1732 Complex2_Re_99 "Complex FFT data (Re, Im) Rx channel 2";
CM_ SG_ 1732 Complex2_Im_99 "Complex FFT data (Re, Im) Rx channel 2";
CM_ SG_ 1732 Complex1_Re_99 "Complex FFT data (Re, Im) Rx channel 1";
CM_ SG_ 1732 Complex1_Im_99 "Complex FFT data (Re, Im) Rx channel 1";
CM_ SG_ 1731 StdAzimuth_99 "Standard deviation of azimuth (in °)";
CM_ SG_ 1731 PowerDB_99 "Power of detection in db";
CM_ SG_ 1731 CoGRange_99 "Center of gravity range (in m)";
CM_ SG_ 1731 CoGDoppler_99 "Center of gravity Doppler (in m/s)";
CM_ SG_ 1731 Azimuth_99 "Azimuth angle of detection (in degree in driving direction coordinate system)";
CM_ SG_ 1730 WRange10DB_99 "10 dB width of detection in range dimension (in m)";
CM_ SG_ 1730 WDoppler10DB_99 "10 dB width of detection in Doppler dimension (in m/s)";
CM_ SG_ 1730 ValidXBeamIndex_99 "Corresponding Index of in detection list of other beam";
CM_ SG_ 1730 ValidXBeam_99 "Validated by detection in other beam/measurement";
CM_ SG_ 1730 StdRange_99 "Standard deviation of range measurement (m)";
CM_ SG_ 1730 StdDoppler_99 "Standard deviation of Doppler measurement (in m/s)";
CM_ SG_ 1730 NoInfrastructure_99 "Target is moving (with high confidence)";
CM_ SG_ 1730 Infrastructure_99 "Target is stationary (infrastructure)";
CM_ SG_ 1729 Complex4_Re_98 "Complex FFT data (Re, Im) Rx channel 4";
CM_ SG_ 1729 Complex4_Im_98 "Complex FFT data (Re, Im) Rx channel 4";
CM_ SG_ 1729 Complex3_Re_98 "Complex FFT data (Re, Im) Rx channel 3";
CM_ SG_ 1729 Complex3_Im_98 "Complex FFT data (Re, Im) Rx channel 3";
CM_ SG_ 1728 Complex2_Re_98 "Complex FFT data (Re, Im) Rx channel 2";
CM_ SG_ 1728 Complex2_Im_98 "Complex FFT data (Re, Im) Rx channel 2";
CM_ SG_ 1728 Complex1_Re_98 "Complex FFT data (Re, Im) Rx channel 1";
CM_ SG_ 1728 Complex1_Im_98 "Complex FFT data (Re, Im) Rx channel 1";
CM_ SG_ 1727 StdAzimuth_98 "Standard deviation of azimuth (in °)";
CM_ SG_ 1727 PowerDB_98 "Power of detection in db";
CM_ SG_ 1727 CoGRange_98 "Center of gravity range (in m)";
CM_ SG_ 1727 CoGDoppler_98 "Center of gravity Doppler (in m/s)";
CM_ SG_ 1727 Azimuth_98 "Azimuth angle of detection (in degree in driving direction coordinate system)";
CM_ SG_ 1726 WRange10DB_98 "10 dB width of detection in range dimension (in m)";
CM_ SG_ 1726 WDoppler10DB_98 "10 dB width of detection in Doppler dimension (in m/s)";
CM_ SG_ 1726 ValidXBeamIndex_98 "Corresponding Index of in detection list of other beam";
CM_ SG_ 1726 ValidXBeam_98 "Validated by detection in other beam/measurement";
CM_ SG_ 1726 StdRange_98 "Standard deviation of range measurement (m)";
CM_ SG_ 1726 StdDoppler_98 "Standard deviation of Doppler measurement (in m/s)";
CM_ SG_ 1726 NoInfrastructure_98 "Target is moving (with high confidence)";
CM_ SG_ 1726 Infrastructure_98 "Target is stationary (infrastructure)";
CM_ SG_ 1725 Complex4_Re_97 "Complex FFT data (Re, Im) Rx channel 4";
CM_ SG_ 1725 Complex4_Im_97 "Complex FFT data (Re, Im) Rx channel 4";
CM_ SG_ 1725 Complex3_Re_97 "Complex FFT data (Re, Im) Rx channel 3";
CM_ SG_ 1725 Complex3_Im_97 "Complex FFT data (Re, Im) Rx channel 3";
CM_ SG_ 1724 Complex2_Re_97 "Complex FFT data (Re, Im) Rx channel 2";
CM_ SG_ 1724 Complex2_Im_97 "Complex FFT data (Re, Im) Rx channel 2";
CM_ SG_ 1724 Complex1_Re_97 "Complex FFT data (Re, Im) Rx channel 1";
CM_ SG_ 1724 Complex1_Im_97 "Complex FFT data (Re, Im) Rx channel 1";
CM_ SG_ 1723 StdAzimuth_97 "Standard deviation of azimuth (in °)";
CM_ SG_ 1723 PowerDB_97 "Power of detection in db";
CM_ SG_ 1723 CoGRange_97 "Center of gravity range (in m)";
CM_ SG_ 1723 CoGDoppler_97 "Center of gravity Doppler (in m/s)";
CM_ SG_ 1723 Azimuth_97 "Azimuth angle of detection (in degree in driving direction coordinate system)";
CM_ SG_ 1722 WRange10DB_97 "10 dB width of detection in range dimension (in m)";
CM_ SG_ 1722 WDoppler10DB_97 "10 dB width of detection in Doppler dimension (in m/s)";
CM_ SG_ 1722 ValidXBeamIndex_97 "Corresponding Index of in detection list of other beam";
CM_ SG_ 1722 ValidXBeam_97 "Validated by detection in other beam/measurement";
CM_ SG_ 1722 StdRange_97 "Standard deviation of range measurement (m)";
CM_ SG_ 1722 StdDoppler_97 "Standard deviation of Doppler measurement (in m/s)";
CM_ SG_ 1722 NoInfrastructure_97 "Target is moving (with high confidence)";
CM_ SG_ 1722 Infrastructure_97 "Target is stationary (infrastructure)";
CM_ SG_ 1721 Complex4_Re_96 "Complex FFT data (Re, Im) Rx channel 4";
CM_ SG_ 1721 Complex4_Im_96 "Complex FFT data (Re, Im) Rx channel 4";
CM_ SG_ 1721 Complex3_Re_96 "Complex FFT data (Re, Im) Rx channel 3";
CM_ SG_ 1721 Complex3_Im_96 "Complex FFT data (Re, Im) Rx channel 3";
CM_ SG_ 1720 Complex2_Re_96 "Complex FFT data (Re, Im) Rx channel 2";
CM_ SG_ 1720 Complex2_Im_96 "Complex FFT data (Re, Im) Rx channel 2";
CM_ SG_ 1720 Complex1_Re_96 "Complex FFT data (Re, Im) Rx channel 1";
CM_ SG_ 1720 Complex1_Im_96 "Complex FFT data (Re, Im) Rx channel 1";
CM_ SG_ 1719 StdAzimuth_96 "Standard deviation of azimuth (in °)";
CM_ SG_ 1719 PowerDB_96 "Power of detection in db";
CM_ SG_ 1719 CoGRange_96 "Center of gravity range (in m)";
CM_ SG_ 1719 CoGDoppler_96 "Center of gravity Doppler (in m/s)";
CM_ SG_ 1719 Azimuth_96 "Azimuth angle of detection (in degree in driving direction coordinate system)";
CM_ SG_ 1718 WRange10DB_96 "10 dB width of detection in range dimension (in cm)";
CM_ SG_ 1718 WDoppler10DB_96 "10 dB width of detection in Doppler dimension (in m/s)";
CM_ SG_ 1718 ValidXBeamIndex_96 "Corresponding Index of in detection list of other beam";
CM_ SG_ 1718 ValidXBeam_96 "Validated by detection in other beam/measurement";
CM_ SG_ 1718 StdRange_96 "Standard deviation of range measurement (m)";
CM_ SG_ 1718 StdDoppler_96 "Standard deviation of Doppler measurement (in m/s)";
CM_ SG_ 1718 NoInfrastructure_96 "Target is moving (with high confidence)";
CM_ SG_ 1718 Infrastructure_96 "Target is stationary (infrastructure)";
CM_ SG_ 1717 Complex4_Re_95 "Complex FFT data (Re, Im) Rx channel 4";
CM_ SG_ 1717 Complex4_Im_95 "Complex FFT data (Re, Im) Rx channel 4";
CM_ SG_ 1717 Complex3_Re_95 "Complex FFT data (Re, Im) Rx channel 3";
CM_ SG_ 1717 Complex3_Im_95 "Complex FFT data (Re, Im) Rx channel 3";
CM_ SG_ 1716 Complex2_Re_95 "Complex FFT data (Re, Im) Rx channel 2";
CM_ SG_ 1716 Complex2_Im_95 "Complex FFT data (Re, Im) Rx channel 2";
CM_ SG_ 1716 Complex1_Re_95 "Complex FFT data (Re, Im) Rx channel 1";
CM_ SG_ 1716 Complex1_Im_95 "Complex FFT data (Re, Im) Rx channel 1";
CM_ SG_ 1715 StdAzimuth_95 "Standard deviation of azimuth (in °)";
CM_ SG_ 1715 PowerDB_95 "Power of detection in db";
CM_ SG_ 1715 CoGRange_95 "Center of gravity range (in m)";
CM_ SG_ 1715 CoGDoppler_95 "Center of gravity Doppler (in m/s)";
CM_ SG_ 1715 Azimuth_95 "Azimuth angle of detection (in degree in driving direction coordinate system)";
CM_ SG_ 1714 WRange10DB_95 "10 dB width of detection in range dimension (in m)";
CM_ SG_ 1714 WDoppler10DB_95 "10 dB width of detection in Doppler dimension (in m/s)";
CM_ SG_ 1714 ValidXBeamIndex_95 "Corresponding Index of in detection list of other beam";
CM_ SG_ 1714 ValidXBeam_95 "Validated by detection in other beam/measurement";
CM_ SG_ 1714 StdRange_95 "Standard deviation of range measurement (m)";
CM_ SG_ 1714 StdDoppler_95 "Standard deviation of Doppler measurement (in m/s)";
CM_ SG_ 1714 NoInfrastructure_95 "Target is moving (with high confidence)";
CM_ SG_ 1714 Infrastructure_95 "Target is stationary (infrastructure)";
CM_ SG_ 1713 Complex4_Re_94 "Complex FFT data (Re, Im) Rx channel 4";
CM_ SG_ 1713 Complex4_Im_94 "Complex FFT data (Re, Im) Rx channel 4";
CM_ SG_ 1713 Complex3_Re_94 "Complex FFT data (Re, Im) Rx channel 3";
CM_ SG_ 1713 Complex3_Im_94 "Complex FFT data (Re, Im) Rx channel 3";
CM_ SG_ 1712 Complex2_Re_94 "Complex FFT data (Re, Im) Rx channel 2";
CM_ SG_ 1712 Complex2_Im_94 "Complex FFT data (Re, Im) Rx channel 2";
CM_ SG_ 1712 Complex1_Re_94 "Complex FFT data (Re, Im) Rx channel 1";
CM_ SG_ 1712 Complex1_Im_94 "Complex FFT data (Re, Im) Rx channel 1";
CM_ SG_ 1711 StdAzimuth_94 "Standard deviation of azimuth (in °)";
CM_ SG_ 1711 PowerDB_94 "Power of detection in db";
CM_ SG_ 1711 CoGRange_94 "Center of gravity range (in m)";
CM_ SG_ 1711 CoGDoppler_94 "Center of gravity Doppler (in m/s)";
CM_ SG_ 1711 Azimuth_94 "Azimuth angle of detection (in degree in driving direction coordinate system)";
CM_ SG_ 1710 WRange10DB_94 "10 dB width of detection in range dimension (in m)";
CM_ SG_ 1710 WDoppler10DB_94 "10 dB width of detection in Doppler dimension (in m/s)";
CM_ SG_ 1710 ValidXBeamIndex_94 "Corresponding Index of in detection list of other beam";
CM_ SG_ 1710 ValidXBeam_94 "Validated by detection in other beam/measurement";
CM_ SG_ 1710 StdRange_94 "Standard deviation of range measurement (m)";
CM_ SG_ 1710 StdDoppler_94 "Standard deviation of Doppler measurement (in m/s)";
CM_ SG_ 1710 NoInfrastructure_94 "Target is moving (with high confidence)";
CM_ SG_ 1710 Infrastructure_94 "Target is stationary (infrastructure)";
CM_ SG_ 1709 Complex4_Re_93 "Complex FFT data (Re, Im) Rx channel 4";
CM_ SG_ 1709 Complex4_Im_93 "Complex FFT data (Re, Im) Rx channel 4";
CM_ SG_ 1709 Complex3_Re_93 "Complex FFT data (Re, Im) Rx channel 3";
CM_ SG_ 1709 Complex3_Im_93 "Complex FFT data (Re, Im) Rx channel 3";
CM_ SG_ 1708 Complex2_Re_93 "Complex FFT data (Re, Im) Rx channel 2";
CM_ SG_ 1708 Complex2_Im_93 "Complex FFT data (Re, Im) Rx channel 2";
CM_ SG_ 1708 Complex1_Re_93 "Complex FFT data (Re, Im) Rx channel 1";
CM_ SG_ 1708 Complex1_Im_93 "Complex FFT data (Re, Im) Rx channel 1";
CM_ SG_ 1707 StdAzimuth_93 "Standard deviation of azimuth (in °)";
CM_ SG_ 1707 PowerDB_93 "Power of detection in db";
CM_ SG_ 1707 CoGRange_93 "Center of gravity range (in m)";
CM_ SG_ 1707 CoGDoppler_93 "Center of gravity Doppler (in m/s)";
CM_ SG_ 1707 Azimuth_93 "Azimuth angle of detection (in degree in driving direction coordinate system)";
CM_ SG_ 1706 WRange10DB_93 "10 dB width of detection in range dimension (in m)";
CM_ SG_ 1706 WDoppler10DB_93 "10 dB width of detection in Doppler dimension (in m/s)";
CM_ SG_ 1706 ValidXBeamIndex_93 "Corresponding Index of in detection list of other beam";
CM_ SG_ 1706 ValidXBeam_93 "Validated by detection in other beam/measurement";
CM_ SG_ 1706 StdRange_93 "Standard deviation of range measurement (m)";
CM_ SG_ 1706 StdDoppler_93 "Standard deviation of Doppler measurement (in m/s)";
CM_ SG_ 1706 NoInfrastructure_93 "Target is moving (with high confidence)";
CM_ SG_ 1706 Infrastructure_93 "Target is stationary (infrastructure)";
CM_ SG_ 1705 Complex4_Re_92 "Complex FFT data (Re, Im) Rx channel 4";
CM_ SG_ 1705 Complex4_Im_92 "Complex FFT data (Re, Im) Rx channel 4";
CM_ SG_ 1705 Complex3_Re_92 "Complex FFT data (Re, Im) Rx channel 3";
CM_ SG_ 1705 Complex3_Im_92 "Complex FFT data (Re, Im) Rx channel 3";
CM_ SG_ 1704 Complex2_Re_92 "Complex FFT data (Re, Im) Rx channel 2";
CM_ SG_ 1704 Complex2_Im_92 "Complex FFT data (Re, Im) Rx channel 2";
CM_ SG_ 1704 Complex1_Re_92 "Complex FFT data (Re, Im) Rx channel 1";
CM_ SG_ 1704 Complex1_Im_92 "Complex FFT data (Re, Im) Rx channel 1";
CM_ SG_ 1703 StdAzimuth_92 "Standard deviation of azimuth (in °)";
CM_ SG_ 1703 PowerDB_92 "Power of detection in db";
CM_ SG_ 1703 CoGRange_92 "Center of gravity range (in m)";
CM_ SG_ 1703 CoGDoppler_92 "Center of gravity Doppler (in m/s)";
CM_ SG_ 1703 Azimuth_92 "Azimuth angle of detection (in degree in driving direction coordinate system)";
CM_ SG_ 1702 WRange10DB_92 "10 dB width of detection in range dimension (in m)";
CM_ SG_ 1702 WDoppler10DB_92 "10 dB width of detection in Doppler dimension (in m/s)";
CM_ SG_ 1702 ValidXBeamIndex_92 "Corresponding Index of in detection list of other beam";
CM_ SG_ 1702 ValidXBeam_92 "Validated by detection in other beam/measurement";
CM_ SG_ 1702 StdRange_92 "Standard deviation of range measurement (m)";
CM_ SG_ 1702 StdDoppler_92 "Standard deviation of Doppler measurement (in m/s)";
CM_ SG_ 1702 NoInfrastructure_92 "Target is moving (with high confidence)";
CM_ SG_ 1702 Infrastructure_92 "Target is stationary (infrastructure)";
CM_ SG_ 1701 Complex4_Re_91 "Complex FFT data (Re, Im) Rx channel 4";
CM_ SG_ 1701 Complex4_Im_91 "Complex FFT data (Re, Im) Rx channel 4";
CM_ SG_ 1701 Complex3_Re_91 "Complex FFT data (Re, Im) Rx channel 3";
CM_ SG_ 1701 Complex3_Im_91 "Complex FFT data (Re, Im) Rx channel 3";
CM_ SG_ 1700 Complex2_Re_91 "Complex FFT data (Re, Im) Rx channel 2";
CM_ SG_ 1700 Complex2_Im_91 "Complex FFT data (Re, Im) Rx channel 2";
CM_ SG_ 1700 Complex1_Re_91 "Complex FFT data (Re, Im) Rx channel 1";
CM_ SG_ 1700 Complex1_Im_91 "Complex FFT data (Re, Im) Rx channel 1";
CM_ SG_ 1699 StdAzimuth_91 "Standard deviation of azimuth (in °)";
CM_ SG_ 1699 PowerDB_91 "Power of detection in db";
CM_ SG_ 1699 CoGRange_91 "Center of gravity range (in m)";
CM_ SG_ 1699 CoGDoppler_91 "Center of gravity Doppler (in m/s)";
CM_ SG_ 1699 Azimuth_91 "Azimuth angle of detection (in degree in driving direction coordinate system)";
CM_ SG_ 1698 WRange10DB_91 "10 dB width of detection in range dimension (in m)";
CM_ SG_ 1698 WDoppler10DB_91 "10 dB width of detection in Doppler dimension (in m/s)";
CM_ SG_ 1698 ValidXBeamIndex_91 "Corresponding Index of in detection list of other beam";
CM_ SG_ 1698 ValidXBeam_91 "Validated by detection in other beam/measurement";
CM_ SG_ 1698 StdRange_91 "Standard deviation of range measurement (m)";
CM_ SG_ 1698 StdDoppler_91 "Standard deviation of Doppler measurement (in m/s)";
CM_ SG_ 1698 NoInfrastructure_91 "Target is moving (with high confidence)";
CM_ SG_ 1698 Infrastructure_91 "Target is stationary (infrastructure)";
CM_ SG_ 1697 Complex4_Re_90 "Complex FFT data (Re, Im) Rx channel 4";
CM_ SG_ 1697 Complex4_Im_90 "Complex FFT data (Re, Im) Rx channel 4";
CM_ SG_ 1697 Complex3_Re_90 "Complex FFT data (Re, Im) Rx channel 3";
CM_ SG_ 1697 Complex3_Im_90 "Complex FFT data (Re, Im) Rx channel 3";
CM_ SG_ 1696 Complex2_Re_90 "Complex FFT data (Re, Im) Rx channel 2";
CM_ SG_ 1696 Complex2_Im_90 "Complex FFT data (Re, Im) Rx channel 2";
CM_ SG_ 1696 Complex1_Re_90 "Complex FFT data (Re, Im) Rx channel 1";
CM_ SG_ 1696 Complex1_Im_90 "Complex FFT data (Re, Im) Rx channel 1";
CM_ SG_ 1695 StdAzimuth_90 "Standard deviation of azimuth (in °)";
CM_ SG_ 1695 PowerDB_90 "Power of detection in db";
CM_ SG_ 1695 CoGRange_90 "Center of gravity range (in m)";
CM_ SG_ 1695 CoGDoppler_90 "Center of gravity Doppler (in m/s)";
CM_ SG_ 1695 Azimuth_90 "Azimuth angle of detection (in degree in driving direction coordinate system)";
CM_ SG_ 1694 WRange10DB_90 "10 dB width of detection in range dimension (in m)";
CM_ SG_ 1694 WDoppler10DB_90 "10 dB width of detection in Doppler dimension (in m/s)";
CM_ SG_ 1694 ValidXBeamIndex_90 "Corresponding Index of in detection list of other beam";
CM_ SG_ 1694 ValidXBeam_90 "Validated by detection in other beam/measurement";
CM_ SG_ 1694 StdRange_90 "Standard deviation of range measurement (m)";
CM_ SG_ 1694 StdDoppler_90 "Standard deviation of Doppler measurement (in m/s)";
CM_ SG_ 1694 NoInfrastructure_90 "Target is moving (with high confidence)";
CM_ SG_ 1694 Infrastructure_90 "Target is stationary (infrastructure)";
CM_ SG_ 289 Complex4_Re_8 "Complex FFT data (Re, Im) Rx channel 4";
CM_ SG_ 289 Complex4_Im_8 "Complex FFT data (Re, Im) Rx channel 4";
CM_ SG_ 289 Complex3_Re_8 "Complex FFT data (Re, Im) Rx channel 3";
CM_ SG_ 289 Complex3_Im_8 "Complex FFT data (Re, Im) Rx channel 3";
CM_ SG_ 288 Complex2_Re_8 "Complex FFT data (Re, Im) Rx channel 2";
CM_ SG_ 288 Complex2_Im_8 "Complex FFT data (Re, Im) Rx channel 2";
CM_ SG_ 288 Complex1_Re_8 "Complex FFT data (Re, Im) Rx channel 1";
CM_ SG_ 288 Complex1_Im_8 "Complex FFT data (Re, Im) Rx channel 1";
CM_ SG_ 287 StdAzimuth_8 "Standard deviation of azimuth (in °)";
CM_ SG_ 287 PowerDB_8 "Power of detection in db";
CM_ SG_ 287 CoGRange_8 "Center of gravity range (in m)";
CM_ SG_ 287 CoGDoppler_8 "Center of gravity Doppler (in m/s)";
CM_ SG_ 287 Azimuth_8 "Azimuth angle of detection (in degree in driving direction coordinate system)";
CM_ SG_ 286 WRange10DB_8 "10 dB width of detection in range dimension (in m)";
CM_ SG_ 286 WDoppler10DB_8 "10 dB width of detection in Doppler dimension (in m/s)";
CM_ SG_ 286 ValidXBeamIndex_8 "Corresponding Index of in detection list of other beam";
CM_ SG_ 286 ValidXBeam_8 "Validated by detection in other beam/measurement";
CM_ SG_ 286 StdRange_8 "Standard deviation of range measurement (m)";
CM_ SG_ 286 StdDoppler_8 "Standard deviation of Doppler measurement (in m/s)";
CM_ SG_ 286 NoInfrastructure_8 "Target is moving (with high confidence)";
CM_ SG_ 286 Infrastructure_8 "Target is stationary (infrastructure)";
CM_ SG_ 1693 Complex4_Re_89 "Complex FFT data (Re, Im) Rx channel 4";
CM_ SG_ 1693 Complex4_Im_89 "Complex FFT data (Re, Im) Rx channel 4";
CM_ SG_ 1693 Complex3_Re_89 "Complex FFT data (Re, Im) Rx channel 3";
CM_ SG_ 1693 Complex3_Im_89 "Complex FFT data (Re, Im) Rx channel 3";
CM_ SG_ 1692 Complex2_Re_89 "Complex FFT data (Re, Im) Rx channel 2";
CM_ SG_ 1692 Complex2_Im_89 "Complex FFT data (Re, Im) Rx channel 2";
CM_ SG_ 1692 Complex1_Re_89 "Complex FFT data (Re, Im) Rx channel 1";
CM_ SG_ 1692 Complex1_Im_89 "Complex FFT data (Re, Im) Rx channel 1";
CM_ SG_ 1691 StdAzimuth_89 "Standard deviation of azimuth (in °)";
CM_ SG_ 1691 PowerDB_89 "Power of detection in db";
CM_ SG_ 1691 CoGRange_89 "Center of gravity range (in m)";
CM_ SG_ 1691 CoGDoppler_89 "Center of gravity Doppler (in m/s)";
CM_ SG_ 1691 Azimuth_89 "Azimuth angle of detection (in degree in driving direction coordinate system)";
CM_ SG_ 1690 WRange10DB_89 "10 dB width of detection in range dimension (in m)";
CM_ SG_ 1690 WDoppler10DB_89 "10 dB width of detection in Doppler dimension (in m/s)";
CM_ SG_ 1690 ValidXBeamIndex_89 "Corresponding Index of in detection list of other beam";
CM_ SG_ 1690 ValidXBeam_89 "Validated by detection in other beam/measurement";
CM_ SG_ 1690 StdRange_89 "Standard deviation of range measurement (m)";
CM_ SG_ 1690 StdDoppler_89 "Standard deviation of Doppler measurement (in m/s)";
CM_ SG_ 1690 NoInfrastructure_89 "Target is moving (with high confidence)";
CM_ SG_ 1690 Infrastructure_89 "Target is stationary (infrastructure)";
CM_ SG_ 1689 Complex4_Re_88 "Complex FFT data (Re, Im) Rx channel 4";
CM_ SG_ 1689 Complex4_Im_88 "Complex FFT data (Re, Im) Rx channel 4";
CM_ SG_ 1689 Complex3_Re_88 "Complex FFT data (Re, Im) Rx channel 3";
CM_ SG_ 1689 Complex3_Im_88 "Complex FFT data (Re, Im) Rx channel 3";
CM_ SG_ 1688 Complex2_Re_88 "Complex FFT data (Re, Im) Rx channel 2";
CM_ SG_ 1688 Complex2_Im_88 "Complex FFT data (Re, Im) Rx channel 2";
CM_ SG_ 1688 Complex1_Re_88 "Complex FFT data (Re, Im) Rx channel 1";
CM_ SG_ 1688 Complex1_Im_88 "Complex FFT data (Re, Im) Rx channel 1";
CM_ SG_ 1687 StdAzimuth_88 "Standard deviation of azimuth (in °)";
CM_ SG_ 1687 PowerDB_88 "Power of detection in db";
CM_ SG_ 1687 CoGRange_88 "Center of gravity range (in m)";
CM_ SG_ 1687 CoGDoppler_88 "Center of gravity Doppler (in m/s)";
CM_ SG_ 1687 Azimuth_88 "Azimuth angle of detection (in degree in driving direction coordinate system)";
CM_ SG_ 1686 WRange10DB_88 "10 dB width of detection in range dimension (in m)";
CM_ SG_ 1686 WDoppler10DB_88 "10 dB width of detection in Doppler dimension (in m/s)";
CM_ SG_ 1686 ValidXBeamIndex_88 "Corresponding Index of in detection list of other beam";
CM_ SG_ 1686 ValidXBeam_88 "Validated by detection in other beam/measurement";
CM_ SG_ 1686 StdRange_88 "Standard deviation of range measurement (m)";
CM_ SG_ 1686 StdDoppler_88 "Standard deviation of Doppler measurement (in m/s)";
CM_ SG_ 1686 NoInfrastructure_88 "Target is moving (with high confidence)";
CM_ SG_ 1686 Infrastructure_88 "Target is stationary (infrastructure)";
CM_ SG_ 1685 Complex4_Re_87 "Complex FFT data (Re, Im) Rx channel 4";
CM_ SG_ 1685 Complex4_Im_87 "Complex FFT data (Re, Im) Rx channel 4";
CM_ SG_ 1685 Complex3_Re_87 "Complex FFT data (Re, Im) Rx channel 3";
CM_ SG_ 1685 Complex3_Im_87 "Complex FFT data (Re, Im) Rx channel 3";
CM_ SG_ 1684 Complex2_Re_87 "Complex FFT data (Re, Im) Rx channel 2";
CM_ SG_ 1684 Complex2_Im_87 "Complex FFT data (Re, Im) Rx channel 2";
CM_ SG_ 1684 Complex1_Re_87 "Complex FFT data (Re, Im) Rx channel 1";
CM_ SG_ 1684 Complex1_Im_87 "Complex FFT data (Re, Im) Rx channel 1";
CM_ SG_ 1683 StdAzimuth_87 "Standard deviation of azimuth (in °)";
CM_ SG_ 1683 PowerDB_87 "Power of detection in db";
CM_ SG_ 1683 CoGRange_87 "Center of gravity range (in m)";
CM_ SG_ 1683 CoGDoppler_87 "Center of gravity Doppler (in m/s)";
CM_ SG_ 1683 Azimuth_87 "Azimuth angle of detection (in degree in driving direction coordinate system)";
CM_ SG_ 1682 WRange10DB_87 "10 dB width of detection in range dimension (in m)";
CM_ SG_ 1682 WDoppler10DB_87 "10 dB width of detection in Doppler dimension (in m/s)";
CM_ SG_ 1682 ValidXBeamIndex_87 "Corresponding Index of in detection list of other beam";
CM_ SG_ 1682 ValidXBeam_87 "Validated by detection in other beam/measurement";
CM_ SG_ 1682 StdRange_87 "Standard deviation of range measurement (m)";
CM_ SG_ 1682 StdDoppler_87 "Standard deviation of Doppler measurement (in m/s)";
CM_ SG_ 1682 NoInfrastructure_87 "Target is moving (with high confidence)";
CM_ SG_ 1682 Infrastructure_87 "Target is stationary (infrastructure)";
CM_ SG_ 1681 Complex4_Re_86 "Complex FFT data (Re, Im) Rx channel 4";
CM_ SG_ 1681 Complex4_Im_86 "Complex FFT data (Re, Im) Rx channel 4";
CM_ SG_ 1681 Complex3_Re_86 "Complex FFT data (Re, Im) Rx channel 3";
CM_ SG_ 1681 Complex3_Im_86 "Complex FFT data (Re, Im) Rx channel 3";
CM_ SG_ 1680 Complex2_Re_86 "Complex FFT data (Re, Im) Rx channel 2";
CM_ SG_ 1680 Complex2_Im_86 "Complex FFT data (Re, Im) Rx channel 2";
CM_ SG_ 1680 Complex1_Re_86 "Complex FFT data (Re, Im) Rx channel 1";
CM_ SG_ 1680 Complex1_Im_86 "Complex FFT data (Re, Im) Rx channel 1";
CM_ SG_ 1679 StdAzimuth_86 "Standard deviation of azimuth (in °)";
CM_ SG_ 1679 PowerDB_86 "Power of detection in db";
CM_ SG_ 1679 CoGRange_86 "Center of gravity range (in m)";
CM_ SG_ 1679 CoGDoppler_86 "Center of gravity Doppler (in m/s)";
CM_ SG_ 1679 Azimuth_86 "Azimuth angle of detection (in degree in driving direction coordinate system)";
CM_ SG_ 1678 WRange10DB_86 "10 dB width of detection in range dimension (in m)";
CM_ SG_ 1678 WDoppler10DB_86 "10 dB width of detection in Doppler dimension (in m/s)";
CM_ SG_ 1678 ValidXBeamIndex_86 "Corresponding Index of in detection list of other beam";
CM_ SG_ 1678 ValidXBeam_86 "Validated by detection in other beam/measurement";
CM_ SG_ 1678 StdRange_86 "Standard deviation of range measurement (m)";
CM_ SG_ 1678 StdDoppler_86 "Standard deviation of Doppler measurement (in m/s)";
CM_ SG_ 1678 NoInfrastructure_86 "Target is moving (with high confidence)";
CM_ SG_ 1678 Infrastructure_86 "Target is stationary (infrastructure)";
CM_ SG_ 1677 Complex4_Re_85 "Complex FFT data (Re, Im) Rx channel 4";
CM_ SG_ 1677 Complex4_Im_85 "Complex FFT data (Re, Im) Rx channel 4";
CM_ SG_ 1677 Complex3_Re_85 "Complex FFT data (Re, Im) Rx channel 3";
CM_ SG_ 1677 Complex3_Im_85 "Complex FFT data (Re, Im) Rx channel 3";
CM_ SG_ 1676 Complex2_Re_85 "Complex FFT data (Re, Im) Rx channel 2";
CM_ SG_ 1676 Complex2_Im_85 "Complex FFT data (Re, Im) Rx channel 2";
CM_ SG_ 1676 Complex1_Re_85 "Complex FFT data (Re, Im) Rx channel 1";
CM_ SG_ 1676 Complex1_Im_85 "Complex FFT data (Re, Im) Rx channel 1";
CM_ SG_ 1675 StdAzimuth_85 "Standard deviation of azimuth (in °)";
CM_ SG_ 1675 PowerDB_85 "Power of detection in db";
CM_ SG_ 1675 CoGRange_85 "Center of gravity range (in m)";
CM_ SG_ 1675 CoGDoppler_85 "Center of gravity Doppler (in m/s)";
CM_ SG_ 1675 Azimuth_85 "Azimuth angle of detection (in degree in driving direction coordinate system)";
CM_ SG_ 1674 WRange10DB_85 "10 dB width of detection in range dimension (in m)";
CM_ SG_ 1674 WDoppler10DB_85 "10 dB width of detection in Doppler dimension (in m/s)";
CM_ SG_ 1674 ValidXBeamIndex_85 "Corresponding Index of in detection list of other beam";
CM_ SG_ 1674 ValidXBeam_85 "Validated by detection in other beam/measurement";
CM_ SG_ 1674 StdRange_85 "Standard deviation of range measurement (m)";
CM_ SG_ 1674 StdDoppler_85 "Standard deviation of Doppler measurement (in m/s)";
CM_ SG_ 1674 NoInfrastructure_85 "Target is moving (with high confidence)";
CM_ SG_ 1674 Infrastructure_85 "Target is stationary (infrastructure)";
CM_ SG_ 1673 Complex4_Re_84 "Complex FFT data (Re, Im) Rx channel 4";
CM_ SG_ 1673 Complex4_Im_84 "Complex FFT data (Re, Im) Rx channel 4";
CM_ SG_ 1673 Complex3_Re_84 "Complex FFT data (Re, Im) Rx channel 3";
CM_ SG_ 1673 Complex3_Im_84 "Complex FFT data (Re, Im) Rx channel 3";
CM_ SG_ 1672 Complex2_Re_84 "Complex FFT data (Re, Im) Rx channel 2";
CM_ SG_ 1672 Complex2_Im_84 "Complex FFT data (Re, Im) Rx channel 2";
CM_ SG_ 1672 Complex1_Re_84 "Complex FFT data (Re, Im) Rx channel 1";
CM_ SG_ 1672 Complex1_Im_84 "Complex FFT data (Re, Im) Rx channel 1";
CM_ SG_ 1671 StdAzimuth_84 "Standard deviation of azimuth (in °)";
CM_ SG_ 1671 PowerDB_84 "Power of detection in db";
CM_ SG_ 1671 CoGRange_84 "Center of gravity range (in m)";
CM_ SG_ 1671 CoGDoppler_84 "Center of gravity Doppler (in m/s)";
CM_ SG_ 1671 Azimuth_84 "Azimuth angle of detection (in degree in driving direction coordinate system)";
CM_ SG_ 1670 WRange10DB_84 "10 dB width of detection in range dimension (in m)";
CM_ SG_ 1670 WDoppler10DB_84 "10 dB width of detection in Doppler dimension (in m/s)";
CM_ SG_ 1670 ValidXBeamIndex_84 "Corresponding Index of in detection list of other beam";
CM_ SG_ 1670 ValidXBeam_84 "Validated by detection in other beam/measurement";
CM_ SG_ 1670 StdRange_84 "Standard deviation of range measurement (m)";
CM_ SG_ 1670 StdDoppler_84 "Standard deviation of Doppler measurement (in m/s)";
CM_ SG_ 1670 NoInfrastructure_84 "Target is moving (with high confidence)";
CM_ SG_ 1670 Infrastructure_84 "Target is stationary (infrastructure)";
CM_ SG_ 1669 Complex4_Re_83 "Complex FFT data (Re, Im) Rx channel 4";
CM_ SG_ 1669 Complex4_Im_83 "Complex FFT data (Re, Im) Rx channel 4";
CM_ SG_ 1669 Complex3_Re_83 "Complex FFT data (Re, Im) Rx channel 3";
CM_ SG_ 1669 Complex3_Im_83 "Complex FFT data (Re, Im) Rx channel 3";
CM_ SG_ 1668 Complex2_Re_83 "Complex FFT data (Re, Im) Rx channel 2";
CM_ SG_ 1668 Complex2_Im_83 "Complex FFT data (Re, Im) Rx channel 2";
CM_ SG_ 1668 Complex1_Re_83 "Complex FFT data (Re, Im) Rx channel 1";
CM_ SG_ 1668 Complex1_Im_83 "Complex FFT data (Re, Im) Rx channel 1";
CM_ SG_ 1667 StdAzimuth_83 "Standard deviation of azimuth (in °)";
CM_ SG_ 1667 PowerDB_83 "Power of detection in db";
CM_ SG_ 1667 CoGRange_83 "Center of gravity range (in m)";
CM_ SG_ 1667 CoGDoppler_83 "Center of gravity Doppler (in m/s)";
CM_ SG_ 1667 Azimuth_83 "Azimuth angle of detection (in degree in driving direction coordinate system)";
CM_ SG_ 1666 WRange10DB_83 "10 dB width of detection in range dimension (in m)";
CM_ SG_ 1666 WDoppler10DB_83 "10 dB width of detection in Doppler dimension (in m/s)";
CM_ SG_ 1666 ValidXBeamIndex_83 "Corresponding Index of in detection list of other beam";
CM_ SG_ 1666 ValidXBeam_83 "Validated by detection in other beam/measurement";
CM_ SG_ 1666 StdRange_83 "Standard deviation of range measurement (m)";
CM_ SG_ 1666 StdDoppler_83 "Standard deviation of Doppler measurement (in m/s)";
CM_ SG_ 1666 NoInfrastructure_83 "Target is moving (with high confidence)";
CM_ SG_ 1666 Infrastructure_83 "Target is stationary (infrastructure)";
CM_ SG_ 1665 Complex4_Re_82 "Complex FFT data (Re, Im) Rx channel 4";
CM_ SG_ 1665 Complex4_Im_82 "Complex FFT data (Re, Im) Rx channel 4";
CM_ SG_ 1665 Complex3_Re_82 "Complex FFT data (Re, Im) Rx channel 3";
CM_ SG_ 1665 Complex3_Im_82 "Complex FFT data (Re, Im) Rx channel 3";
CM_ SG_ 1664 Complex2_Re_82 "Complex FFT data (Re, Im) Rx channel 2";
CM_ SG_ 1664 Complex2_Im_82 "Complex FFT data (Re, Im) Rx channel 2";
CM_ SG_ 1664 Complex1_Re_82 "Complex FFT data (Re, Im) Rx channel 1";
CM_ SG_ 1664 Complex1_Im_82 "Complex FFT data (Re, Im) Rx channel 1";
CM_ SG_ 1663 StdAzimuth_82 "Standard deviation of azimuth (in °)";
CM_ SG_ 1663 PowerDB_82 "Power of detection in db";
CM_ SG_ 1663 CoGRange_82 "Center of gravity range (in m)";
CM_ SG_ 1663 CoGDoppler_82 "Center of gravity Doppler (in m/s)";
CM_ SG_ 1663 Azimuth_82 "Azimuth angle of detection (in degree in driving direction coordinate system)";
CM_ SG_ 1662 WRange10DB_82 "10 dB width of detection in range dimension (in m)";
CM_ SG_ 1662 WDoppler10DB_82 "10 dB width of detection in Doppler dimension (in m/s)";
CM_ SG_ 1662 ValidXBeamIndex_82 "Corresponding Index of in detection list of other beam";
CM_ SG_ 1662 ValidXBeam_82 "Validated by detection in other beam/measurement";
CM_ SG_ 1662 StdRange_82 "Standard deviation of range measurement (m)";
CM_ SG_ 1662 StdDoppler_82 "Standard deviation of Doppler measurement (in m/s)";
CM_ SG_ 1662 NoInfrastructure_82 "Target is moving (with high confidence)";
CM_ SG_ 1662 Infrastructure_82 "Target is stationary (infrastructure)";
CM_ SG_ 1661 Complex4_Re_81 "Complex FFT data (Re, Im) Rx channel 4";
CM_ SG_ 1661 Complex4_Im_81 "Complex FFT data (Re, Im) Rx channel 4";
CM_ SG_ 1661 Complex3_Re_81 "Complex FFT data (Re, Im) Rx channel 3";
CM_ SG_ 1661 Complex3_Im_81 "Complex FFT data (Re, Im) Rx channel 3";
CM_ SG_ 1660 Complex2_Re_81 "Complex FFT data (Re, Im) Rx channel 2";
CM_ SG_ 1660 Complex2_Im_81 "Complex FFT data (Re, Im) Rx channel 2";
CM_ SG_ 1660 Complex1_Re_81 "Complex FFT data (Re, Im) Rx channel 1";
CM_ SG_ 1660 Complex1_Im_81 "Complex FFT data (Re, Im) Rx channel 1";
CM_ SG_ 1659 StdAzimuth_81 "Standard deviation of azimuth (in °)";
CM_ SG_ 1659 PowerDB_81 "Power of detection in db";
CM_ SG_ 1659 CoGRange_81 "Center of gravity range (in m)";
CM_ SG_ 1659 CoGDoppler_81 "Center of gravity Doppler (in m/s)";
CM_ SG_ 1659 Azimuth_81 "Azimuth angle of detection (in degree in driving direction coordinate system)";
CM_ SG_ 1658 WRange10DB_81 "10 dB width of detection in range dimension (in m)";
CM_ SG_ 1658 WDoppler10DB_81 "10 dB width of detection in Doppler dimension (in m/s)";
CM_ SG_ 1658 ValidXBeamIndex_81 "Corresponding Index of in detection list of other beam";
CM_ SG_ 1658 ValidXBeam_81 "Validated by detection in other beam/measurement";
CM_ SG_ 1658 StdRange_81 "Standard deviation of range measurement (m)";
CM_ SG_ 1658 StdDoppler_81 "Standard deviation of Doppler measurement (in m/s)";
CM_ SG_ 1658 NoInfrastructure_81 "Target is moving (with high confidence)";
CM_ SG_ 1658 Infrastructure_81 "Target is stationary (infrastructure)";
CM_ SG_ 1657 Complex4_Re_80 "Complex FFT data (Re, Im) Rx channel 4";
CM_ SG_ 1657 Complex4_Im_80 "Complex FFT data (Re, Im) Rx channel 4";
CM_ SG_ 1657 Complex3_Re_80 "Complex FFT data (Re, Im) Rx channel 3";
CM_ SG_ 1657 Complex3_Im_80 "Complex FFT data (Re, Im) Rx channel 3";
CM_ SG_ 1656 Complex2_Re_80 "Complex FFT data (Re, Im) Rx channel 2";
CM_ SG_ 1656 Complex2_Im_80 "Complex FFT data (Re, Im) Rx channel 2";
CM_ SG_ 1656 Complex1_Re_80 "Complex FFT data (Re, Im) Rx channel 1";
CM_ SG_ 1656 Complex1_Im_80 "Complex FFT data (Re, Im) Rx channel 1";
CM_ SG_ 1655 StdAzimuth_80 "Standard deviation of azimuth (in °)";
CM_ SG_ 1655 PowerDB_80 "Power of detection in db";
CM_ SG_ 1655 CoGRange_80 "Center of gravity range (in m)";
CM_ SG_ 1655 CoGDoppler_80 "Center of gravity Doppler (in m/s)";
CM_ SG_ 1655 Azimuth_80 "Azimuth angle of detection (in degree in driving direction coordinate system)";
CM_ SG_ 1654 WRange10DB_80 "10 dB width of detection in range dimension (in m)";
CM_ SG_ 1654 WDoppler10DB_80 "10 dB width of detection in Doppler dimension (in m/s)";
CM_ SG_ 1654 ValidXBeamIndex_80 "Corresponding Index of in detection list of other beam";
CM_ SG_ 1654 ValidXBeam_80 "Validated by detection in other beam/measurement";
CM_ SG_ 1654 StdRange_80 "Standard deviation of range measurement (m)";
CM_ SG_ 1654 StdDoppler_80 "Standard deviation of Doppler measurement (in m/s)";
CM_ SG_ 1654 NoInfrastructure_80 "Target is moving (with high confidence)";
CM_ SG_ 1654 Infrastructure_80 "Target is stationary (infrastructure)";
CM_ SG_ 285 Complex4_Re_7 "Complex FFT data (Re, Im) Rx channel 4";
CM_ SG_ 285 Complex4_Im_7 "Complex FFT data (Re, Im) Rx channel 4";
CM_ SG_ 285 Complex3_Re_7 "Complex FFT data (Re, Im) Rx channel 3";
CM_ SG_ 285 Complex3_Im_7 "Complex FFT data (Re, Im) Rx channel 3";
CM_ SG_ 284 Complex2_Re_7 "Complex FFT data (Re, Im) Rx channel 2";
CM_ SG_ 284 Complex2_Im_7 "Complex FFT data (Re, Im) Rx channel 2";
CM_ SG_ 284 Complex1_Re_7 "Complex FFT data (Re, Im) Rx channel 1";
CM_ SG_ 284 Complex1_Im_7 "Complex FFT data (Re, Im) Rx channel 1";
CM_ SG_ 283 StdAzimuth_7 "Standard deviation of azimuth (in °)";
CM_ SG_ 283 PowerDB_7 "Power of detection in db";
CM_ SG_ 283 CoGRange_7 "Center of gravity range (in m)";
CM_ SG_ 283 CoGDoppler_7 "Center of gravity Doppler (in m/s)";
CM_ SG_ 283 Azimuth_7 "Azimuth angle of detection (in degree in driving direction coordinate system)";
CM_ SG_ 282 WRange10DB_7 "10 dB width of detection in range dimension (in m)";
CM_ SG_ 282 WDoppler10DB_7 "10 dB width of detection in Doppler dimension (in m/s)";
CM_ SG_ 282 ValidXBeamIndex_7 "Corresponding Index of in detection list of other beam";
CM_ SG_ 282 ValidXBeam_7 "Validated by detection in other beam/measurement";
CM_ SG_ 282 StdRange_7 "Standard deviation of range measurement (m)";
CM_ SG_ 282 StdDoppler_7 "Standard deviation of Doppler measurement (in m/s)";
CM_ SG_ 282 NoInfrastructure_7 "Target is moving (with high confidence)";
CM_ SG_ 282 Infrastructure_7 "Target is stationary (infrastructure)";
CM_ SG_ 1653 Complex4_Re_79 "Complex FFT data (Re, Im) Rx channel 4";
CM_ SG_ 1653 Complex4_Im_79 "Complex FFT data (Re, Im) Rx channel 4";
CM_ SG_ 1653 Complex3_Re_79 "Complex FFT data (Re, Im) Rx channel 3";
CM_ SG_ 1653 Complex3_Im_79 "Complex FFT data (Re, Im) Rx channel 3";
CM_ SG_ 1652 Complex2_Re_79 "Complex FFT data (Re, Im) Rx channel 2";
CM_ SG_ 1652 Complex2_Im_79 "Complex FFT data (Re, Im) Rx channel 2";
CM_ SG_ 1652 Complex1_Re_79 "Complex FFT data (Re, Im) Rx channel 1";
CM_ SG_ 1652 Complex1_Im_79 "Complex FFT data (Re, Im) Rx channel 1";
CM_ SG_ 1651 StdAzimuth_79 "Standard deviation of azimuth (in °)";
CM_ SG_ 1651 PowerDB_79 "Power of detection in db";
CM_ SG_ 1651 CoGRange_79 "Center of gravity range (in m)";
CM_ SG_ 1651 CoGDoppler_79 "Center of gravity Doppler (in m/s)";
CM_ SG_ 1651 Azimuth_79 "Azimuth angle of detection (in degree in driving direction coordinate system)";
CM_ SG_ 1650 WRange10DB_79 "10 dB width of detection in range dimension (in m)";
CM_ SG_ 1650 WDoppler10DB_79 "10 dB width of detection in Doppler dimension (in m/s)";
CM_ SG_ 1650 ValidXBeamIndex_79 "Corresponding Index of in detection list of other beam";
CM_ SG_ 1650 ValidXBeam_79 "Validated by detection in other beam/measurement";
CM_ SG_ 1650 StdRange_79 "Standard deviation of range measurement (m)";
CM_ SG_ 1650 StdDoppler_79 "Standard deviation of Doppler measurement (in m/s)";
CM_ SG_ 1650 NoInfrastructure_79 "Target is moving (with high confidence)";
CM_ SG_ 1650 Infrastructure_79 "Target is stationary (infrastructure)";
CM_ SG_ 1649 Complex4_Re_78 "Complex FFT data (Re, Im) Rx channel 4";
CM_ SG_ 1649 Complex4_Im_78 "Complex FFT data (Re, Im) Rx channel 4";
CM_ SG_ 1649 Complex3_Re_78 "Complex FFT data (Re, Im) Rx channel 3";
CM_ SG_ 1649 Complex3_Im_78 "Complex FFT data (Re, Im) Rx channel 3";
CM_ SG_ 1648 Complex2_Re_78 "Complex FFT data (Re, Im) Rx channel 2";
CM_ SG_ 1648 Complex2_Im_78 "Complex FFT data (Re, Im) Rx channel 2";
CM_ SG_ 1648 Complex1_Re_78 "Complex FFT data (Re, Im) Rx channel 1";
CM_ SG_ 1648 Complex1_Im_78 "Complex FFT data (Re, Im) Rx channel 1";
CM_ SG_ 1647 StdAzimuth_78 "Standard deviation of azimuth (in °)";
CM_ SG_ 1647 PowerDB_78 "Power of detection in db";
CM_ SG_ 1647 CoGRange_78 "Center of gravity range (in m)";
CM_ SG_ 1647 CoGDoppler_78 "Center of gravity Doppler (in m/s)";
CM_ SG_ 1647 Azimuth_78 "Azimuth angle of detection (in degree in driving direction coordinate system)";
CM_ SG_ 1646 WRange10DB_78 "10 dB width of detection in range dimension (in m)";
CM_ SG_ 1646 WDoppler10DB_78 "10 dB width of detection in Doppler dimension (in m/s)";
CM_ SG_ 1646 ValidXBeamIndex_78 "Corresponding Index of in detection list of other beam";
CM_ SG_ 1646 ValidXBeam_78 "Validated by detection in other beam/measurement";
CM_ SG_ 1646 StdRange_78 "Standard deviation of range measurement (m)";
CM_ SG_ 1646 StdDoppler_78 "Standard deviation of Doppler measurement (in m/s)";
CM_ SG_ 1646 NoInfrastructure_78 "Target is moving (with high confidence)";
CM_ SG_ 1646 Infrastructure_78 "Target is stationary (infrastructure)";
CM_ SG_ 1645 Complex4_Re_77 "Complex FFT data (Re, Im) Rx channel 4";
CM_ SG_ 1645 Complex4_Im_77 "Complex FFT data (Re, Im) Rx channel 4";
CM_ SG_ 1645 Complex3_Re_77 "Complex FFT data (Re, Im) Rx channel 3";
CM_ SG_ 1645 Complex3_Im_77 "Complex FFT data (Re, Im) Rx channel 3";
CM_ SG_ 1644 Complex2_Re_77 "Complex FFT data (Re, Im) Rx channel 2";
CM_ SG_ 1644 Complex2_Im_77 "Complex FFT data (Re, Im) Rx channel 2";
CM_ SG_ 1644 Complex1_Re_77 "Complex FFT data (Re, Im) Rx channel 1";
CM_ SG_ 1644 Complex1_Im_77 "Complex FFT data (Re, Im) Rx channel 1";
CM_ SG_ 1643 StdAzimuth_77 "Standard deviation of azimuth (in °)";
CM_ SG_ 1643 PowerDB_77 "Power of detection in db";
CM_ SG_ 1643 CoGRange_77 "Center of gravity range (in m)";
CM_ SG_ 1643 CoGDoppler_77 "Center of gravity Doppler (in m/s)";
CM_ SG_ 1643 Azimuth_77 "Azimuth angle of detection (in degree in driving direction coordinate system)";
CM_ SG_ 1642 WRange10DB_77 "10 dB width of detection in range dimension (in m)";
CM_ SG_ 1642 WDoppler10DB_77 "10 dB width of detection in Doppler dimension (in m/s)";
CM_ SG_ 1642 ValidXBeamIndex_77 "Corresponding Index of in detection list of other beam";
CM_ SG_ 1642 ValidXBeam_77 "Validated by detection in other beam/measurement";
CM_ SG_ 1642 StdRange_77 "Standard deviation of range measurement (m)";
CM_ SG_ 1642 StdDoppler_77 "Standard deviation of Doppler measurement (in m/s)";
CM_ SG_ 1642 NoInfrastructure_77 "Target is moving (with high confidence)";
CM_ SG_ 1642 Infrastructure_77 "Target is stationary (infrastructure)";
CM_ SG_ 1641 Complex4_Re_76 "Complex FFT data (Re, Im) Rx channel 4";
CM_ SG_ 1641 Complex4_Im_76 "Complex FFT data (Re, Im) Rx channel 4";
CM_ SG_ 1641 Complex3_Re_76 "Complex FFT data (Re, Im) Rx channel 3";
CM_ SG_ 1641 Complex3_Im_76 "Complex FFT data (Re, Im) Rx channel 3";
CM_ SG_ 1640 Complex2_Re_76 "Complex FFT data (Re, Im) Rx channel 2";
CM_ SG_ 1640 Complex2_Im_76 "Complex FFT data (Re, Im) Rx channel 2";
CM_ SG_ 1640 Complex1_Re_76 "Complex FFT data (Re, Im) Rx channel 1";
CM_ SG_ 1640 Complex1_Im_76 "Complex FFT data (Re, Im) Rx channel 1";
CM_ SG_ 1639 StdAzimuth_76 "Standard deviation of azimuth (in °)";
CM_ SG_ 1639 PowerDB_76 "Power of detection in db";
CM_ SG_ 1639 CoGRange_76 "Center of gravity range (in m)";
CM_ SG_ 1639 CoGDoppler_76 "Center of gravity Doppler (in m/s)";
CM_ SG_ 1639 Azimuth_76 "Azimuth angle of detection (in degree in driving direction coordinate system)";
CM_ SG_ 1638 WRange10DB_76 "10 dB width of detection in range dimension (in m)";
CM_ SG_ 1638 WDoppler10DB_76 "10 dB width of detection in Doppler dimension (in m/s)";
CM_ SG_ 1638 ValidXBeamIndex_76 "Corresponding Index of in detection list of other beam";
CM_ SG_ 1638 ValidXBeam_76 "Validated by detection in other beam/measurement";
CM_ SG_ 1638 StdRange_76 "Standard deviation of range measurement (m)";
CM_ SG_ 1638 StdDoppler_76 "Standard deviation of Doppler measurement (in m/s)";
CM_ SG_ 1638 NoInfrastructure_76 "Target is moving (with high confidence)";
CM_ SG_ 1638 Infrastructure_76 "Target is stationary (infrastructure)";
CM_ SG_ 1637 Complex4_Re_75 "Complex FFT data (Re, Im) Rx channel 4";
CM_ SG_ 1637 Complex4_Im_75 "Complex FFT data (Re, Im) Rx channel 4";
CM_ SG_ 1637 Complex3_Re_75 "Complex FFT data (Re, Im) Rx channel 3";
CM_ SG_ 1637 Complex3_Im_75 "Complex FFT data (Re, Im) Rx channel 3";
CM_ SG_ 1636 Complex2_Re_75 "Complex FFT data (Re, Im) Rx channel 2";
CM_ SG_ 1636 Complex2_Im_75 "Complex FFT data (Re, Im) Rx channel 2";
CM_ SG_ 1636 Complex1_Re_75 "Complex FFT data (Re, Im) Rx channel 1";
CM_ SG_ 1636 Complex1_Im_75 "Complex FFT data (Re, Im) Rx channel 1";
CM_ SG_ 1635 StdAzimuth_75 "Standard deviation of azimuth (in °)";
CM_ SG_ 1635 PowerDB_75 "Power of detection in db";
CM_ SG_ 1635 CoGRange_75 "Center of gravity range (in m)";
CM_ SG_ 1635 CoGDoppler_75 "Center of gravity Doppler (in m/s)";
CM_ SG_ 1635 Azimuth_75 "Azimuth angle of detection (in degree in driving direction coordinate system)";
CM_ SG_ 1634 WRange10DB_75 "10 dB width of detection in range dimension (in m)";
CM_ SG_ 1634 WDoppler10DB_75 "10 dB width of detection in Doppler dimension (in m/s)";
CM_ SG_ 1634 ValidXBeamIndex_75 "Corresponding Index of in detection list of other beam";
CM_ SG_ 1634 ValidXBeam_75 "Validated by detection in other beam/measurement";
CM_ SG_ 1634 StdRange_75 "Standard deviation of range measurement (m)";
CM_ SG_ 1634 StdDoppler_75 "Standard deviation of Doppler measurement (in m/s)";
CM_ SG_ 1634 NoInfrastructure_75 "Target is moving (with high confidence)";
CM_ SG_ 1634 Infrastructure_75 "Target is stationary (infrastructure)";
CM_ SG_ 1633 Complex4_Re_74 "Complex FFT data (Re, Im) Rx channel 4";
CM_ SG_ 1633 Complex4_Im_74 "Complex FFT data (Re, Im) Rx channel 4";
CM_ SG_ 1633 Complex3_Re_74 "Complex FFT data (Re, Im) Rx channel 3";
CM_ SG_ 1633 Complex3_Im_74 "Complex FFT data (Re, Im) Rx channel 3";
CM_ SG_ 1632 Complex2_Re_74 "Complex FFT data (Re, Im) Rx channel 2";
CM_ SG_ 1632 Complex2_Im_74 "Complex FFT data (Re, Im) Rx channel 2";
CM_ SG_ 1632 Complex1_Re_74 "Complex FFT data (Re, Im) Rx channel 1";
CM_ SG_ 1632 Complex1_Im_74 "Complex FFT data (Re, Im) Rx channel 1";
CM_ SG_ 1631 StdAzimuth_74 "Standard deviation of azimuth (in °)";
CM_ SG_ 1631 PowerDB_74 "Power of detection in db";
CM_ SG_ 1631 CoGRange_74 "Center of gravity range (in m)";
CM_ SG_ 1631 CoGDoppler_74 "Center of gravity Doppler (in m/s)";
CM_ SG_ 1631 Azimuth_74 "Azimuth angle of detection (in degree in driving direction coordinate system)";
CM_ SG_ 1630 WRange10DB_74 "10 dB width of detection in range dimension (in m)";
CM_ SG_ 1630 WDoppler10DB_74 "10 dB width of detection in Doppler dimension (in m/s)";
CM_ SG_ 1630 ValidXBeamIndex_74 "Corresponding Index of in detection list of other beam";
CM_ SG_ 1630 ValidXBeam_74 "Validated by detection in other beam/measurement";
CM_ SG_ 1630 StdRange_74 "Standard deviation of range measurement (m)";
CM_ SG_ 1630 StdDoppler_74 "Standard deviation of Doppler measurement (in m/s)";
CM_ SG_ 1630 NoInfrastructure_74 "Target is moving (with high confidence)";
CM_ SG_ 1630 Infrastructure_74 "Target is stationary (infrastructure)";
CM_ SG_ 1629 Complex4_Re_73 "Complex FFT data (Re, Im) Rx channel 4";
CM_ SG_ 1629 Complex4_Im_73 "Complex FFT data (Re, Im) Rx channel 4";
CM_ SG_ 1629 Complex3_Re_73 "Complex FFT data (Re, Im) Rx channel 3";
CM_ SG_ 1629 Complex3_Im_73 "Complex FFT data (Re, Im) Rx channel 3";
CM_ SG_ 1628 Complex2_Re_73 "Complex FFT data (Re, Im) Rx channel 2";
CM_ SG_ 1628 Complex2_Im_73 "Complex FFT data (Re, Im) Rx channel 2";
CM_ SG_ 1628 Complex1_Re_73 "Complex FFT data (Re, Im) Rx channel 1";
CM_ SG_ 1628 Complex1_Im_73 "Complex FFT data (Re, Im) Rx channel 1";
CM_ SG_ 1627 StdAzimuth_73 "Standard deviation of azimuth (in °)";
CM_ SG_ 1627 PowerDB_73 "Power of detection in db";
CM_ SG_ 1627 CoGRange_73 "Center of gravity range (in m)";
CM_ SG_ 1627 CoGDoppler_73 "Center of gravity Doppler (in m/s)";
CM_ SG_ 1627 Azimuth_73 "Azimuth angle of detection (in degree in driving direction coordinate system)";
CM_ SG_ 1626 WRange10DB_73 "10 dB width of detection in range dimension (in m)";
CM_ SG_ 1626 WDoppler10DB_73 "10 dB width of detection in Doppler dimension (in m/s)";
CM_ SG_ 1626 ValidXBeamIndex_73 "Corresponding Index of in detection list of other beam";
CM_ SG_ 1626 ValidXBeam_73 "Validated by detection in other beam/measurement";
CM_ SG_ 1626 StdRange_73 "Standard deviation of range measurement (m)";
CM_ SG_ 1626 StdDoppler_73 "Standard deviation of Doppler measurement (in m/s)";
CM_ SG_ 1626 NoInfrastructure_73 "Target is moving (with high confidence)";
CM_ SG_ 1626 Infrastructure_73 "Target is stationary (infrastructure)";
CM_ SG_ 1625 Complex4_Re_72 "Complex FFT data (Re, Im) Rx channel 4";
CM_ SG_ 1625 Complex4_Im_72 "Complex FFT data (Re, Im) Rx channel 4";
CM_ SG_ 1625 Complex3_Re_72 "Complex FFT data (Re, Im) Rx channel 3";
CM_ SG_ 1625 Complex3_Im_72 "Complex FFT data (Re, Im) Rx channel 3";
CM_ SG_ 1624 Complex2_Re_72 "Complex FFT data (Re, Im) Rx channel 2";
CM_ SG_ 1624 Complex2_Im_72 "Complex FFT data (Re, Im) Rx channel 2";
CM_ SG_ 1624 Complex1_Re_72 "Complex FFT data (Re, Im) Rx channel 1";
CM_ SG_ 1624 Complex1_Im_72 "Complex FFT data (Re, Im) Rx channel 1";
CM_ SG_ 1623 StdAzimuth_72 "Standard deviation of azimuth (in °)";
CM_ SG_ 1623 PowerDB_72 "Power of detection in db";
CM_ SG_ 1623 CoGRange_72 "Center of gravity range (in m)";
CM_ SG_ 1623 CoGDoppler_72 "Center of gravity Doppler (in m/s)";
CM_ SG_ 1623 Azimuth_72 "Azimuth angle of detection (in degree in driving direction coordinate system)";
CM_ SG_ 1622 WRange10DB_72 "10 dB width of detection in range dimension (in m)";
CM_ SG_ 1622 WDoppler10DB_72 "10 dB width of detection in Doppler dimension (in m/s)";
CM_ SG_ 1622 ValidXBeamIndex_72 "Corresponding Index of in detection list of other beam";
CM_ SG_ 1622 ValidXBeam_72 "Validated by detection in other beam/measurement";
CM_ SG_ 1622 StdRange_72 "Standard deviation of range measurement (m)";
CM_ SG_ 1622 StdDoppler_72 "Standard deviation of Doppler measurement (in m/s)";
CM_ SG_ 1622 NoInfrastructure_72 "Target is moving (with high confidence)";
CM_ SG_ 1622 Infrastructure_72 "Target is stationary (infrastructure)";
CM_ SG_ 1621 Complex4_Re_71 "Complex FFT data (Re, Im) Rx channel 4";
CM_ SG_ 1621 Complex4_Im_71 "Complex FFT data (Re, Im) Rx channel 4";
CM_ SG_ 1621 Complex3_Re_71 "Complex FFT data (Re, Im) Rx channel 3";
CM_ SG_ 1621 Complex3_Im_71 "Complex FFT data (Re, Im) Rx channel 3";
CM_ SG_ 1620 Complex2_Re_71 "Complex FFT data (Re, Im) Rx channel 2";
CM_ SG_ 1620 Complex2_Im_71 "Complex FFT data (Re, Im) Rx channel 2";
CM_ SG_ 1620 Complex1_Re_71 "Complex FFT data (Re, Im) Rx channel 1";
CM_ SG_ 1620 Complex1_Im_71 "Complex FFT data (Re, Im) Rx channel 1";
CM_ SG_ 1619 StdAzimuth_71 "Standard deviation of azimuth (in °)";
CM_ SG_ 1619 PowerDB_71 "Power of detection in db";
CM_ SG_ 1619 CoGRange_71 "Center of gravity range (in m)";
CM_ SG_ 1619 CoGDoppler_71 "Center of gravity Doppler (in m/s)";
CM_ SG_ 1619 Azimuth_71 "Azimuth angle of detection (in degree in driving direction coordinate system)";
CM_ SG_ 1618 WRange10DB_71 "10 dB width of detection in range dimension (in m)";
CM_ SG_ 1618 WDoppler10DB_71 "10 dB width of detection in Doppler dimension (in m/s)";
CM_ SG_ 1618 ValidXBeamIndex_71 "Corresponding Index of in detection list of other beam";
CM_ SG_ 1618 ValidXBeam_71 "Validated by detection in other beam/measurement";
CM_ SG_ 1618 StdRange_71 "Standard deviation of range measurement (m)";
CM_ SG_ 1618 StdDoppler_71 "Standard deviation of Doppler measurement (in m/s)";
CM_ SG_ 1618 NoInfrastructure_71 "Target is moving (with high confidence)";
CM_ SG_ 1618 Infrastructure_71 "Target is stationary (infrastructure)";
CM_ SG_ 1617 Complex4_Re_70 "Complex FFT data (Re, Im) Rx channel 4";
CM_ SG_ 1617 Complex4_Im_70 "Complex FFT data (Re, Im) Rx channel 4";
CM_ SG_ 1617 Complex3_Re_70 "Complex FFT data (Re, Im) Rx channel 3";
CM_ SG_ 1617 Complex3_Im_70 "Complex FFT data (Re, Im) Rx channel 3";
CM_ SG_ 1616 Complex2_Re_70 "Complex FFT data (Re, Im) Rx channel 2";
CM_ SG_ 1616 Complex2_Im_70 "Complex FFT data (Re, Im) Rx channel 2";
CM_ SG_ 1616 Complex1_Re_70 "Complex FFT data (Re, Im) Rx channel 1";
CM_ SG_ 1616 Complex1_Im_70 "Complex FFT data (Re, Im) Rx channel 1";
CM_ SG_ 1615 StdAzimuth_70 "Standard deviation of azimuth (in °)";
CM_ SG_ 1615 PowerDB_70 "Power of detection in db";
CM_ SG_ 1615 CoGRange_70 "Center of gravity range (in m)";
CM_ SG_ 1615 CoGDoppler_70 "Center of gravity Doppler (in m/s)";
CM_ SG_ 1615 Azimuth_70 "Azimuth angle of detection (in degree in driving direction coordinate system)";
CM_ SG_ 1614 WRange10DB_70 "10 dB width of detection in range dimension (in m)";
CM_ SG_ 1614 WDoppler10DB_70 "10 dB width of detection in Doppler dimension (in m/s)";
CM_ SG_ 1614 ValidXBeamIndex_70 "Corresponding Index of in detection list of other beam";
CM_ SG_ 1614 ValidXBeam_70 "Validated by detection in other beam/measurement";
CM_ SG_ 1614 StdRange_70 "Standard deviation of range measurement (m)";
CM_ SG_ 1614 StdDoppler_70 "Standard deviation of Doppler measurement (in m/s)";
CM_ SG_ 1614 NoInfrastructure_70 "Target is moving (with high confidence)";
CM_ SG_ 1614 Infrastructure_70 "Target is stationary (infrastructure)";
CM_ SG_ 281 Complex4_Re_6 "Complex FFT data (Re, Im) Rx channel 4";
CM_ SG_ 281 Complex4_Im_6 "Complex FFT data (Re, Im) Rx channel 4";
CM_ SG_ 281 Complex3_Re_6 "Complex FFT data (Re, Im) Rx channel 3";
CM_ SG_ 281 Complex3_Im_6 "Complex FFT data (Re, Im) Rx channel 3";
CM_ SG_ 280 Complex2_Re_6 "Complex FFT data (Re, Im) Rx channel 2";
CM_ SG_ 280 Complex2_Im_6 "Complex FFT data (Re, Im) Rx channel 2";
CM_ SG_ 280 Complex1_Re_6 "Complex FFT data (Re, Im) Rx channel 1";
CM_ SG_ 280 Complex1_Im_6 "Complex FFT data (Re, Im) Rx channel 1";
CM_ SG_ 279 StdAzimuth_6 "Standard deviation of azimuth (in °)";
CM_ SG_ 279 PowerDB_6 "Power of detection in db";
CM_ SG_ 279 CoGRange_6 "Center of gravity range (in m)";
CM_ SG_ 279 CoGDoppler_6 "Center of gravity Doppler (in m/s)";
CM_ SG_ 279 Azimuth_6 "Azimuth angle of detection (in degree in driving direction coordinate system)";
CM_ SG_ 278 WRange10DB_6 "10 dB width of detection in range dimension (in m)";
CM_ SG_ 278 WDoppler10DB_6 "10 dB width of detection in Doppler dimension (in m/s)";
CM_ SG_ 278 ValidXBeamIndex_6 "Corresponding Index of in detection list of other beam";
CM_ SG_ 278 ValidXBeam_6 "Validated by detection in other beam/measurement";
CM_ SG_ 278 StdRange_6 "Standard deviation of range measurement (m)";
CM_ SG_ 278 StdDoppler_6 "Standard deviation of Doppler measurement (in m/s)";
CM_ SG_ 278 NoInfrastructure_6 "Target is moving (with high confidence)";
CM_ SG_ 278 Infrastructure_6 "Target is stationary (infrastructure)";
CM_ SG_ 1613 Complex4_Re_69 "Complex FFT data (Re, Im) Rx channel 4";
CM_ SG_ 1613 Complex4_Im_69 "Complex FFT data (Re, Im) Rx channel 4";
CM_ SG_ 1613 Complex3_Re_69 "Complex FFT data (Re, Im) Rx channel 3";
CM_ SG_ 1613 Complex3_Im_69 "Complex FFT data (Re, Im) Rx channel 3";
CM_ SG_ 1612 Complex2_Re_69 "Complex FFT data (Re, Im) Rx channel 2";
CM_ SG_ 1612 Complex2_Im_69 "Complex FFT data (Re, Im) Rx channel 2";
CM_ SG_ 1612 Complex1_Re_69 "Complex FFT data (Re, Im) Rx channel 1";
CM_ SG_ 1612 Complex1_Im_69 "Complex FFT data (Re, Im) Rx channel 1";
CM_ SG_ 1611 StdAzimuth_69 "Standard deviation of azimuth (in °)";
CM_ SG_ 1611 PowerDB_69 "Power of detection in db";
CM_ SG_ 1611 CoGRange_69 "Center of gravity range (in m)";
CM_ SG_ 1611 CoGDoppler_69 "Center of gravity Doppler (in m/s)";
CM_ SG_ 1611 Azimuth_69 "Azimuth angle of detection (in degree in driving direction coordinate system)";
CM_ SG_ 1610 WRange10DB_69 "10 dB width of detection in range dimension (in m)";
CM_ SG_ 1610 WDoppler10DB_69 "10 dB width of detection in Doppler dimension (in m/s)";
CM_ SG_ 1610 ValidXBeamIndex_69 "Corresponding Index of in detection list of other beam";
CM_ SG_ 1610 ValidXBeam_69 "Validated by detection in other beam/measurement";
CM_ SG_ 1610 StdRange_69 "Standard deviation of range measurement (m)";
CM_ SG_ 1610 StdDoppler_69 "Standard deviation of Doppler measurement (in m/s)";
CM_ SG_ 1610 NoInfrastructure_69 "Target is moving (with high confidence)";
CM_ SG_ 1610 Infrastructure_69 "Target is stationary (infrastructure)";
CM_ SG_ 1609 Complex4_Re_68 "Complex FFT data (Re, Im) Rx channel 4";
CM_ SG_ 1609 Complex4_Im_68 "Complex FFT data (Re, Im) Rx channel 4";
CM_ SG_ 1609 Complex3_Re_68 "Complex FFT data (Re, Im) Rx channel 3";
CM_ SG_ 1609 Complex3_Im_68 "Complex FFT data (Re, Im) Rx channel 3";
CM_ SG_ 1608 Complex2_Re_68 "Complex FFT data (Re, Im) Rx channel 2";
CM_ SG_ 1608 Complex2_Im_68 "Complex FFT data (Re, Im) Rx channel 2";
CM_ SG_ 1608 Complex1_Re_68 "Complex FFT data (Re, Im) Rx channel 1";
CM_ SG_ 1608 Complex1_Im_68 "Complex FFT data (Re, Im) Rx channel 1";
CM_ SG_ 1607 StdAzimuth_68 "Standard deviation of azimuth (in °)";
CM_ SG_ 1607 PowerDB_68 "Power of detection in db";
CM_ SG_ 1607 CoGRange_68 "Center of gravity range (in m)";
CM_ SG_ 1607 CoGDoppler_68 "Center of gravity Doppler (in m/s)";
CM_ SG_ 1607 Azimuth_68 "Azimuth angle of detection (in degree in driving direction coordinate system)";
CM_ SG_ 1606 WRange10DB_68 "10 dB width of detection in range dimension (in m)";
CM_ SG_ 1606 WDoppler10DB_68 "10 dB width of detection in Doppler dimension (in m/s)";
CM_ SG_ 1606 ValidXBeamIndex_68 "Corresponding Index of in detection list of other beam";
CM_ SG_ 1606 ValidXBeam_68 "Validated by detection in other beam/measurement";
CM_ SG_ 1606 StdRange_68 "Standard deviation of range measurement (m)";
CM_ SG_ 1606 StdDoppler_68 "Standard deviation of Doppler measurement (in m/s)";
CM_ SG_ 1606 NoInfrastructure_68 "Target is moving (with high confidence)";
CM_ SG_ 1606 Infrastructure_68 "Target is stationary (infrastructure)";
CM_ SG_ 1605 Complex4_Re_67 "Complex FFT data (Re, Im) Rx channel 4";
CM_ SG_ 1605 Complex4_Im_67 "Complex FFT data (Re, Im) Rx channel 4";
CM_ SG_ 1605 Complex3_Re_67 "Complex FFT data (Re, Im) Rx channel 3";
CM_ SG_ 1605 Complex3_Im_67 "Complex FFT data (Re, Im) Rx channel 3";
CM_ SG_ 1604 Complex2_Re_67 "Complex FFT data (Re, Im) Rx channel 2";
CM_ SG_ 1604 Complex2_Im_67 "Complex FFT data (Re, Im) Rx channel 2";
CM_ SG_ 1604 Complex1_Re_67 "Complex FFT data (Re, Im) Rx channel 1";
CM_ SG_ 1604 Complex1_Im_67 "Complex FFT data (Re, Im) Rx channel 1";
CM_ SG_ 1603 StdAzimuth_67 "Standard deviation of azimuth (in °)";
CM_ SG_ 1603 PowerDB_67 "Power of detection in db";
CM_ SG_ 1603 CoGRange_67 "Center of gravity range (in m)";
CM_ SG_ 1603 CoGDoppler_67 "Center of gravity Doppler (in m/s)";
CM_ SG_ 1603 Azimuth_67 "Azimuth angle of detection (in degree in driving direction coordinate system)";
CM_ SG_ 1602 WRange10DB_67 "10 dB width of detection in range dimension (in m)";
CM_ SG_ 1602 WDoppler10DB_67 "10 dB width of detection in Doppler dimension (in m/s)";
CM_ SG_ 1602 ValidXBeamIndex_67 "Corresponding Index of in detection list of other beam";
CM_ SG_ 1602 ValidXBeam_67 "Validated by detection in other beam/measurement";
CM_ SG_ 1602 StdRange_67 "Standard deviation of range measurement (m)";
CM_ SG_ 1602 StdDoppler_67 "Standard deviation of Doppler measurement (in m/s)";
CM_ SG_ 1602 NoInfrastructure_67 "Target is moving (with high confidence)";
CM_ SG_ 1602 Infrastructure_67 "Target is stationary (infrastructure)";
CM_ SG_ 1601 Complex4_Re_66 "Complex FFT data (Re, Im) Rx channel 4";
CM_ SG_ 1601 Complex4_Im_66 "Complex FFT data (Re, Im) Rx channel 4";
CM_ SG_ 1601 Complex3_Re_66 "Complex FFT data (Re, Im) Rx channel 3";
CM_ SG_ 1601 Complex3_Im_66 "Complex FFT data (Re, Im) Rx channel 3";
CM_ SG_ 1600 Complex2_Re_66 "Complex FFT data (Re, Im) Rx channel 2";
CM_ SG_ 1600 Complex2_Im_66 "Complex FFT data (Re, Im) Rx channel 2";
CM_ SG_ 1600 Complex1_Re_66 "Complex FFT data (Re, Im) Rx channel 1";
CM_ SG_ 1600 Complex1_Im_66 "Complex FFT data (Re, Im) Rx channel 1";
CM_ SG_ 1599 StdAzimuth_66 "Standard deviation of azimuth (in °)";
CM_ SG_ 1599 PowerDB_66 "Power of detection in db";
CM_ SG_ 1599 CoGRange_66 "Center of gravity range (in m)";
CM_ SG_ 1599 CoGDoppler_66 "Center of gravity Doppler (in m/s)";
CM_ SG_ 1599 Azimuth_66 "Azimuth angle of detection (in degree in driving direction coordinate system)";
CM_ SG_ 1598 WRange10DB_66 "10 dB width of detection in range dimension (in m)";
CM_ SG_ 1598 WDoppler10DB_66 "10 dB width of detection in Doppler dimension (in m/s)";
CM_ SG_ 1598 ValidXBeamIndex_66 "Corresponding Index of in detection list of other beam";
CM_ SG_ 1598 ValidXBeam_66 "Validated by detection in other beam/measurement";
CM_ SG_ 1598 StdRange_66 "Standard deviation of range measurement (m)";
CM_ SG_ 1598 StdDoppler_66 "Standard deviation of Doppler measurement (in m/s)";
CM_ SG_ 1598 NoInfrastructure_66 "Target is moving (with high confidence)";
CM_ SG_ 1598 Infrastructure_66 "Target is stationary (infrastructure)";
CM_ SG_ 1597 Complex4_Re_65 "Complex FFT data (Re, Im) Rx channel 4";
CM_ SG_ 1597 Complex4_Im_65 "Complex FFT data (Re, Im) Rx channel 4";
CM_ SG_ 1597 Complex3_Re_65 "Complex FFT data (Re, Im) Rx channel 3";
CM_ SG_ 1597 Complex3_Im_65 "Complex FFT data (Re, Im) Rx channel 3";
CM_ SG_ 1596 Complex2_Re_65 "Complex FFT data (Re, Im) Rx channel 2";
CM_ SG_ 1596 Complex2_Im_65 "Complex FFT data (Re, Im) Rx channel 2";
CM_ SG_ 1596 Complex1_Re_65 "Complex FFT data (Re, Im) Rx channel 1";
CM_ SG_ 1596 Complex1_Im_65 "Complex FFT data (Re, Im) Rx channel 1";
CM_ SG_ 1595 StdAzimuth_65 "Standard deviation of azimuth (in °)";
CM_ SG_ 1595 PowerDB_65 "Power of detection in db";
CM_ SG_ 1595 CoGRange_65 "Center of gravity range (in m)";
CM_ SG_ 1595 CoGDoppler_65 "Center of gravity Doppler (in m/s)";
CM_ SG_ 1595 Azimuth_65 "Azimuth angle of detection (in degree in driving direction coordinate system)";
CM_ SG_ 1594 WRange10DB_65 "10 dB width of detection in range dimension (in m)";
CM_ SG_ 1594 WDoppler10DB_65 "10 dB width of detection in Doppler dimension (in m/s)";
CM_ SG_ 1594 ValidXBeamIndex_65 "Corresponding Index of in detection list of other beam";
CM_ SG_ 1594 ValidXBeam_65 "Validated by detection in other beam/measurement";
CM_ SG_ 1594 StdRange_65 "Standard deviation of range measurement (m)";
CM_ SG_ 1594 StdDoppler_65 "Standard deviation of Doppler measurement (in m/s)";
CM_ SG_ 1594 NoInfrastructure_65 "Target is moving (with high confidence)";
CM_ SG_ 1594 Infrastructure_65 "Target is stationary (infrastructure)";
CM_ SG_ 511 StdAzimuth_64 "Standard deviation of azimuth (in °)";
CM_ SG_ 511 PowerDB_64 "Power of detection in db";
CM_ SG_ 511 CoGRange_64 "Center of gravity range (in m)";
CM_ SG_ 511 CoGDoppler_64 "Center of gravity Doppler (in m/s)";
CM_ SG_ 511 Azimuth_64 "Azimuth angle of detection (in degree in driving direction coordinate system)";
CM_ SG_ 510 WRange10DB_64 "10 dB width of detection in range dimension (in m)";
CM_ SG_ 510 WDoppler10DB_64 "10 dB width of detection in Doppler dimension (in m/s)";
CM_ SG_ 510 ValidXBeamIndex_64 "Corresponding Index of in detection list of other beam";
CM_ SG_ 510 ValidXBeam_64 "Validated by detection in other beam/measurement";
CM_ SG_ 510 StdRange_64 "Standard deviation of range measurement (m)";
CM_ SG_ 510 StdDoppler_64 "Standard deviation of Doppler measurement (in m/s)";
CM_ SG_ 510 NoInfrastructure_64 "Target is moving (with high confidence)";
CM_ SG_ 510 Infrastructure_64 "Target is stationary (infrastructure)";
CM_ SG_ 509 Complex4_Re_63 "Complex FFT data (Re, Im) Rx channel 4";
CM_ SG_ 509 Complex4_Im_63 "Complex FFT data (Re, Im) Rx channel 4";
CM_ SG_ 509 Complex3_Re_63 "Complex FFT data (Re, Im) Rx channel 3";
CM_ SG_ 509 Complex3_Im_63 "Complex FFT data (Re, Im) Rx channel 3";
CM_ SG_ 508 Complex2_Re_63 "Complex FFT data (Re, Im) Rx channel 2";
CM_ SG_ 508 Complex2_Im_63 "Complex FFT data (Re, Im) Rx channel 2";
CM_ SG_ 508 Complex1_Re_63 "Complex FFT data (Re, Im) Rx channel 1";
CM_ SG_ 508 Complex1_Im_63 "Complex FFT data (Re, Im) Rx channel 1";
CM_ SG_ 507 StdAzimuth_63 "Standard deviation of azimuth (in °)";
CM_ SG_ 507 PowerDB_63 "Power of detection in db";
CM_ SG_ 507 CoGRange_63 "Center of gravity range (in m)";
CM_ SG_ 507 CoGDoppler_63 "Center of gravity Doppler (in m/s)";
CM_ SG_ 507 Azimuth_63 "Azimuth angle of detection (in degree in driving direction coordinate system)";
CM_ SG_ 506 WRange10DB_63 "10 dB width of detection in range dimension (in m)";
CM_ SG_ 506 WDoppler10DB_63 "10 dB width of detection in Doppler dimension (in m/s)";
CM_ SG_ 506 ValidXBeamIndex_63 "Corresponding Index of in detection list of other beam";
CM_ SG_ 506 ValidXBeam_63 "Validated by detection in other beam/measurement";
CM_ SG_ 506 StdRange_63 "Standard deviation of range measurement (m)";
CM_ SG_ 506 StdDoppler_63 "Standard deviation of Doppler measurement (in m/s)";
CM_ SG_ 506 NoInfrastructure_63 "Target is moving (with high confidence)";
CM_ SG_ 506 Infrastructure_63 "Target is stationary (infrastructure)";
CM_ SG_ 505 Complex4_Re_62 "Complex FFT data (Re, Im) Rx channel 4";
CM_ SG_ 505 Complex4_Im_62 "Complex FFT data (Re, Im) Rx channel 4";
CM_ SG_ 505 Complex3_Re_62 "Complex FFT data (Re, Im) Rx channel 3";
CM_ SG_ 505 Complex3_Im_62 "Complex FFT data (Re, Im) Rx channel 3";
CM_ SG_ 504 Complex2_Re_62 "Complex FFT data (Re, Im) Rx channel 2";
CM_ SG_ 504 Complex2_Im_62 "Complex FFT data (Re, Im) Rx channel 2";
CM_ SG_ 504 Complex1_Re_62 "Complex FFT data (Re, Im) Rx channel 1";
CM_ SG_ 504 Complex1_Im_62 "Complex FFT data (Re, Im) Rx channel 1";
CM_ SG_ 503 StdAzimuth_62 "Standard deviation of azimuth (in °)";
CM_ SG_ 503 PowerDB_62 "Power of detection in db";
CM_ SG_ 503 CoGRange_62 "Center of gravity range (in m)";
CM_ SG_ 503 CoGDoppler_62 "Center of gravity Doppler (in m/s)";
CM_ SG_ 503 Azimuth_62 "Azimuth angle of detection (in degree in driving direction coordinate system)";
CM_ SG_ 502 WRange10DB_62 "10 dB width of detection in range dimension (in m)";
CM_ SG_ 502 WDoppler10DB_62 "10 dB width of detection in Doppler dimension (in m/s)";
CM_ SG_ 502 ValidXBeamIndex_62 "Corresponding Index of in detection list of other beam";
CM_ SG_ 502 ValidXBeam_62 "Validated by detection in other beam/measurement";
CM_ SG_ 502 StdRange_62 "Standard deviation of range measurement (m)";
CM_ SG_ 502 StdDoppler_62 "Standard deviation of Doppler measurement (in m/s)";
CM_ SG_ 502 NoInfrastructure_62 "Target is moving (with high confidence)";
CM_ SG_ 502 Infrastructure_62 "Target is stationary (infrastructure)";
CM_ SG_ 501 Complex4_Re_61 "Complex FFT data (Re, Im) Rx channel 4";
CM_ SG_ 501 Complex4_Im_61 "Complex FFT data (Re, Im) Rx channel 4";
CM_ SG_ 501 Complex3_Re_61 "Complex FFT data (Re, Im) Rx channel 3";
CM_ SG_ 501 Complex3_Im_61 "Complex FFT data (Re, Im) Rx channel 3";
CM_ SG_ 500 Complex2_Re_61 "Complex FFT data (Re, Im) Rx channel 2";
CM_ SG_ 500 Complex2_Im_61 "Complex FFT data (Re, Im) Rx channel 2";
CM_ SG_ 500 Complex1_Re_61 "Complex FFT data (Re, Im) Rx channel 1";
CM_ SG_ 500 Complex1_Im_61 "Complex FFT data (Re, Im) Rx channel 1";
CM_ SG_ 499 StdAzimuth_61 "Standard deviation of azimuth (in °)";
CM_ SG_ 499 PowerDB_61 "Power of detection in db";
CM_ SG_ 499 CoGRange_61 "Center of gravity range (in m)";
CM_ SG_ 499 CoGDoppler_61 "Center of gravity Doppler (in m/s)";
CM_ SG_ 499 Azimuth_61 "Azimuth angle of detection (in degree in driving direction coordinate system)";
CM_ SG_ 498 WRange10DB_61 "10 dB width of detection in range dimension (in m)";
CM_ SG_ 498 WDoppler10DB_61 "10 dB width of detection in Doppler dimension (in m/s)";
CM_ SG_ 498 ValidXBeamIndex_61 "Corresponding Index of in detection list of other beam";
CM_ SG_ 498 ValidXBeam_61 "Validated by detection in other beam/measurement";
CM_ SG_ 498 StdRange_61 "Standard deviation of range measurement (m)";
CM_ SG_ 498 StdDoppler_61 "Standard deviation of Doppler measurement (in m/s)";
CM_ SG_ 498 NoInfrastructure_61 "Target is moving (with high confidence)";
CM_ SG_ 498 Infrastructure_61 "Target is stationary (infrastructure)";
CM_ SG_ 497 Complex4_Re_60 "Complex FFT data (Re, Im) Rx channel 4";
CM_ SG_ 497 Complex4_Im_60 "Complex FFT data (Re, Im) Rx channel 4";
CM_ SG_ 497 Complex3_Re_60 "Complex FFT data (Re, Im) Rx channel 3";
CM_ SG_ 497 Complex3_Im_60 "Complex FFT data (Re, Im) Rx channel 3";
CM_ SG_ 496 Complex2_Re_60 "Complex FFT data (Re, Im) Rx channel 2";
CM_ SG_ 496 Complex2_Im_60 "Complex FFT data (Re, Im) Rx channel 2";
CM_ SG_ 496 Complex1_Re_60 "Complex FFT data (Re, Im) Rx channel 1";
CM_ SG_ 496 Complex1_Im_60 "Complex FFT data (Re, Im) Rx channel 1";
CM_ SG_ 495 StdAzimuth_60 "Standard deviation of azimuth (in °)";
CM_ SG_ 495 PowerDB_60 "Power of detection in db";
CM_ SG_ 495 CoGRange_60 "Center of gravity range (in m)";
CM_ SG_ 495 CoGDoppler_60 "Center of gravity Doppler (in m/s)";
CM_ SG_ 495 Azimuth_60 "Azimuth angle of detection (in degree in driving direction coordinate system)";
CM_ SG_ 494 WRange10DB_60 "10 dB width of detection in range dimension (in m)";
CM_ SG_ 494 WDoppler10DB_60 "10 dB width of detection in Doppler dimension (in m/s)";
CM_ SG_ 494 ValidXBeamIndex_60 "Corresponding Index of in detection list of other beam";
CM_ SG_ 494 ValidXBeam_60 "Validated by detection in other beam/measurement";
CM_ SG_ 494 StdRange_60 "Standard deviation of range measurement (m)";
CM_ SG_ 494 StdDoppler_60 "Standard deviation of Doppler measurement (in m/s)";
CM_ SG_ 494 NoInfrastructure_60 "Target is moving (with high confidence)";
CM_ SG_ 494 Infrastructure_60 "Target is stationary (infrastructure)";
CM_ SG_ 277 Complex4_Re_5 "Complex FFT data (Re, Im) Rx channel 4";
CM_ SG_ 277 Complex4_Im_5 "Complex FFT data (Re, Im) Rx channel 4";
CM_ SG_ 277 Complex3_Re_5 "Complex FFT data (Re, Im) Rx channel 3";
CM_ SG_ 277 Complex3_Im_5 "Complex FFT data (Re, Im) Rx channel 3";
CM_ SG_ 276 Complex2_Re_5 "Complex FFT data (Re, Im) Rx channel 2";
CM_ SG_ 276 Complex2_Im_5 "Complex FFT data (Re, Im) Rx channel 2";
CM_ SG_ 276 Complex1_Re_5 "Complex FFT data (Re, Im) Rx channel 1";
CM_ SG_ 276 Complex1_Im_5 "Complex FFT data (Re, Im) Rx channel 1";
CM_ SG_ 275 StdAzimuth_5 "Standard deviation of azimuth (in °)";
CM_ SG_ 275 PowerDB_5 "Power of detection in db";
CM_ SG_ 275 CoGRange_5 "Center of gravity range (in m)";
CM_ SG_ 275 CoGDoppler_5 "Center of gravity Doppler (in m/s)";
CM_ SG_ 275 Azimuth_5 "Azimuth angle of detection (in degree in driving direction coordinate system)";
CM_ SG_ 274 WRange10DB_5 "10 dB width of detection in range dimension (in m)";
CM_ SG_ 274 WDoppler10DB_5 "10 dB width of detection in Doppler dimension (in m/s)";
CM_ SG_ 274 ValidXBeamIndex_5 "Corresponding Index of in detection list of other beam";
CM_ SG_ 274 ValidXBeam_5 "Validated by detection in other beam/measurement";
CM_ SG_ 274 StdRange_5 "Standard deviation of range measurement (m)";
CM_ SG_ 274 StdDoppler_5 "Standard deviation of Doppler measurement (in m/s)";
CM_ SG_ 274 NoInfrastructure_5 "Target is moving (with high confidence)";
CM_ SG_ 274 Infrastructure_5 "Target is stationary (infrastructure)";
CM_ SG_ 493 Complex4_Re_59 "Complex FFT data (Re, Im) Rx channel 4";
CM_ SG_ 493 Complex4_Im_59 "Complex FFT data (Re, Im) Rx channel 4";
CM_ SG_ 493 Complex3_Re_59 "Complex FFT data (Re, Im) Rx channel 3";
CM_ SG_ 493 Complex3_Im_59 "Complex FFT data (Re, Im) Rx channel 3";
CM_ SG_ 492 Complex2_Re_59 "Complex FFT data (Re, Im) Rx channel 2";
CM_ SG_ 492 Complex2_Im_59 "Complex FFT data (Re, Im) Rx channel 2";
CM_ SG_ 492 Complex1_Re_59 "Complex FFT data (Re, Im) Rx channel 1";
CM_ SG_ 492 Complex1_Im_59 "Complex FFT data (Re, Im) Rx channel 1";
CM_ SG_ 491 StdAzimuth_59 "Standard deviation of azimuth (in °)";
CM_ SG_ 491 PowerDB_59 "Power of detection in db";
CM_ SG_ 491 CoGRange_59 "Center of gravity range (in m)";
CM_ SG_ 491 CoGDoppler_59 "Center of gravity Doppler (in m/s)";
CM_ SG_ 491 Azimuth_59 "Azimuth angle of detection (in degree in driving direction coordinate system)";
CM_ SG_ 490 WRange10DB_59 "10 dB width of detection in range dimension (in m)";
CM_ SG_ 490 WDoppler10DB_59 "10 dB width of detection in Doppler dimension (in m/s)";
CM_ SG_ 490 ValidXBeamIndex_59 "Corresponding Index of in detection list of other beam";
CM_ SG_ 490 ValidXBeam_59 "Validated by detection in other beam/measurement";
CM_ SG_ 490 StdRange_59 "Standard deviation of range measurement (m)";
CM_ SG_ 490 StdDoppler_59 "Standard deviation of Doppler measurement (in m/s)";
CM_ SG_ 490 NoInfrastructure_59 "Target is moving (with high confidence)";
CM_ SG_ 490 Infrastructure_59 "Target is stationary (infrastructure)";
CM_ SG_ 489 Complex4_Re_58 "Complex FFT data (Re, Im) Rx channel 4";
CM_ SG_ 489 Complex4_Im_58 "Complex FFT data (Re, Im) Rx channel 4";
CM_ SG_ 489 Complex3_Re_58 "Complex FFT data (Re, Im) Rx channel 3";
CM_ SG_ 489 Complex3_Im_58 "Complex FFT data (Re, Im) Rx channel 3";
CM_ SG_ 488 Complex2_Re_58 "Complex FFT data (Re, Im) Rx channel 2";
CM_ SG_ 488 Complex2_Im_58 "Complex FFT data (Re, Im) Rx channel 2";
CM_ SG_ 488 Complex1_Re_58 "Complex FFT data (Re, Im) Rx channel 1";
CM_ SG_ 488 Complex1_Im_58 "Complex FFT data (Re, Im) Rx channel 1";
CM_ SG_ 487 StdAzimuth_58 "Standard deviation of azimuth (in °)";
CM_ SG_ 487 PowerDB_58 "Power of detection in db";
CM_ SG_ 487 CoGRange_58 "Center of gravity range (in m)";
CM_ SG_ 487 CoGDoppler_58 "Center of gravity Doppler (in m/s)";
CM_ SG_ 487 Azimuth_58 "Azimuth angle of detection (in degree in driving direction coordinate system)";
CM_ SG_ 486 WRange10DB_58 "10 dB width of detection in range dimension (in m)";
CM_ SG_ 486 WDoppler10DB_58 "10 dB width of detection in Doppler dimension (in m/s)";
CM_ SG_ 486 ValidXBeamIndex_58 "Corresponding Index of in detection list of other beam";
CM_ SG_ 486 ValidXBeam_58 "Validated by detection in other beam/measurement";
CM_ SG_ 486 StdRange_58 "Standard deviation of range measurement (m)";
CM_ SG_ 486 StdDoppler_58 "Standard deviation of Doppler measurement (in m/s)";
CM_ SG_ 486 NoInfrastructure_58 "Target is moving (with high confidence)";
CM_ SG_ 486 Infrastructure_58 "Target is stationary (infrastructure)";
CM_ SG_ 485 Complex4_Re_57 "Complex FFT data (Re, Im) Rx channel 4";
CM_ SG_ 485 Complex4_Im_57 "Complex FFT data (Re, Im) Rx channel 4";
CM_ SG_ 485 Complex3_Re_57 "Complex FFT data (Re, Im) Rx channel 3";
CM_ SG_ 485 Complex3_Im_57 "Complex FFT data (Re, Im) Rx channel 3";
CM_ SG_ 484 Complex2_Re_57 "Complex FFT data (Re, Im) Rx channel 2";
CM_ SG_ 484 Complex2_Im_57 "Complex FFT data (Re, Im) Rx channel 2";
CM_ SG_ 484 Complex1_Re_57 "Complex FFT data (Re, Im) Rx channel 1";
CM_ SG_ 484 Complex1_Im_57 "Complex FFT data (Re, Im) Rx channel 1";
CM_ SG_ 483 StdAzimuth_57 "Standard deviation of azimuth (in °)";
CM_ SG_ 483 PowerDB_57 "Power of detection in db";
CM_ SG_ 483 CoGRange_57 "Center of gravity range (in m)";
CM_ SG_ 483 CoGDoppler_57 "Center of gravity Doppler (in m/s)";
CM_ SG_ 483 Azimuth_57 "Azimuth angle of detection (in degree in driving direction coordinate system)";
CM_ SG_ 482 WRange10DB_57 "10 dB width of detection in range dimension (in m)";
CM_ SG_ 482 WDoppler10DB_57 "10 dB width of detection in Doppler dimension (in m/s)";
CM_ SG_ 482 ValidXBeamIndex_57 "Corresponding Index of in detection list of other beam";
CM_ SG_ 482 ValidXBeam_57 "Validated by detection in other beam/measurement";
CM_ SG_ 482 StdRange_57 "Standard deviation of range measurement (m)";
CM_ SG_ 482 StdDoppler_57 "Standard deviation of Doppler measurement (in m/s)";
CM_ SG_ 482 NoInfrastructure_57 "Target is moving (with high confidence)";
CM_ SG_ 482 Infrastructure_57 "Target is stationary (infrastructure)";
CM_ SG_ 481 Complex4_Re_56 "Complex FFT data (Re, Im) Rx channel 4";
CM_ SG_ 481 Complex4_Im_56 "Complex FFT data (Re, Im) Rx channel 4";
CM_ SG_ 481 Complex3_Re_56 "Complex FFT data (Re, Im) Rx channel 3";
CM_ SG_ 481 Complex3_Im_56 "Complex FFT data (Re, Im) Rx channel 3";
CM_ SG_ 480 Complex2_Re_56 "Complex FFT data (Re, Im) Rx channel 2";
CM_ SG_ 480 Complex2_Im_56 "Complex FFT data (Re, Im) Rx channel 2";
CM_ SG_ 480 Complex1_Re_56 "Complex FFT data (Re, Im) Rx channel 1";
CM_ SG_ 480 Complex1_Im_56 "Complex FFT data (Re, Im) Rx channel 1";
CM_ SG_ 479 StdAzimuth_56 "Standard deviation of azimuth (in °)";
CM_ SG_ 479 PowerDB_56 "Power of detection in db";
CM_ SG_ 479 CoGRange_56 "Center of gravity range (in m)";
CM_ SG_ 479 CoGDoppler_56 "Center of gravity Doppler (in m/s)";
CM_ SG_ 479 Azimuth_56 "Azimuth angle of detection (in degree in driving direction coordinate system)";
CM_ SG_ 478 WRange10DB_56 "10 dB width of detection in range dimension (in m)";
CM_ SG_ 478 WDoppler10DB_56 "10 dB width of detection in Doppler dimension (in m/s)";
CM_ SG_ 478 ValidXBeamIndex_56 "Corresponding Index of in detection list of other beam";
CM_ SG_ 478 ValidXBeam_56 "Validated by detection in other beam/measurement";
CM_ SG_ 478 StdRange_56 "Standard deviation of range measurement (m)";
CM_ SG_ 478 StdDoppler_56 "Standard deviation of Doppler measurement (in m/s)";
CM_ SG_ 478 NoInfrastructure_56 "Target is moving (with high confidence)";
CM_ SG_ 478 Infrastructure_56 "Target is stationary (infrastructure)";
CM_ SG_ 477 Complex4_Re_55 "Complex FFT data (Re, Im) Rx channel 4";
CM_ SG_ 477 Complex4_Im_55 "Complex FFT data (Re, Im) Rx channel 4";
CM_ SG_ 477 Complex3_Re_55 "Complex FFT data (Re, Im) Rx channel 3";
CM_ SG_ 477 Complex3_Im_55 "Complex FFT data (Re, Im) Rx channel 3";
CM_ SG_ 476 Complex2_Re_55 "Complex FFT data (Re, Im) Rx channel 2";
CM_ SG_ 476 Complex2_Im_55 "Complex FFT data (Re, Im) Rx channel 2";
CM_ SG_ 476 Complex1_Re_55 "Complex FFT data (Re, Im) Rx channel 1";
CM_ SG_ 476 Complex1_Im_55 "Complex FFT data (Re, Im) Rx channel 1";
CM_ SG_ 475 StdAzimuth_55 "Standard deviation of azimuth (in °)";
CM_ SG_ 475 PowerDB_55 "Power of detection in db";
CM_ SG_ 475 CoGRange_55 "Center of gravity range (in m)";
CM_ SG_ 475 CoGDoppler_55 "Center of gravity Doppler (in m/s)";
CM_ SG_ 475 Azimuth_55 "Azimuth angle of detection (in degree in driving direction coordinate system)";
CM_ SG_ 474 WRange10DB_55 "10 dB width of detection in range dimension (in m)";
CM_ SG_ 474 WDoppler10DB_55 "10 dB width of detection in Doppler dimension (in m/s)";
CM_ SG_ 474 ValidXBeamIndex_55 "Corresponding Index of in detection list of other beam";
CM_ SG_ 474 ValidXBeam_55 "Validated by detection in other beam/measurement";
CM_ SG_ 474 StdRange_55 "Standard deviation of range measurement (m)";
CM_ SG_ 474 StdDoppler_55 "Standard deviation of Doppler measurement (in m/s)";
CM_ SG_ 474 NoInfrastructure_55 "Target is moving (with high confidence)";
CM_ SG_ 474 Infrastructure_55 "Target is stationary (infrastructure)";
CM_ SG_ 473 Complex4_Re_54 "Complex FFT data (Re, Im) Rx channel 4";
CM_ SG_ 473 Complex4_Im_54 "Complex FFT data (Re, Im) Rx channel 4";
CM_ SG_ 473 Complex3_Re_54 "Complex FFT data (Re, Im) Rx channel 3";
CM_ SG_ 473 Complex3_Im_54 "Complex FFT data (Re, Im) Rx channel 3";
CM_ SG_ 472 Complex2_Re_54 "Complex FFT data (Re, Im) Rx channel 2";
CM_ SG_ 472 Complex2_Im_54 "Complex FFT data (Re, Im) Rx channel 2";
CM_ SG_ 472 Complex1_Re_54 "Complex FFT data (Re, Im) Rx channel 1";
CM_ SG_ 472 Complex1_Im_54 "Complex FFT data (Re, Im) Rx channel 1";
CM_ SG_ 471 StdAzimuth_54 "Standard deviation of azimuth (in °)";
CM_ SG_ 471 PowerDB_54 "Power of detection in db";
CM_ SG_ 471 CoGRange_54 "Center of gravity range (in m)";
CM_ SG_ 471 CoGDoppler_54 "Center of gravity Doppler (in m/s)";
CM_ SG_ 471 Azimuth_54 "Azimuth angle of detection (in degree in driving direction coordinate system)";
CM_ SG_ 470 WRange10DB_54 "10 dB width of detection in range dimension (in m)";
CM_ SG_ 470 WDoppler10DB_54 "10 dB width of detection in Doppler dimension (in m/s)";
CM_ SG_ 470 ValidXBeamIndex_54 "Corresponding Index of in detection list of other beam";
CM_ SG_ 470 ValidXBeam_54 "Validated by detection in other beam/measurement";
CM_ SG_ 470 StdRange_54 "Standard deviation of range measurement (m)";
CM_ SG_ 470 StdDoppler_54 "Standard deviation of Doppler measurement (in m/s)";
CM_ SG_ 470 NoInfrastructure_54 "Target is moving (with high confidence)";
CM_ SG_ 470 Infrastructure_54 "Target is stationary (infrastructure)";
CM_ SG_ 469 Complex4_Re_53 "Complex FFT data (Re, Im) Rx channel 4";
CM_ SG_ 469 Complex4_Im_53 "Complex FFT data (Re, Im) Rx channel 4";
CM_ SG_ 469 Complex3_Re_53 "Complex FFT data (Re, Im) Rx channel 3";
CM_ SG_ 469 Complex3_Im_53 "Complex FFT data (Re, Im) Rx channel 3";
CM_ SG_ 468 Complex2_Re_53 "Complex FFT data (Re, Im) Rx channel 2";
CM_ SG_ 468 Complex2_Im_53 "Complex FFT data (Re, Im) Rx channel 2";
CM_ SG_ 468 Complex1_Re_53 "Complex FFT data (Re, Im) Rx channel 1";
CM_ SG_ 468 Complex1_Im_53 "Complex FFT data (Re, Im) Rx channel 1";
CM_ SG_ 467 StdAzimuth_53 "Standard deviation of azimuth (in °)";
CM_ SG_ 467 PowerDB_53 "Power of detection in db";
CM_ SG_ 467 CoGRange_53 "Center of gravity range (in m)";
CM_ SG_ 467 CoGDoppler_53 "Center of gravity Doppler (in m/s)";
CM_ SG_ 467 Azimuth_53 "Azimuth angle of detection (in degree in driving direction coordinate system)";
CM_ SG_ 466 WRange10DB_53 "10 dB width of detection in range dimension (in m)";
CM_ SG_ 466 WDoppler10DB_53 "10 dB width of detection in Doppler dimension (in m/s)";
CM_ SG_ 466 ValidXBeamIndex_53 "Corresponding Index of in detection list of other beam";
CM_ SG_ 466 ValidXBeam_53 "Validated by detection in other beam/measurement";
CM_ SG_ 466 StdRange_53 "Standard deviation of range measurement (m)";
CM_ SG_ 466 StdDoppler_53 "Standard deviation of Doppler measurement (in m/s)";
CM_ SG_ 466 NoInfrastructure_53 "Target is moving (with high confidence)";
CM_ SG_ 466 Infrastructure_53 "Target is stationary (infrastructure)";
CM_ SG_ 465 Complex4_Re_52 "Complex FFT data (Re, Im) Rx channel 4";
CM_ SG_ 465 Complex4_Im_52 "Complex FFT data (Re, Im) Rx channel 4";
CM_ SG_ 465 Complex3_Re_52 "Complex FFT data (Re, Im) Rx channel 3";
CM_ SG_ 465 Complex3_Im_52 "Complex FFT data (Re, Im) Rx channel 3";
CM_ SG_ 464 Complex2_Re_52 "Complex FFT data (Re, Im) Rx channel 2";
CM_ SG_ 464 Complex2_Im_52 "Complex FFT data (Re, Im) Rx channel 2";
CM_ SG_ 464 Complex1_Re_52 "Complex FFT data (Re, Im) Rx channel 1";
CM_ SG_ 464 Complex1_Im_52 "Complex FFT data (Re, Im) Rx channel 1";
CM_ SG_ 463 StdAzimuth_52 "Standard deviation of azimuth (in °)";
CM_ SG_ 463 PowerDB_52 "Power of detection in db";
CM_ SG_ 463 CoGRange_52 "Center of gravity range (in m)";
CM_ SG_ 463 CoGDoppler_52 "Center of gravity Doppler (in m/s)";
CM_ SG_ 463 Azimuth_52 "Azimuth angle of detection (in degree in driving direction coordinate system)";
CM_ SG_ 462 WRange10DB_52 "10 dB width of detection in range dimension (in m)";
CM_ SG_ 462 WDoppler10DB_52 "10 dB width of detection in Doppler dimension (in m/s)";
CM_ SG_ 462 ValidXBeamIndex_52 "Corresponding Index of in detection list of other beam";
CM_ SG_ 462 ValidXBeam_52 "Validated by detection in other beam/measurement";
CM_ SG_ 462 StdRange_52 "Standard deviation of range measurement (m)";
CM_ SG_ 462 StdDoppler_52 "Standard deviation of Doppler measurement (in m/s)";
CM_ SG_ 462 NoInfrastructure_52 "Target is moving (with high confidence)";
CM_ SG_ 462 Infrastructure_52 "Target is stationary (infrastructure)";
CM_ SG_ 461 Complex4_Re_51 "Complex FFT data (Re, Im) Rx channel 4";
CM_ SG_ 461 Complex4_Im_51 "Complex FFT data (Re, Im) Rx channel 4";
CM_ SG_ 461 Complex3_Re_51 "Complex FFT data (Re, Im) Rx channel 3";
CM_ SG_ 461 Complex3_Im_51 "Complex FFT data (Re, Im) Rx channel 3";
CM_ SG_ 460 Complex2_Re_51 "Complex FFT data (Re, Im) Rx channel 2";
CM_ SG_ 460 Complex2_Im_51 "Complex FFT data (Re, Im) Rx channel 2";
CM_ SG_ 460 Complex1_Re_51 "Complex FFT data (Re, Im) Rx channel 1";
CM_ SG_ 460 Complex1_Im_51 "Complex FFT data (Re, Im) Rx channel 1";
CM_ SG_ 459 StdAzimuth_51 "Standard deviation of azimuth (in °)";
CM_ SG_ 459 PowerDB_51 "Power of detection in db";
CM_ SG_ 459 CoGRange_51 "Center of gravity range (in m)";
CM_ SG_ 459 CoGDoppler_51 "Center of gravity Doppler (in m/s)";
CM_ SG_ 459 Azimuth_51 "Azimuth angle of detection (in degree in driving direction coordinate system)";
CM_ SG_ 458 WRange10DB_51 "10 dB width of detection in range dimension (in m)";
CM_ SG_ 458 WDoppler10DB_51 "10 dB width of detection in Doppler dimension (in m/s)";
CM_ SG_ 458 ValidXBeamIndex_51 "Corresponding Index of in detection list of other beam";
CM_ SG_ 458 ValidXBeam_51 "Validated by detection in other beam/measurement";
CM_ SG_ 458 StdRange_51 "Standard deviation of range measurement (m)";
CM_ SG_ 458 StdDoppler_51 "Standard deviation of Doppler measurement (in m/s)";
CM_ SG_ 458 NoInfrastructure_51 "Target is moving (with high confidence)";
CM_ SG_ 458 Infrastructure_51 "Target is stationary (infrastructure)";
CM_ SG_ 457 Complex4_Re_50 "Complex FFT data (Re, Im) Rx channel 4";
CM_ SG_ 457 Complex4_Im_50 "Complex FFT data (Re, Im) Rx channel 4";
CM_ SG_ 457 Complex3_Re_50 "Complex FFT data (Re, Im) Rx channel 3";
CM_ SG_ 457 Complex3_Im_50 "Complex FFT data (Re, Im) Rx channel 3";
CM_ SG_ 456 Complex2_Re_50 "Complex FFT data (Re, Im) Rx channel 2";
CM_ SG_ 456 Complex2_Im_50 "Complex FFT data (Re, Im) Rx channel 2";
CM_ SG_ 456 Complex1_Re_50 "Complex FFT data (Re, Im) Rx channel 1";
CM_ SG_ 456 Complex1_Im_50 "Complex FFT data (Re, Im) Rx channel 1";
CM_ SG_ 455 StdAzimuth_50 "Standard deviation of azimuth (in °)";
CM_ SG_ 455 PowerDB_50 "Power of detection in db";
CM_ SG_ 455 CoGRange_50 "Center of gravity range (in m)";
CM_ SG_ 455 CoGDoppler_50 "Center of gravity Doppler (in m/s)";
CM_ SG_ 455 Azimuth_50 "Azimuth angle of detection (in degree in driving direction coordinate system)";
CM_ SG_ 454 WRange10DB_50 "10 dB width of detection in range dimension (in m)";
CM_ SG_ 454 WDoppler10DB_50 "10 dB width of detection in Doppler dimension (in m/s)";
CM_ SG_ 454 ValidXBeamIndex_50 "Corresponding Index of in detection list of other beam";
CM_ SG_ 454 ValidXBeam_50 "Validated by detection in other beam/measurement";
CM_ SG_ 454 StdRange_50 "Standard deviation of range measurement (m)";
CM_ SG_ 454 StdDoppler_50 "Standard deviation of Doppler measurement (in m/s)";
CM_ SG_ 454 NoInfrastructure_50 "Target is moving (with high confidence)";
CM_ SG_ 454 Infrastructure_50 "Target is stationary (infrastructure)";
CM_ SG_ 273 Complex4_Re_4 "Complex FFT data (Re, Im) Rx channel 4";
CM_ SG_ 273 Complex4_Im_4 "Complex FFT data (Re, Im) Rx channel 4";
CM_ SG_ 273 Complex3_Re_4 "Complex FFT data (Re, Im) Rx channel 3";
CM_ SG_ 273 Complex3_Im_4 "Complex FFT data (Re, Im) Rx channel 3";
CM_ SG_ 272 Complex2_Re_4 "Complex FFT data (Re, Im) Rx channel 2";
CM_ SG_ 272 Complex2_Im_4 "Complex FFT data (Re, Im) Rx channel 2";
CM_ SG_ 272 Complex1_Re_4 "Complex FFT data (Re, Im) Rx channel 1";
CM_ SG_ 272 Complex1_Im_4 "Complex FFT data (Re, Im) Rx channel 1";
BA_DEF_ BU_  "ECU" STRING ;
BA_DEF_ BO_  "GenMsgCycleTime" INT 0 1000000;
BA_DEF_ BO_  "GenMsgSendType" ENUM  "Zyklisch ","Ereignisgesteuert ","dummy ","ZyklischImmer";
BA_DEF_ BU_  "NWM-Knoten" ENUM  "No","Yes";
BA_DEF_ BU_  "MessageManagerUsed" ENUM  "No","Yes";
BA_DEF_ BU_  "NodeLayerModules" STRING ;
BA_DEF_  "NWM_Basisadresse" HEX 1152 1152;
BA_DEF_  "NWM-Basisadresse" HEX 1152 1152;
BA_DEF_  "NWM-Typ" ENUM  "zentral","dezentral","keines","vagnm","bmwnm";
BA_DEF_  "Manufacturer_ALT" ENUM  "DBAG","VAG","BMWAG","PAG","GM";
BA_DEF_  "Manufacturer" STRING ;
BA_DEF_DEF_  "ECU" "";
BA_DEF_DEF_  "GenMsgCycleTime" 0;
BA_DEF_DEF_  "GenMsgSendType" "";
BA_DEF_DEF_  "NWM-Knoten" "Yes";
BA_DEF_DEF_  "MessageManagerUsed" "Yes";
BA_DEF_DEF_  "NodeLayerModules" "bmwnm03.dll";
BA_DEF_DEF_  "NWM_Basisadresse" 1152;
BA_DEF_DEF_  "NWM-Basisadresse" 1152;
BA_DEF_DEF_  "NWM-Typ" "bmwnm";
BA_DEF_DEF_  "Manufacturer_ALT" "BMWAG";
BA_DEF_DEF_  "Manufacturer" "BMWAG";
BA_ "ECU" BU_ SODX "SODX";
BA_ "GenMsgCycleTime" BO_ 257 50;
BA_ "GenMsgSendType" BO_ 257 0;
BA_ "GenMsgSendType" BO_ 256 1;
BA_ "GenMsgSendType" BO_ 293 1;
BA_ "GenMsgSendType" BO_ 292 1;
BA_ "GenMsgSendType" BO_ 291 1;
BA_ "GenMsgSendType" BO_ 290 1;
BA_ "GenMsgSendType" BO_ 1733 1;
BA_ "GenMsgSendType" BO_ 1732 1;
BA_ "GenMsgSendType" BO_ 1731 1;
BA_ "GenMsgSendType" BO_ 1730 1;
BA_ "GenMsgSendType" BO_ 1729 1;
BA_ "GenMsgSendType" BO_ 1728 1;
BA_ "GenMsgSendType" BO_ 1727 1;
BA_ "GenMsgSendType" BO_ 1726 1;
BA_ "GenMsgSendType" BO_ 1725 1;
BA_ "GenMsgSendType" BO_ 1724 1;
BA_ "GenMsgSendType" BO_ 1723 1;
BA_ "GenMsgSendType" BO_ 1722 1;
BA_ "GenMsgSendType" BO_ 1721 1;
BA_ "GenMsgSendType" BO_ 1720 1;
BA_ "GenMsgSendType" BO_ 1719 1;
BA_ "GenMsgSendType" BO_ 1718 1;
BA_ "GenMsgSendType" BO_ 1717 1;
BA_ "GenMsgSendType" BO_ 1716 1;
BA_ "GenMsgSendType" BO_ 1715 1;
BA_ "GenMsgSendType" BO_ 1714 1;
BA_ "GenMsgSendType" BO_ 1713 1;
BA_ "GenMsgSendType" BO_ 1712 1;
BA_ "GenMsgSendType" BO_ 1711 1;
BA_ "GenMsgSendType" BO_ 1710 1;
BA_ "GenMsgSendType" BO_ 1709 1;
BA_ "GenMsgSendType" BO_ 1708 1;
BA_ "GenMsgSendType" BO_ 1707 1;
BA_ "GenMsgSendType" BO_ 1706 1;
BA_ "GenMsgSendType" BO_ 1705 1;
BA_ "GenMsgSendType" BO_ 1704 1;
BA_ "GenMsgSendType" BO_ 1703 1;
BA_ "GenMsgSendType" BO_ 1702 1;
BA_ "GenMsgSendType" BO_ 1701 1;
BA_ "GenMsgSendType" BO_ 1700 1;
BA_ "GenMsgSendType" BO_ 1699 1;
BA_ "GenMsgSendType" BO_ 1698 1;
BA_ "GenMsgSendType" BO_ 1697 1;
BA_ "GenMsgSendType" BO_ 1696 1;
BA_ "GenMsgSendType" BO_ 1695 1;
BA_ "GenMsgSendType" BO_ 1694 1;
BA_ "GenMsgSendType" BO_ 289 1;
BA_ "GenMsgSendType" BO_ 288 1;
BA_ "GenMsgSendType" BO_ 287 1;
BA_ "GenMsgSendType" BO_ 286 1;
BA_ "GenMsgSendType" BO_ 1693 1;
BA_ "GenMsgSendType" BO_ 1692 1;
BA_ "GenMsgSendType" BO_ 1691 1;
BA_ "GenMsgSendType" BO_ 1690 1;
BA_ "GenMsgSendType" BO_ 1689 1;
BA_ "GenMsgSendType" BO_ 1688 1;
BA_ "GenMsgSendType" BO_ 1687 1;
BA_ "GenMsgSendType" BO_ 1686 1;
BA_ "GenMsgSendType" BO_ 1685 1;
BA_ "GenMsgSendType" BO_ 1684 1;
BA_ "GenMsgSendType" BO_ 1683 1;
BA_ "GenMsgSendType" BO_ 1682 1;
BA_ "GenMsgSendType" BO_ 1681 1;
BA_ "GenMsgSendType" BO_ 1680 1;
BA_ "GenMsgSendType" BO_ 1679 1;
BA_ "GenMsgSendType" BO_ 1678 1;
BA_ "GenMsgSendType" BO_ 1677 1;
BA_ "GenMsgSendType" BO_ 1676 1;
BA_ "GenMsgSendType" BO_ 1675 1;
BA_ "GenMsgSendType" BO_ 1674 1;
BA_ "GenMsgSendType" BO_ 1673 1;
BA_ "GenMsgSendType" BO_ 1672 1;
BA_ "GenMsgSendType" BO_ 1671 1;
BA_ "GenMsgSendType" BO_ 1670 1;
BA_ "GenMsgSendType" BO_ 1669 1;
BA_ "GenMsgSendType" BO_ 1668 1;
BA_ "GenMsgSendType" BO_ 1667 1;
BA_ "GenMsgSendType" BO_ 1666 1;
BA_ "GenMsgSendType" BO_ 1665 1;
BA_ "GenMsgSendType" BO_ 1664 1;
BA_ "GenMsgSendType" BO_ 1663 1;
BA_ "GenMsgSendType" BO_ 1662 1;
BA_ "GenMsgSendType" BO_ 1661 1;
BA_ "GenMsgSendType" BO_ 1660 1;
BA_ "GenMsgSendType" BO_ 1659 1;
BA_ "GenMsgSendType" BO_ 1658 1;
BA_ "GenMsgSendType" BO_ 1657 1;
BA_ "GenMsgSendType" BO_ 1656 1;
BA_ "GenMsgSendType" BO_ 1655 1;
BA_ "GenMsgSendType" BO_ 1654 1;
BA_ "GenMsgSendType" BO_ 285 1;
BA_ "GenMsgSendType" BO_ 284 1;
BA_ "GenMsgSendType" BO_ 283 1;
BA_ "GenMsgSendType" BO_ 282 1;
BA_ "GenMsgSendType" BO_ 1653 1;
BA_ "GenMsgSendType" BO_ 1652 1;
BA_ "GenMsgSendType" BO_ 1651 1;
BA_ "GenMsgSendType" BO_ 1650 1;
BA_ "GenMsgSendType" BO_ 1649 1;
BA_ "GenMsgSendType" BO_ 1648 1;
BA_ "GenMsgSendType" BO_ 1647 1;
BA_ "GenMsgSendType" BO_ 1646 1;
BA_ "GenMsgSendType" BO_ 1645 1;
BA_ "GenMsgSendType" BO_ 1644 1;
BA_ "GenMsgSendType" BO_ 1643 1;
BA_ "GenMsgSendType" BO_ 1642 1;
BA_ "GenMsgSendType" BO_ 1641 1;
BA_ "GenMsgSendType" BO_ 1640 1;
BA_ "GenMsgSendType" BO_ 1639 1;
BA_ "GenMsgSendType" BO_ 1638 1;
BA_ "GenMsgSendType" BO_ 1637 1;
BA_ "GenMsgSendType" BO_ 1636 1;
BA_ "GenMsgSendType" BO_ 1635 1;
BA_ "GenMsgSendType" BO_ 1634 1;
BA_ "GenMsgSendType" BO_ 1633 1;
BA_ "GenMsgSendType" BO_ 1632 1;
BA_ "GenMsgSendType" BO_ 1631 1;
BA_ "GenMsgSendType" BO_ 1630 1;
BA_ "GenMsgSendType" BO_ 1629 1;
BA_ "GenMsgSendType" BO_ 1628 1;
BA_ "GenMsgSendType" BO_ 1627 1;
BA_ "GenMsgSendType" BO_ 1626 1;
BA_ "GenMsgSendType" BO_ 1625 1;
BA_ "GenMsgSendType" BO_ 1624 1;
BA_ "GenMsgSendType" BO_ 1623 1;
BA_ "GenMsgSendType" BO_ 1622 1;
BA_ "GenMsgSendType" BO_ 1621 1;
BA_ "GenMsgSendType" BO_ 1620 1;
BA_ "GenMsgSendType" BO_ 1619 1;
BA_ "GenMsgSendType" BO_ 1618 1;
BA_ "GenMsgSendType" BO_ 1617 1;
BA_ "GenMsgSendType" BO_ 1616 1;
BA_ "GenMsgSendType" BO_ 1615 1;
BA_ "GenMsgSendType" BO_ 1614 1;
BA_ "GenMsgSendType" BO_ 281 1;
BA_ "GenMsgSendType" BO_ 280 1;
BA_ "GenMsgSendType" BO_ 279 1;
BA_ "GenMsgSendType" BO_ 278 1;
BA_ "GenMsgSendType" BO_ 1613 1;
BA_ "GenMsgSendType" BO_ 1612 1;
BA_ "GenMsgSendType" BO_ 1611 1;
BA_ "GenMsgSendType" BO_ 1610 1;
BA_ "GenMsgSendType" BO_ 1609 1;
BA_ "GenMsgSendType" BO_ 1608 1;
BA_ "GenMsgSendType" BO_ 1607 1;
BA_ "GenMsgSendType" BO_ 1606 1;
BA_ "GenMsgSendType" BO_ 1605 1;
BA_ "GenMsgSendType" BO_ 1604 1;
BA_ "GenMsgSendType" BO_ 1603 1;
BA_ "GenMsgSendType" BO_ 1602 1;
BA_ "GenMsgSendType" BO_ 1601 1;
BA_ "GenMsgSendType" BO_ 1600 1;
BA_ "GenMsgSendType" BO_ 1599 1;
BA_ "GenMsgSendType" BO_ 1598 1;
BA_ "GenMsgSendType" BO_ 1597 1;
BA_ "GenMsgSendType" BO_ 1596 1;
BA_ "GenMsgSendType" BO_ 1595 1;
BA_ "GenMsgSendType" BO_ 1594 1;
BA_ "GenMsgSendType" BO_ 1593 1;
BA_ "GenMsgSendType" BO_ 1592 1;
BA_ "GenMsgSendType" BO_ 511 1;
BA_ "GenMsgSendType" BO_ 510 1;
BA_ "GenMsgSendType" BO_ 509 1;
BA_ "GenMsgSendType" BO_ 508 1;
BA_ "GenMsgSendType" BO_ 507 1;
BA_ "GenMsgSendType" BO_ 506 1;
BA_ "GenMsgSendType" BO_ 505 1;
BA_ "GenMsgSendType" BO_ 504 1;
BA_ "GenMsgSendType" BO_ 503 1;
BA_ "GenMsgSendType" BO_ 502 1;
BA_ "GenMsgSendType" BO_ 501 1;
BA_ "GenMsgSendType" BO_ 500 1;
BA_ "GenMsgSendType" BO_ 499 1;
BA_ "GenMsgSendType" BO_ 498 1;
BA_ "GenMsgSendType" BO_ 497 1;
BA_ "GenMsgSendType" BO_ 496 1;
BA_ "GenMsgSendType" BO_ 495 1;
BA_ "GenMsgSendType" BO_ 494 1;
BA_ "GenMsgSendType" BO_ 277 1;
BA_ "GenMsgSendType" BO_ 276 1;
BA_ "GenMsgSendType" BO_ 275 1;
BA_ "GenMsgSendType" BO_ 274 1;
BA_ "GenMsgSendType" BO_ 493 1;
BA_ "GenMsgSendType" BO_ 492 1;
BA_ "GenMsgSendType" BO_ 491 1;
BA_ "GenMsgSendType" BO_ 490 1;
BA_ "GenMsgSendType" BO_ 489 1;
BA_ "GenMsgSendType" BO_ 488 1;
BA_ "GenMsgSendType" BO_ 487 1;
BA_ "GenMsgSendType" BO_ 486 1;
BA_ "GenMsgSendType" BO_ 485 1;
BA_ "GenMsgSendType" BO_ 484 1;
BA_ "GenMsgSendType" BO_ 483 1;
BA_ "GenMsgSendType" BO_ 482 1;
BA_ "GenMsgSendType" BO_ 481 1;
BA_ "GenMsgSendType" BO_ 480 1;
BA_ "GenMsgSendType" BO_ 479 1;
BA_ "GenMsgSendType" BO_ 478 1;
BA_ "GenMsgSendType" BO_ 477 1;
BA_ "GenMsgSendType" BO_ 476 1;
BA_ "GenMsgSendType" BO_ 475 1;
BA_ "GenMsgSendType" BO_ 474 1;
BA_ "GenMsgSendType" BO_ 473 1;
BA_ "GenMsgSendType" BO_ 472 1;
BA_ "GenMsgSendType" BO_ 471 1;
BA_ "GenMsgSendType" BO_ 470 1;
BA_ "GenMsgSendType" BO_ 469 1;
BA_ "GenMsgSendType" BO_ 468 1;
BA_ "GenMsgSendType" BO_ 467 1;
BA_ "GenMsgSendType" BO_ 466 1;
BA_ "GenMsgSendType" BO_ 465 1;
BA_ "GenMsgSendType" BO_ 464 1;
BA_ "GenMsgSendType" BO_ 463 1;
BA_ "GenMsgSendType" BO_ 462 1;
BA_ "GenMsgSendType" BO_ 461 1;
BA_ "GenMsgSendType" BO_ 460 1;
BA_ "GenMsgSendType" BO_ 459 1;
BA_ "GenMsgSendType" BO_ 458 1;
BA_ "GenMsgSendType" BO_ 457 1;
BA_ "GenMsgSendType" BO_ 456 1;
BA_ "GenMsgSendType" BO_ 455 1;
BA_ "GenMsgSendType" BO_ 454 1;
BA_ "GenMsgSendType" BO_ 273 1;
BA_ "GenMsgSendType" BO_ 272 1;
